VERSION "dbc-export 1 2026.26.6.5"

NS_ :

BS_:

BU_: ADSP APSB BB CMP DAS DPB EPAS3P EPASTP EPASTS GTW IDB OCS1P PTC RCM RCU TCU TCU2 UDS UI UIS VCLEFT VCSEAT2L VCSEAT2R

BO_ 293 UI_alertMatrix3: 8 UI
 SG_ UI_a129_dgpuOperationFailure : 0|1@1+ (1,0) [0|1] "" Vector__XXX
 SG_ UI_a130_QtCarClusterExitError : 1|1@1+ (1,0) [0|1] "" Vector__XXX
 SG_ UI_a131_DisplayPortFailure : 2|1@1+ (1,0) [0|1] "" Vector__XXX
 SG_ UI_a132_AdspWatchdogRecoveryTrig : 3|1@1+ (1,0) [0|1] "" Vector__XXX
 SG_ UI_a133_AdspWatchdogRecoveryFail : 4|1@1+ (1,0) [0|1] "" Vector__XXX
 SG_ UI_a134_DashcamUsbDriveNoMedium : 5|1@1+ (1,0) [0|1] "" Vector__XXX
 SG_ UI_a135_warnRunOverlayExists : 6|1@1+ (1,0) [0|1] "" Vector__XXX
 SG_ UI_a136_warnSettingsConfExists : 7|1@1+ (1,0) [0|1] "" Vector__XXX
 SG_ UI_a137_ServiceShellActiveConnec : 8|1@1+ (1,0) [0|1] "" Vector__XXX
 SG_ UI_a138_applyingConfigChange : 9|1@1+ (1,0) [0|1] "" Vector__XXX
 SG_ UI_a139_postponedConfigChange : 10|1@1+ (1,0) [0|1] "" Vector__XXX
 SG_ UI_a140_NeverSleepActive : 11|1@1+ (1,0) [0|1] "" Vector__XXX
 SG_ UI_a141_falconDoorOpen : 12|1@1+ (1,0) [0|1] "" Vector__XXX
 SG_ UI_a142_CorrectableMemoryError : 13|1@1+ (1,0) [0|1] "" Vector__XXX
 SG_ UI_a143_FPSCrawling : 14|1@1+ (1,0) [0|1] "" Vector__XXX
 SG_ UI_a144_nvmeWarning : 15|1@1+ (1,0) [0|1] "" Vector__XXX
 SG_ UI_a145_nvmeUnsafeShutdown : 16|1@1+ (1,0) [0|1] "" Vector__XXX
 SG_ UI_a146_nvmeNeedsReplacement : 17|1@1+ (1,0) [0|1] "" Vector__XXX
 SG_ UI_a147_ASILGlobalError : 18|1@1+ (1,0) [0|1] "" Vector__XXX
 SG_ UI_a148_SleepFailure : 19|1@1+ (1,0) [0|1] "" Vector__XXX
 SG_ UI_a149_DisplayCheckFailure : 20|1@1+ (1,0) [0|1] "" Vector__XXX
 SG_ UI_a150_infoCPURunningHot : 21|1@1+ (1,0) [0|1] "" Vector__XXX
 SG_ UI_a151_carComputerThermalProble : 22|1@1+ (1,0) [0|1] "" Vector__XXX
 SG_ UI_a152_infoThrottling : 23|1@1+ (1,0) [0|1] "" Vector__XXX
 SG_ UI_a153_serviceRestarted : 24|1@1+ (1,0) [0|1] "" Vector__XXX
 SG_ UI_a154_AudiodBufferError : 25|1@1+ (1,0) [0|1] "" Vector__XXX
 SG_ UI_a155_UsbFrontHubUnavailable : 26|1@1+ (1,0) [0|1] "" Vector__XXX
 SG_ UI_a156_UsbFrontHubInstallMismat : 27|1@1+ (1,0) [0|1] "" Vector__XXX
 SG_ UI_a157_MCUActiveCoolingRequeste : 28|1@1+ (1,0) [0|1] "" Vector__XXX
 SG_ UI_a158_UsbDeviceMountError : 29|1@1+ (1,0) [0|1] "" Vector__XXX
 SG_ UI_a159_AudioHeartbeatFailure : 30|1@1+ (1,0) [0|1] "" Vector__XXX
 SG_ UI_a160_SystemWatchdogFailure : 31|1@1+ (1,0) [0|1] "" Vector__XXX
 SG_ UI_a161_ECallTemporarilyUnavaila : 32|1@1+ (1,0) [0|1] "" Vector__XXX
 SG_ UI_a162_voiceRecClipsUploaded : 33|1@1+ (1,0) [0|1] "" Vector__XXX
 SG_ UI_a163_QtCarVehicleExitError : 34|1@1+ (1,0) [0|1] "" Vector__XXX
 SG_ UI_a164_AudiodConnTimeout : 35|1@1+ (1,0) [0|1] "" Vector__XXX
 SG_ UI_a165_fsCorrupted : 36|1@1+ (1,0) [0|1] "" Vector__XXX
 SG_ UI_a166_fsError : 37|1@1+ (1,0) [0|1] "" Vector__XXX
 SG_ UI_a167_CgroupOverMemKill : 38|1@1+ (1,0) [0|1] "" Vector__XXX
 SG_ UI_a168_dgpuPowerOnSelfTestFailu : 39|1@1+ (1,0) [0|1] "" Vector__XXX
 SG_ UI_a169_SteamLoadShedFailure : 40|1@1+ (1,0) [0|1] "" Vector__XXX
 SG_ UI_a170_AMDdGPULoadShedFailure : 41|1@1+ (1,0) [0|1] "" Vector__XXX
 SG_ UI_a171_GraphicsLoadShedRequeste : 42|1@1+ (1,0) [0|1] "" Vector__XXX
 SG_ UI_a172_GraphicsLoadShedUIFailur : 43|1@1+ (1,0) [0|1] "" Vector__XXX
 SG_ UI_a173_pmSuspendFailure : 44|1@1+ (1,0) [0|1] "" Vector__XXX
 SG_ UI_a174_HistorySaveLoop : 45|1@1+ (1,0) [0|1] "" Vector__XXX
 SG_ UI_a176_CellularAntennaAlert : 47|1@1+ (1,0) [0|1] "" Vector__XXX
 SG_ UI_a177_MediaPlayerFailure : 48|1@1+ (1,0) [0|1] "" Vector__XXX
 SG_ UI_a178_irqDisabled : 49|1@1+ (1,0) [0|1] "" Vector__XXX
 SG_ UI_a180_AudiodInputRestarted : 51|1@1+ (1,0) [0|1] "" Vector__XXX
 SG_ UI_a181_ModemFirmwareVersionMism : 52|1@1+ (1,0) [0|1] "" Vector__XXX
 SG_ UI_a182_VideoPipelineOverrun : 53|1@1+ (1,0) [0|1] "" Vector__XXX
 SG_ UI_a183_DDAWFaulted : 54|1@1+ (1,0) [0|1] "" Vector__XXX
 SG_ UI_a184_ISAFaulted : 55|1@1+ (1,0) [0|1] "" Vector__XXX
 SG_ UI_a185_ELKSDisabled : 56|1@1+ (1,0) [0|1] "" Vector__XXX
 SG_ UI_a186_ELKSUnavailable : 57|1@1+ (1,0) [0|1] "" Vector__XXX
 SG_ UI_a187_TunerFirmwareMismatchedV : 58|1@1+ (1,0) [0|1] "" Vector__XXX
 SG_ UI_a188_TunerFirmwareMismatchedA : 59|1@1+ (1,0) [0|1] "" Vector__XXX
 SG_ UI_a189_TunerWatchdogReset : 60|1@1+ (1,0) [0|1] "" Vector__XXX
 SG_ UI_a190_TunerMIA : 61|1@1+ (1,0) [0|1] "" Vector__XXX
 SG_ UI_a191_TunerUpdateFailed : 62|1@1+ (1,0) [0|1] "" Vector__XXX
 SG_ UI_a192_AudioWatchdogReboot : 63|1@1+ (1,0) [0|1] "" Vector__XXX

BO_ 294 UI_alertMatrix4: 8 UI
 SG_ UI_a193_TcuRNandFwVersionMismatc : 0|1@1+ (1,0) [0|1] "" Vector__XXX
 SG_ UI_a194_AudioweaverRestarted : 1|1@1+ (1,0) [0|1] "" Vector__XXX
 SG_ UI_a195_gtwMfdUdpApiFired : 2|1@1+ (1,0) [0|1] "" Vector__XXX
 SG_ UI_a196_AMDI2C3BusInoperable : 3|1@1+ (1,0) [0|1] "" Vector__XXX
 SG_ UI_a197_AMDI2C1BusInoperable : 4|1@1+ (1,0) [0|1] "" Vector__XXX
 SG_ UI_a198_IncompatibleBTUSBHubHard : 5|1@1+ (1,0) [0|1] "" Vector__XXX
 SG_ UI_a199_HighAPedalDetectedAtColl : 6|1@1+ (1,0) [0|1] "" Vector__XXX
 SG_ UI_a200_UIFirmwareVersionMismatc : 7|1@1+ (1,0) [0|1] "" Vector__XXX
 SG_ UI_a201_rearDisplayDisconnected : 8|1@1+ (1,0) [0|1] "" Vector__XXX
 SG_ UI_a202_sysMemoryIncorrect : 9|1@1+ (1,0) [0|1] "" Vector__XXX
 SG_ UI_a204_ModemSleepFailure : 11|1@1+ (1,0) [0|1] "" Vector__XXX
 SG_ UI_a205_ModemSleepSignalMismatch : 12|1@1+ (1,0) [0|1] "" Vector__XXX
 SG_ UI_a206_ModemMIAAfterWake : 13|1@1+ (1,0) [0|1] "" Vector__XXX
 SG_ UI_a208_mqttClientDisconnected : 15|1@1+ (1,0) [0|1] "" Vector__XXX
 SG_ UI_a209_dataCallDisconnected : 16|1@1+ (1,0) [0|1] "" Vector__XXX
 SG_ UI_a210_CellularCSRegFail : 17|1@1+ (1,0) [0|1] "" Vector__XXX
 SG_ UI_a211_AEBSDisabled : 18|1@1+ (1,0) [0|1] "" Vector__XXX
 SG_ UI_a212_AEBSFaulted : 19|1@1+ (1,0) [0|1] "" Vector__XXX
 SG_ UI_a213_ISADisabled : 20|1@1+ (1,0) [0|1] "" Vector__XXX
 SG_ UI_a214_pmHelperFailure : 21|1@1+ (1,0) [0|1] "" Vector__XXX
 SG_ UI_a215_compositorStallDetected : 22|1@1+ (1,0) [0|1] "" Vector__XXX
 SG_ UI_a216_AudioA2bCircuitProblem : 23|1@1+ (1,0) [0|1] "" Vector__XXX
 SG_ UI_a217_CgroupMemoryPressure : 24|1@1+ (1,0) [0|1] "" Vector__XXX
 SG_ UI_a218_AudiodNoAudioDevices : 25|1@1+ (1,0) [0|1] "" Vector__XXX
 SG_ UI_a219_CompositorWatchdog : 26|1@1+ (1,0) [0|1] "" Vector__XXX
 SG_ UI_a220_MediaBrowseError : 27|1@1+ (1,0) [0|1] "" Vector__XXX
 SG_ UI_a221_NavigationServiceError : 28|1@1+ (1,0) [0|1] "" Vector__XXX
 SG_ UI_a222_QtCarRestart : 29|1@1+ (1,0) [0|1] "" Vector__XXX
 SG_ UI_a223_databaseError : 30|1@1+ (1,0) [0|1] "" Vector__XXX
 SG_ UI_a224_centerDisplayDisconnecte : 31|1@1+ (1,0) [0|1] "" Vector__XXX
 SG_ UI_a225_clusterDisplayDisconnect : 32|1@1+ (1,0) [0|1] "" Vector__XXX
 SG_ UI_a226_largePhoneContactSync : 33|1@1+ (1,0) [0|1] "" Vector__XXX
 SG_ UI_a228_pipewireXrunBurst : 35|1@1+ (1,0) [0|1] "" Vector__XXX
 SG_ UI_a229_SerDesError : 36|1@1+ (1,0) [0|1] "" Vector__XXX
 SG_ UI_a230_ModemSimCardMismatch : 37|1@1+ (1,0) [0|1] "" Vector__XXX
 SG_ UI_a231_SleepCancelled : 38|1@1+ (1,0) [0|1] "" Vector__XXX
 SG_ UI_a232_processExitError : 39|1@1+ (1,0) [0|1] "" Vector__XXX
 SG_ UI_a233_ModemRFFailure : 40|1@1+ (1,0) [0|1] "" Vector__XXX
 SG_ UI_a234_AMDI2C0Timeout : 41|1@1+ (1,0) [0|1] "" Vector__XXX
 SG_ UI_a235_AMDI2C1Timeout : 42|1@1+ (1,0) [0|1] "" Vector__XXX
 SG_ UI_a236_ModemOnResetState : 43|1@1+ (1,0) [0|1] "" Vector__XXX
 SG_ UI_a237_ClipUploadActive : 44|1@1+ (1,0) [0|1] "" Vector__XXX
 SG_ UI_a238_ModemConfigMismatch : 45|1@1+ (1,0) [0|1] "" Vector__XXX
 SG_ UI_a240_ethError : 47|1@1+ (1,0) [0|1] "" Vector__XXX
 SG_ UI_a241_AxCPError : 48|1@1+ (1,0) [0|1] "" Vector__XXX
 SG_ UI_a242_uiHealthFaultInjectionAc : 49|1@1+ (1,0) [0|1] "" Vector__XXX
 SG_ UI_a243_pmDisplayCheckFailure : 50|1@1+ (1,0) [0|1] "" Vector__XXX
 SG_ UI_a244_segfault : 51|1@1+ (1,0) [0|1] "" Vector__XXX
 SG_ UI_a245_taskHung : 52|1@1+ (1,0) [0|1] "" Vector__XXX
 SG_ UI_a246_gpuFenceTimeout : 53|1@1+ (1,0) [0|1] "" Vector__XXX
 SG_ UI_a247_StalklessDisplayBackligh : 54|1@1+ (1,0) [0|1] "" Vector__XXX
 SG_ UI_a252_TPMErrorReceive : 59|1@1+ (1,0) [0|1] "" Vector__XXX
 SG_ UI_a253_maintenanceHistoryRecord : 60|1@1+ (1,0) [0|1] "" Vector__XXX
 SG_ UI_a254_appCertificateExpired : 61|1@1+ (1,0) [0|1] "" Vector__XXX
 SG_ UI_a255_apbCertificateExpired : 62|1@1+ (1,0) [0|1] "" Vector__XXX
 SG_ UI_a256_sapFailedToEnable : 63|1@1+ (1,0) [0|1] "" Vector__XXX

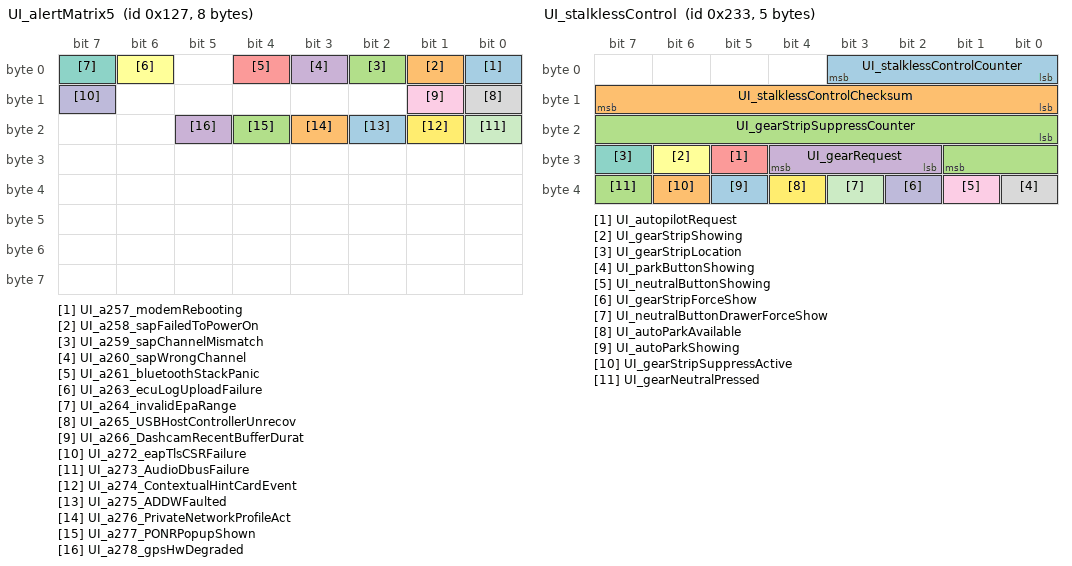
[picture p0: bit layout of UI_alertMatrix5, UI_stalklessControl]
BO_ 295 UI_alertMatrix5: 8 UI
 SG_ UI_a257_modemRebooting : 0|1@1+ (1,0) [0|1] "" Vector__XXX
 SG_ UI_a258_sapFailedToPowerOn : 1|1@1+ (1,0) [0|1] "" Vector__XXX
 SG_ UI_a259_sapChannelMismatch : 2|1@1+ (1,0) [0|1] "" Vector__XXX
 SG_ UI_a260_sapWrongChannel : 3|1@1+ (1,0) [0|1] "" Vector__XXX
 SG_ UI_a261_bluetoothStackPanic : 4|1@1+ (1,0) [0|1] "" Vector__XXX
 SG_ UI_a263_ecuLogUploadFailure : 6|1@1+ (1,0) [0|1] "" Vector__XXX
 SG_ UI_a264_invalidEpaRange : 7|1@1+ (1,0) [0|1] "" Vector__XXX
 SG_ UI_a265_USBHostControllerUnrecov : 8|1@1+ (1,0) [0|1] "" Vector__XXX
 SG_ UI_a266_DashcamRecentBufferDurat : 9|1@1+ (1,0) [0|1] "" Vector__XXX
 SG_ UI_a272_eapTlsCSRFailure : 15|1@1+ (1,0) [0|1] "" Vector__XXX
 SG_ UI_a273_AudioDbusFailure : 16|1@1+ (1,0) [0|1] "" Vector__XXX
 SG_ UI_a274_ContextualHintCardEvent : 17|1@1+ (1,0) [0|1] "" Vector__XXX
 SG_ UI_a275_ADDWFaulted : 18|1@1+ (1,0) [0|1] "" Vector__XXX
 SG_ UI_a276_PrivateNetworkProfileAct : 19|1@1+ (1,0) [0|1] "" Vector__XXX
 SG_ UI_a277_PONRPopupShown : 20|1@1+ (1,0) [0|1] "" Vector__XXX
 SG_ UI_a278_gpsHwDegraded : 21|1@1+ (1,0) [0|1] "" Vector__XXX

BO_ 1279 UI_energyConsumptionInfo: 8 UI
 SG_ UI_energyConsumptionInfoIndex M : 0|5@1+ (1,0) [0|31] "" Vector__XXX
 SG_ UI_energyLossTotal_epa m0 : 16|16@1- (1,0) [-32768|32767] "Wh" Vector__XXX
 SG_ UI_energyLossDriving_epa m0 : 32|16@1- (1,0) [-32768|32767] "Wh" Vector__XXX
 SG_ UI_energyLossClimate_epa m0 : 48|16@1- (1,0) [-32768|32767] "Wh" Vector__XXX
 SG_ UI_energyLossBattCond_epa m1 : 16|16@1- (1,0) [-32768|32767] "Wh" Vector__XXX
 SG_ UI_energyLossElevation_epa m1 : 32|16@1- (1,0) [-32768|32767] "Wh" Vector__XXX
 SG_ UI_energyLossAcc_epa m1 : 48|16@1- (1,0) [-32768|32767] "Wh" Vector__XXX
 SG_ UI_energyLossTotalSinceCharge_ep m2 : 16|16@1- (1,0) [-32768|32767] "Wh" Vector__XXX
 SG_ UI_energyLossDrivingSinceCharge_ m2 : 32|16@1- (1,0) [-32768|32767] "Wh" Vector__XXX
 SG_ UI_energyLossClimateSinceCharge_ m2 : 48|16@1- (1,0) [-32768|32767] "Wh" Vector__XXX
 SG_ UI_energyLossBattCondSinceCharge m3 : 16|16@1- (1,0) [-32768|32767] "Wh" Vector__XXX
 SG_ UI_energyLossElevationSinceCharg m3 : 32|16@1- (1,0) [-32768|32767] "Wh" Vector__XXX
 SG_ UI_energyLossAccSinceCharge_epa m3 : 48|16@1- (1,0) [-32768|32767] "Wh" Vector__XXX
 SG_ UI_energyLossTotalSinceTripStart m4 : 16|16@1- (1,0) [-32768|32767] "Wh" Vector__XXX
 SG_ UI_energyLossDrivingSinceTripSta m4 : 32|16@1- (1,0) [-32768|32767] "Wh" Vector__XXX
 SG_ UI_energyLossClimateSinceTripSta m4 : 48|16@1- (1,0) [-32768|32767] "Wh" Vector__XXX
 SG_ UI_energyLossBattCondSinceTripSt m5 : 16|16@1- (1,0) [-32768|32767] "Wh" Vector__XXX
 SG_ UI_energyLossElevationSinceTripS m5 : 32|16@1- (1,0) [-32768|32767] "Wh" Vector__XXX
 SG_ UI_energyLossAccSinceTripStart m5 : 48|16@1- (1,0) [-32768|32767] "Wh" Vector__XXX
 SG_ UI_energyDeltaTotal_epa m6 : 16|16@1- (1,0) [-32768|32767] "Wh" Vector__XXX
 SG_ UI_energyDeltaDriving_epa m6 : 32|16@1- (1,0) [-32768|32767] "Wh" Vector__XXX
 SG_ UI_energyDeltaClimate_epa m6 : 48|16@1- (1,0) [-32768|32767] "Wh" Vector__XXX
 SG_ UI_energyDeltaBattCond_epa m7 : 16|16@1- (1,0) [-32768|32767] "Wh" Vector__XXX
 SG_ UI_energyDeltaElevation_epa m7 : 32|16@1- (1,0) [-32768|32767] "Wh" Vector__XXX
 SG_ UI_energyDeltaAcc_epa m7 : 48|16@1- (1,0) [-32768|32767] "Wh" Vector__XXX
 SG_ UI_uiDeltaOffsetTotal_epa m8 : 16|16@1- (1,0) [-32768|32767] "Wh" Vector__XXX
 SG_ UI_uiDeltaOffsetDriving_epa m8 : 32|16@1- (1,0) [-32768|32767] "Wh" Vector__XXX
 SG_ UI_uiDeltaOffsetClimate_epa m8 : 48|16@1- (1,0) [-32768|32767] "Wh" Vector__XXX
 SG_ UI_uiDeltaOffsetBattCond_epa m9 : 16|16@1- (1,0) [-32768|32767] "Wh" Vector__XXX
 SG_ UI_uiDeltaOffsetElevation_epa m9 : 32|16@1- (1,0) [-32768|32767] "Wh" Vector__XXX
 SG_ UI_uiDeltaOffsetAcc_epa m9 : 48|16@1- (1,0) [-32768|32767] "Wh" Vector__XXX
 SG_ UI_rawToUiEnergyRatio_epa m10 : 8|8@1+ (0.01,0) [0|2.55] "-" Vector__XXX
 SG_ UI_driveDistance_epa m10 : 16|16@1+ (0.01,0) [0|655.35] "miles" Vector__XXX
 SG_ UI_energyDeltaTotalSinceCharge_e m11 : 16|16@1- (1,0) [-32768|32767] "Wh" Vector__XXX
 SG_ UI_energyDeltaDrivingSinceCharge m11 : 32|16@1- (1,0) [-32768|32767] "Wh" Vector__XXX
 SG_ UI_energyDeltaClimateSinceCharge m11 : 48|16@1- (1,0) [-32768|32767] "Wh" Vector__XXX
 SG_ UI_energyDeltaBattCondSinceCharg m12 : 16|16@1- (1,0) [-32768|32767] "Wh" Vector__XXX
 SG_ UI_energyDeltaElevationSinceChar m12 : 32|16@1- (1,0) [-32768|32767] "Wh" Vector__XXX
 SG_ UI_energyDeltaAccSinceCharge_epa m12 : 48|16@1- (1,0) [-32768|32767] "Wh" Vector__XXX
 SG_ UI_uiDeltaOffsetTotalSinceCharge m13 : 16|16@1- (1,0) [-32768|32767] "Wh" Vector__XXX
 SG_ UI_uiDeltaOffsetDrivingSinceChar m13 : 32|16@1- (1,0) [-32768|32767] "Wh" Vector__XXX
 SG_ UI_uiDeltaOffsetClimateSinceChar m13 : 48|16@1- (1,0) [-32768|32767] "Wh" Vector__XXX
 SG_ UI_uiDeltaOffsetBattCondSinceCha m14 : 16|16@1- (1,0) [-32768|32767] "Wh" Vector__XXX
 SG_ UI_uiDeltaOffsetElevationSinceCh m14 : 32|16@1- (1,0) [-32768|32767] "Wh" Vector__XXX
 SG_ UI_uiDeltaOffsetAccSinceCharge_e m14 : 48|16@1- (1,0) [-32768|32767] "Wh" Vector__XXX
 SG_ UI_rawToUiEnergyRatioSinceCharge m15 : 8|8@1+ (0.01,0) [0|2.55] "-" Vector__XXX
 SG_ UI_driveDistanceSinceCharge_epa m15 : 16|16@1+ (0.01,0) [0|655.35] "miles" Vector__XXX
 SG_ UI_energyDeltaTotalSinceTripStar m16 : 16|16@1- (1,0) [-32768|32767] "Wh" Vector__XXX
 SG_ UI_energyDeltaDrivingSinceTripSt m16 : 32|16@1- (1,0) [-32768|32767] "Wh" Vector__XXX
 SG_ UI_energyDeltaClimateSinceTripSt m16 : 48|16@1- (1,0) [-32768|32767] "Wh" Vector__XXX
 SG_ UI_energyDeltaBattCondSinceTripS m17 : 16|16@1- (1,0) [-32768|32767] "Wh" Vector__XXX
 SG_ UI_energyDeltaElevationSinceTrip m17 : 32|16@1- (1,0) [-32768|32767] "Wh" Vector__XXX
 SG_ UI_energyDeltaAccSinceTripStart m17 : 48|16@1- (1,0) [-32768|32767] "Wh" Vector__XXX
 SG_ UI_uiDeltaOffsetTotalSinceTripSt m18 : 16|16@1- (1,0) [-32768|32767] "Wh" Vector__XXX
 SG_ UI_uiDeltaOffsetDrivingSinceTrip m18 : 32|16@1- (1,0) [-32768|32767] "Wh" Vector__XXX
 SG_ UI_uiDeltaOffsetClimateSinceTrip m18 : 48|16@1- (1,0) [-32768|32767] "Wh" Vector__XXX
 SG_ UI_uiDeltaOffsetBattCondSinceTri m19 : 16|16@1- (1,0) [-32768|32767] "Wh" Vector__XXX
 SG_ UI_uiDeltaOffsetElevationSinceTr m19 : 32|16@1- (1,0) [-32768|32767] "Wh" Vector__XXX
 SG_ UI_uiDeltaOffsetAccSinceTripStar m19 : 48|16@1- (1,0) [-32768|32767] "Wh" Vector__XXX
 SG_ UI_rawToUiEnergyRatioSinceTripSt m20 : 8|8@1+ (0.01,0) [0|2.55] "-" Vector__XXX
 SG_ UI_driveDistanceSinceTripStart m20 : 16|16@1+ (0.01,0) [0|655.35] "miles" Vector__XXX
 SG_ UI_voyagerEnabled m21 : 5|1@1+ (1,0) [0|1] "" Vector__XXX
 SG_ UI_trailerMass m21 : 16|16@1+ (1,0) [0|65535] "kg" Vector__XXX

BO_ 993 UI_gearSliderInfo: 8 UI
 SG_ UI_gearSliderInfoIndex M : 0|2@1+ (1,0) [0|3] "" Vector__XXX
 SG_ UI_gearSliderW m0 : 2|14@1+ (1,0) [0|16383] "" Vector__XXX
 SG_ UI_gearSliderH m0 : 16|16@1+ (1,0) [0|65535] "" Vector__XXX
 SG_ UI_gearSliderX m0 : 32|16@1+ (1,0) [0|65535] "" Vector__XXX
 SG_ UI_gearSliderY m0 : 48|16@1+ (1,0) [0|65535] "" Vector__XXX
 SG_ UI_gearParkW m1 : 2|14@1+ (1,0) [0|16383] "" Vector__XXX
 SG_ UI_gearParkH m1 : 16|16@1+ (1,0) [0|65535] "" Vector__XXX
 SG_ UI_gearParkX m1 : 32|16@1+ (1,0) [0|65535] "" Vector__XXX
 SG_ UI_gearParkY m1 : 48|16@1+ (1,0) [0|65535] "" Vector__XXX
 SG_ UI_gearNeutralW m2 : 2|14@1+ (1,0) [0|16383] "" Vector__XXX
 SG_ UI_gearNeutralH m2 : 16|16@1+ (1,0) [0|65535] "" Vector__XXX
 SG_ UI_gearNeutralX m2 : 32|16@1+ (1,0) [0|65535] "" Vector__XXX
 SG_ UI_gearNeutralY m2 : 48|16@1+ (1,0) [0|65535] "" Vector__XXX

BO_ 666 UI_seatControl: 3 UI
 SG_ UI_seatControlIndex M : 0|2@1+ (1,0) [0|3] "" Vector__XXX
 SG_ UI_3RSeatChildLock m0 : 2|2@1+ (1,0) [0|3] "" Vector__XXX
 SG_ UI_2RowLeftSeatTrackBack m0 : 4|1@1+ (1,0) [0|1] "" Vector__XXX
 SG_ UI_2RowLeftSeatTrackForward m0 : 5|1@1+ (1,0) [0|1] "" Vector__XXX
 SG_ UI_2RowRightSeatTrackBack m0 : 6|1@1+ (1,0) [0|1] "" Vector__XXX
 SG_ UI_2RowRightSeatTrackForward m0 : 7|1@1+ (1,0) [0|1] "" Vector__XXX
 SG_ UI_left3RowSeatAdjustmentRequest m0 : 8|3@1+ (1,0) [0|7] "" Vector__XXX
 SG_ UI_right3RowSeatAdjustmentReques m0 : 11|3@1+ (1,0) [0|7] "" Vector__XXX
 SG_ UI_2RLeftSeatFanReq m0 : 14|2@1+ (1,0) [0|3] "" Vector__XXX
 SG_ UI_2RRightSeatFanReq m0 : 16|2@1+ (1,0) [0|3] "" Vector__XXX
 SG_ UI_leftThirdRowSeatRequestFromRe m0 : 18|1@1+ (1,0) [0|1] "" Vector__XXX
 SG_ UI_rightThirdRowSeatRequestFromR m0 : 19|1@1+ (1,0) [0|1] "" Vector__XXX
 SG_ UI_seatChoreographyStopRequest m0 : 20|1@1+ (1,0) [0|1] "" Vector__XXX

BO_ 563 UI_stalklessControl: 5 UI
 SG_ UI_stalklessControlCounter : 0|4@1+ (1,0) [0|15] "" Vector__XXX
 SG_ UI_stalklessControlChecksum : 8|8@1+ (1,0) [0|255] "" Vector__XXX
 SG_ UI_gearStripSuppressCounter : 16|10@1+ (1,0) [0|1023] "" Vector__XXX
 SG_ UI_gearRequest : 26|3@1+ (1,0) [1|7] "" Vector__XXX
 SG_ UI_autopilotRequest : 29|1@1+ (1,0) [0|1] "" Vector__XXX
 SG_ UI_gearStripShowing : 30|1@1+ (1,0) [0|1] "" Vector__XXX
 SG_ UI_gearStripLocation : 31|1@1+ (1,0) [0|1] "" Vector__XXX
 SG_ UI_parkButtonShowing : 32|1@1+ (1,0) [0|1] "" Vector__XXX
 SG_ UI_neutralButtonShowing : 33|1@1+ (1,0) [0|1] "" Vector__XXX
 SG_ UI_gearStripForceShow : 34|1@1+ (1,0) [0|1] "" Vector__XXX
 SG_ UI_neutralButtonDrawerForceShow : 35|1@1+ (1,0) [0|1] "" Vector__XXX
 SG_ UI_autoParkAvailable : 36|1@1+ (1,0) [0|1] "" Vector__XXX
 SG_ UI_autoParkShowing : 37|1@1+ (1,0) [0|1] "" Vector__XXX
 SG_ UI_gearStripSuppressActive : 38|1@1+ (1,0) [0|1] "" Vector__XXX
 SG_ UI_gearNeutralPressed : 39|1@1+ (1,0) [0|1] "" Vector__XXX

BO_ 986 UI_status3: 1 UI
 SG_ UI_wifiRegDomain : 0|7@1+ (1,0) [0|127] "" Vector__XXX
 SG_ UI_wifiTethered : 7|1@1+ (1,0) [0|1] "" Vector__XXX

BO_ 661 UI_systemMonitor: 8 UI
 SG_ UI_systemMonitorIndex M : 0|1@1+ (1,0) [0|1] "" Vector__XXX
 SG_ UI_SystemMemUsage m0 : 8|16@1+ (1,0) [0|65535] "MB" Vector__XXX
 SG_ UI_QtCarMemUsage m0 : 24|16@1+ (1,0) [0|65535] "MB" Vector__XXX
 SG_ UI_QtCarCPUUsage m0 : 40|7@1+ (1,0) [0|127] "%" Vector__XXX
 SG_ UI_emmcStatus m0 : 47|1@1+ (1,0) [0|1] "" Vector__XXX
 SG_ UI_SystemCPUUsage m0 : 48|7@1+ (1,0) [0|127] "%" Vector__XXX
 SG_ UI_HomeHealth m0 : 55|1@1+ (1,0) [0|1] "" Vector__XXX
 SG_ UI_VarHealth m0 : 56|1@1+ (1,0) [0|1] "" Vector__XXX
 SG_ UI_LogHealth m0 : 57|1@1+ (1,0) [0|1] "" Vector__XXX
 SG_ UI_TmpfsHealth m0 : 58|1@1+ (1,0) [0|1] "" Vector__XXX
 SG_ UI_emmcDataWritten m1 : 8|24@1+ (1,0) [0|16777215] "" Vector__XXX
 SG_ UI_emmcTotalErases m1 : 32|16@1+ (1,0) [0|65535] "" Vector__XXX

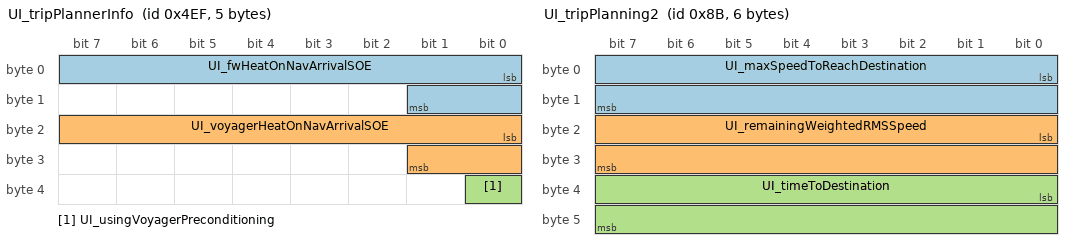
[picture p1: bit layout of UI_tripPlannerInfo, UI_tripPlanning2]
BO_ 1263 UI_tripPlannerInfo: 5 UI
 SG_ UI_fwHeatOnNavArrivalSOE : 0|10@1+ (0.1,0) [0|100] "%" Vector__XXX
 SG_ UI_voyagerHeatOnNavArrivalSOE : 16|10@1+ (0.1,0) [0|100] "%" Vector__XXX
 SG_ UI_usingVoyagerPreconditioning : 32|1@1+ (1,0) [0|1] "" Vector__XXX

BO_ 139 UI_tripPlanning2: 6 UI
 SG_ UI_maxSpeedToReachDestination : 0|16@1+ (0.01,0) [0|655.34] "m/s" Vector__XXX
 SG_ UI_remainingWeightedRMSSpeed : 16|16@1+ (0.01,0) [0|655.34] "m/s" Vector__XXX
 SG_ UI_timeToDestination : 32|16@1+ (1,0) [0|65534] "s" Vector__XXX

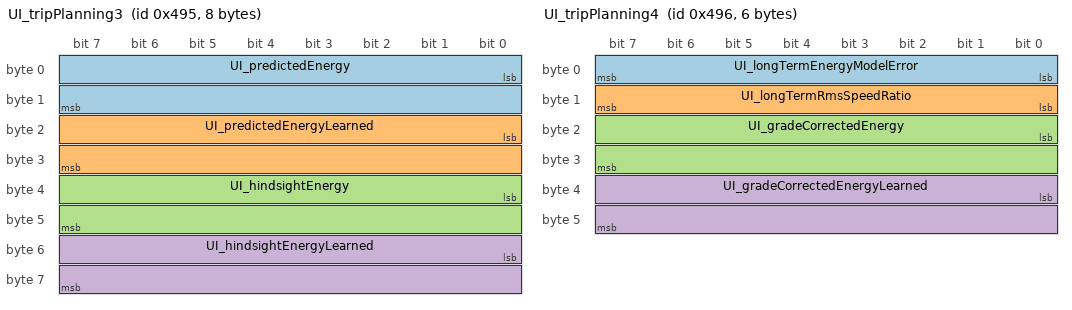
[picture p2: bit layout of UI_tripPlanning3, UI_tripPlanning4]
BO_ 1173 UI_tripPlanning3: 8 UI
 SG_ UI_predictedEnergy : 0|16@1- (0.01,0) [-327.67|327.67] "kWh" Vector__XXX
 SG_ UI_predictedEnergyLearned : 16|16@1- (0.01,0) [-327.68|327.67] "kWh" Vector__XXX
 SG_ UI_hindsightEnergy : 32|16@1- (0.01,0) [-327.67|327.67] "kWh" Vector__XXX
 SG_ UI_hindsightEnergyLearned : 48|16@1- (0.01,0) [-327.68|327.67] "kWh" Vector__XXX

BO_ 1174 UI_tripPlanning4: 6 UI
 SG_ UI_longTermEnergyModelError : 0|8@1- (0.5,0) [-64|63.5] "whpm" Vector__XXX
 SG_ UI_longTermRmsSpeedRatio : 8|8@1+ (0.01,0) [0|2.54] "1" Vector__XXX
 SG_ UI_gradeCorrectedEnergy : 16|16@1- (0.01,0) [-327.68|327.67] "kWh" Vector__XXX
 SG_ UI_gradeCorrectedEnergyLearned : 32|16@1- (0.01,0) [-327.68|327.67] "kWh" Vector__XXX

BO_ 1175 UI_tripPlanning5: 4 UI
 SG_ UI_battPreconditionOnNavTime : 0|16@1+ (1,0) [0|65534] "s" Vector__XXX
 SG_ UI_maxBattPreconditionOnNavTime : 16|16@1+ (1,0) [0|65534] "s" Vector__XXX

BO_ 649 VCLEFT_logging10Hz: 8 VCLEFT
 SG_ VCLEFT_logging10HzIndex M : 0|1@1+ (1,0) [0|1] "" Vector__XXX
 SG_ VCLEFT_hvacBlowerRs m0 : 1|8@1+ (0.25,0) [0|60] "mOhm" Vector__XXX
 SG_ VCLEFT_hvacBlowerIPhase0 m0 : 9|7@1+ (0.4,0) [0|50] "A" Vector__XXX
 SG_ VCLEFT_hvacBlowerIPhase1 m0 : 16|7@1+ (0.4,0) [0|50] "A" Vector__XXX
 SG_ VCLEFT_hvacBlowerIPhase2 m0 : 23|7@1+ (0.4,0) [0|50] "A" Vector__XXX
 SG_ VCLEFT_hvacBlower_IO_CBC_HEAD m0 : 30|4@1+ (1,0) [0|15] "" Vector__XXX
 SG_ VCLEFT_hvacBlower_IO_CBC_TAIL m0 : 34|4@1+ (1,0) [0|15] "" Vector__XXX
 SG_ VCLEFT_hvacBlower_IO_CBC_TAIL_va m0 : 38|1@1+ (1,0) [0|1] "" Vector__XXX
 SG_ VCLEFT_hvacBlower_IO_CBC_Status m0 : 39|1@1+ (1,0) [0|1] "" Vector__XXX
 SG_ VCLEFT_hvacBlower_IO_CBC_numUart m0 : 40|8@1+ (1,0) [0|255] "" Vector__XXX
 SG_ VCLEFT_hvacBlowerCBCEstState m0 : 48|4@1+ (1,0) [0|15] "" Vector__XXX
 SG_ VCLEFT_hvacBlowerCBCCtrlState m0 : 52|3@1+ (1,0) [0|7] "" Vector__XXX
 SG_ VCLEFT_hvacBlowerITerm m0 : 55|7@1+ (0.05,-1.5) [-1.5|4.5] "Nm" Vector__XXX
 SG_ VCLEFT_hvacBlowerSpiError m0 : 62|1@1+ (1,0) [0|1] "" Vector__XXX
 SG_ VCLEFT_hvacBlowerRsOnlineActive m0 : 63|1@1+ (1,0) [0|1] "" Vector__XXX

BO_ 1336 VCSEAT2L_alertLog: 8 VCSEAT2L
 SG_ VCSEAT2L_alertID M : 0|15@1+ (1,0) [0|32767] "" Vector__XXX
 SG_ VCSEAT2L_alertState : 15|1@1+ (1,0) [0|1] "" Vector__XXX
 SG_ VCSEAT2L_a001_InternalWatchdog m1 : 16|1@1+ (1,0) [0|1] "" Vector__XXX
 SG_ VCSEAT2L_a010_UnderVoltDetected m10 : 16|1@1+ (1,0) [0|1] "" Vector__XXX
 SG_ VCSEAT2L_a010_UnderVoltTimeout m10 : 17|1@1+ (1,0) [0|1] "" Vector__XXX
 SG_ VCSEAT2L_a015_NVMMMemOverflow m15 : 16|1@1+ (1,0) [0|1] "" Vector__XXX
 SG_ VCSEAT2L_a015_NVMMFilesystemErro m15 : 17|1@1+ (1,0) [0|1] "" Vector__XXX
 SG_ VCSEAT2L_a015_NVMMRecordIDError m15 : 18|1@1+ (1,0) [0|1] "" Vector__XXX
 SG_ VCSEAT2L_a057_VEH_cpControl m57 : 16|1@1+ (1,0) [0|1] "" Vector__XXX
 SG_ VCSEAT2L_a059_voltageDrop m59 : 16|12@1+ (0.005443676,0) [0|22.29185322] "V" Vector__XXX
 SG_ VCSEAT2L_a059_resistanceEstimate m59 : 28|12@1+ (0.00244,0) [0|9.9918] "Ohms" Vector__XXX
 SG_ VCSEAT2L_a059_current m59 : 40|12@1+ (0.05,0) [0|204.75] "A" Vector__XXX
 SG_ VCSEAT2L_a063_switchChannel m63 : 16|8@1+ (1,0) [0|255] "" Vector__XXX
 SG_ VCSEAT2L_a063_switchType m63 : 24|8@1+ (1,0) [0|255] "" Vector__XXX
 SG_ VCSEAT2L_a063_ADCVoltage m63 : 32|8@1+ (0.025,0) [0|6.375] "V" Vector__XXX
 SG_ VCSEAT2L_a063_disconnected m63 : 40|1@1+ (1,0) [0|1] "" Vector__XXX
 SG_ VCSEAT2L_a063_indeterminate m63 : 41|1@1+ (1,0) [0|1] "" Vector__XXX
 SG_ VCSEAT2L_a063_stuckActive m63 : 42|1@1+ (1,0) [0|1] "" Vector__XXX
 SG_ VCSEAT2L_a063_faulted m63 : 43|1@1+ (1,0) [0|1] "" Vector__XXX
 SG_ VCSEAT2L_a082_RIPC_epbPrivateSta m82 : 16|1@1+ (1,0) [0|1] "" Vector__XXX
 SG_ VCSEAT2L_a082_RIPC_remoteHSD m82 : 17|1@1+ (1,0) [0|1] "" Vector__XXX
 SG_ VCSEAT2L_a082_RIPC_railStatus m82 : 18|1@1+ (1,0) [0|1] "" Vector__XXX
 SG_ VCSEAT2L_a082_RIPC_remoteMux m82 : 19|1@1+ (1,0) [0|1] "" Vector__XXX
 SG_ VCSEAT2L_a083_LIPC_epbPrivateSta m83 : 16|1@1+ (1,0) [0|1] "" Vector__XXX
 SG_ VCSEAT2L_a083_LIPC_remoteHSD m83 : 17|1@1+ (1,0) [0|1] "" Vector__XXX
 SG_ VCSEAT2L_a083_LIPC_railStatus m83 : 18|1@1+ (1,0) [0|1] "" Vector__XXX
 SG_ VCSEAT2L_a083_LIPC_HSDFaults m83 : 19|1@1+ (1,0) [0|1] "" Vector__XXX
 SG_ VCSEAT2L_a084_CH_StatusC m84 : 16|1@1+ (1,0) [0|1] "" Vector__XXX
 SG_ VCSEAT2L_a085_PARTY_buttonStatus m85 : 16|1@1+ (1,0) [0|1] "" Vector__XXX
 SG_ VCSEAT2L_a086_VEH_LVBMS_statusHi m86 : 16|1@1+ (1,0) [0|1] "" Vector__XXX
 SG_ VCSEAT2L_a086_VEH_LVBMS_statusLo m86 : 17|1@1+ (1,0) [0|1] "" Vector__XXX
 SG_ VCSEAT2L_a086_VEH_status m86 : 18|1@1+ (1,0) [0|1] "" Vector__XXX
 SG_ VCSEAT2L_a086_VEH_12VBatteryStat m86 : 19|1@1+ (1,0) [0|1] "" Vector__XXX
 SG_ VCSEAT2L_a086_VEH_LVPowerState m86 : 20|1@1+ (1,0) [0|1] "" Vector__XXX
 SG_ VCSEAT2L_a086_VEH_lightStatus m86 : 21|1@1+ (1,0) [0|1] "" Vector__XXX
 SG_ VCSEAT2L_a086_VEH_systemStatus m86 : 22|1@1+ (1,0) [0|1] "" Vector__XXX
 SG_ VCSEAT2L_a086_VEH_thermalStatus m86 : 23|1@1+ (1,0) [0|1] "" Vector__XXX
 SG_ VCSEAT2L_a086_VEH_vehNm m86 : 24|1@1+ (1,0) [0|1] "" Vector__XXX
 SG_ VCSEAT2L_a087_VEH_temperature m87 : 16|1@1+ (1,0) [0|1] "" Vector__XXX
 SG_ VCSEAT2L_a087_VEH_thermalControl m87 : 17|1@1+ (1,0) [0|1] "" Vector__XXX
 SG_ VCSEAT2L_a087_VEH_torque m87 : 18|1@1+ (1,0) [0|1] "" Vector__XXX
 SG_ VCSEAT2L_a087_VEH_status m87 : 19|1@1+ (1,0) [0|1] "" Vector__XXX
 SG_ VCSEAT2L_a087_PARTY_torque m87 : 20|1@1+ (1,0) [0|1] "" Vector__XXX
 SG_ VCSEAT2L_a087_PARTY_status m87 : 21|1@1+ (1,0) [0|1] "" Vector__XXX
 SG_ VCSEAT2L_a087_PARTY_temperature m87 : 22|1@1+ (1,0) [0|1] "" Vector__XXX
 SG_ VCSEAT2L_a087_PARTY_thermalContr m87 : 23|1@1+ (1,0) [0|1] "" Vector__XXX
 SG_ VCSEAT2L_a087_VEH_motorStatus m87 : 24|1@1+ (1,0) [0|1] "" Vector__XXX
 SG_ VCSEAT2L_a088_VEH_temperature m88 : 16|1@1+ (1,0) [0|1] "" Vector__XXX
 SG_ VCSEAT2L_a088_VEH_thermalControl m88 : 17|1@1+ (1,0) [0|1] "" Vector__XXX
 SG_ VCSEAT2L_a088_VEH_torque m88 : 18|1@1+ (1,0) [0|1] "" Vector__XXX
 SG_ VCSEAT2L_a088_VEH_status m88 : 19|1@1+ (1,0) [0|1] "" Vector__XXX
 SG_ VCSEAT2L_a088_PARTY_torque m88 : 20|1@1+ (1,0) [0|1] "" Vector__XXX
 SG_ VCSEAT2L_a088_PARTY_status m88 : 21|1@1+ (1,0) [0|1] "" Vector__XXX
 SG_ VCSEAT2L_a088_PARTY_temperature m88 : 22|1@1+ (1,0) [0|1] "" Vector__XXX
 SG_ VCSEAT2L_a088_PARTY_thermalContr m88 : 23|1@1+ (1,0) [0|1] "" Vector__XXX
 SG_ VCSEAT2L_a088_VEH_motorStatus m88 : 24|1@1+ (1,0) [0|1] "" Vector__XXX
 SG_ VCSEAT2L_a089_PARTY_party1 m89 : 16|1@1+ (1,0) [0|1] "" Vector__XXX
 SG_ VCSEAT2L_a089_PARTY_status m89 : 17|1@1+ (1,0) [0|1] "" Vector__XXX
 SG_ VCSEAT2L_a089_VEH_status m89 : 18|1@1+ (1,0) [0|1] "" Vector__XXX
 SG_ VCSEAT2L_a089_BDY_party1 m89 : 19|1@1+ (1,0) [0|1] "" Vector__XXX
 SG_ VCSEAT2L_a089_BDY_status m89 : 20|1@1+ (1,0) [0|1] "" Vector__XXX
 SG_ VCSEAT2L_a089_CH_status m89 : 21|1@1+ (1,0) [0|1] "" Vector__XXX
 SG_ VCSEAT2L_a089_CH_party1 m89 : 22|1@1+ (1,0) [0|1] "" Vector__XXX
 SG_ VCSEAT2L_a089_CH_party3 m89 : 23|1@1+ (1,0) [0|1] "" Vector__XXX
 SG_ VCSEAT2L_a089_VEH_party1 m89 : 24|1@1+ (1,0) [0|1] "" Vector__XXX
 SG_ VCSEAT2L_a089_VEH_party3 m89 : 25|1@1+ (1,0) [0|1] "" Vector__XXX
 SG_ VCSEAT2L_a091_VEH_faultsAndExtra m91 : 16|1@1+ (1,0) [0|1] "" Vector__XXX
 SG_ VCSEAT2L_a091_VEH_info m91 : 17|1@1+ (1,0) [0|1] "" Vector__XXX
 SG_ VCSEAT2L_a091_VEH_state m91 : 18|1@1+ (1,0) [0|1] "" Vector__XXX
 SG_ VCSEAT2L_a092_VEH_restraintStatu m92 : 16|1@1+ (1,0) [0|1] "" Vector__XXX
 SG_ VCSEAT2L_a092_VEH_switchStatus m92 : 17|1@1+ (1,0) [0|1] "" Vector__XXX
 SG_ VCSEAT2L_a092_VEH_seatStatus2 m92 : 18|1@1+ (1,0) [0|1] "" Vector__XXX
 SG_ VCSEAT2L_a092_VEH_vehNm m92 : 19|1@1+ (1,0) [0|1] "" Vector__XXX
 SG_ VCSEAT2L_a093_VEH_restraintStatu m93 : 16|1@1+ (1,0) [0|1] "" Vector__XXX
 SG_ VCSEAT2L_a093_VEH_switchStatus m93 : 17|1@1+ (1,0) [0|1] "" Vector__XXX
 SG_ VCSEAT2L_a093_VEH_seatStatus2 m93 : 18|1@1+ (1,0) [0|1] "" Vector__XXX
 SG_ VCSEAT2L_a093_VEH_vehNm m93 : 19|1@1+ (1,0) [0|1] "" Vector__XXX
 SG_ VCSEAT2L_a094_VEH_sysStatus m94 : 16|1@1+ (1,0) [0|1] "" Vector__XXX
 SG_ VCSEAT2L_a094_PARTY_sysStatus m94 : 17|1@1+ (1,0) [0|1] "" Vector__XXX
 SG_ VCSEAT2L_a094_CH_sysStatus m94 : 18|1@1+ (1,0) [0|1] "" Vector__XXX
 SG_ VCSEAT2L_a095_PT_ptNm m95 : 16|1@1+ (1,0) [0|1] "" Vector__XXX
 SG_ VCSEAT2L_a095_PT_status m95 : 17|1@1+ (1,0) [0|1] "" Vector__XXX
 SG_ VCSEAT2L_a096_VEH_status m96 : 16|1@1+ (1,0) [0|1] "" Vector__XXX
 SG_ VCSEAT2L_a096_CH_status m96 : 17|1@1+ (1,0) [0|1] "" Vector__XXX
 SG_ VCSEAT2L_a097_VEH_HVStatus m97 : 16|1@1+ (1,0) [0|1] "" Vector__XXX
 SG_ VCSEAT2L_a097_VEH_state m97 : 17|1@1+ (1,0) [0|1] "" Vector__XXX
 SG_ VCSEAT2L_a098_CH_torque m98 : 16|1@1+ (1,0) [0|1] "" Vector__XXX
 SG_ VCSEAT2L_a098_VEH_hvStatus m98 : 17|1@1+ (1,0) [0|1] "" Vector__XXX
 SG_ VCSEAT2L_a098_VEH_status m98 : 18|1@1+ (1,0) [0|1] "" Vector__XXX
 SG_ VCSEAT2L_a098_VEH_thermalControl m98 : 19|1@1+ (1,0) [0|1] "" Vector__XXX
 SG_ VCSEAT2L_a098_VEH_temperature m98 : 20|1@1+ (1,0) [0|1] "" Vector__XXX
 SG_ VCSEAT2L_a098_VEH_torque m98 : 21|1@1+ (1,0) [0|1] "" Vector__XXX
 SG_ VCSEAT2L_a098_PARTY_status m98 : 22|1@1+ (1,0) [0|1] "" Vector__XXX
 SG_ VCSEAT2L_a098_PARTY_temperature m98 : 23|1@1+ (1,0) [0|1] "" Vector__XXX
 SG_ VCSEAT2L_a098_PARTY_thermalContr m98 : 24|1@1+ (1,0) [0|1] "" Vector__XXX
 SG_ VCSEAT2L_a098_PARTY_torque m98 : 25|1@1+ (1,0) [0|1] "" Vector__XXX
 SG_ VCSEAT2L_a098_PT_thermalControl m98 : 26|1@1+ (1,0) [0|1] "" Vector__XXX
 SG_ VCSEAT2L_a098_PT_temperature m98 : 27|1@1+ (1,0) [0|1] "" Vector__XXX
 SG_ VCSEAT2L_a098_PARTY_motorStatus m98 : 28|1@1+ (1,0) [0|1] "" Vector__XXX
 SG_ VCSEAT2L_a098_VEH_motorStatus m98 : 29|1@1+ (1,0) [0|1] "" Vector__XXX
 SG_ VCSEAT2L_a099_VEH_oocStatus m99 : 16|1@1+ (1,0) [0|1] "" Vector__XXX
 SG_ VCSEAT2L_a100_VEH m100 : 16|1@1+ (1,0) [0|1] "" Vector__XXX
 SG_ VCSEAT2L_a100_PARTY m100 : 17|1@1+ (1,0) [0|1] "" Vector__XXX
 SG_ VCSEAT2L_a100_PT m100 : 18|1@1+ (1,0) [0|1] "" Vector__XXX
 SG_ VCSEAT2L_a100_CH m100 : 19|1@1+ (1,0) [0|1] "" Vector__XXX
 SG_ VCSEAT2L_a100_OBD m100 : 20|1@1+ (1,0) [0|1] "" Vector__XXX
 SG_ VCSEAT2L_a101_VEH_state m101 : 16|1@1+ (1,0) [0|1] "" Vector__XXX
 SG_ VCSEAT2L_a101_PARTY_locState m101 : 17|1@1+ (1,0) [0|1] "" Vector__XXX
 SG_ VCSEAT2L_a101_LIPC_externalWatch m101 : 18|1@1+ (1,0) [0|1] "" Vector__XXX
 SG_ VCSEAT2L_a101_VEH_locState m101 : 19|1@1+ (1,0) [0|1] "" Vector__XXX
 SG_ VCSEAT2L_a101_BDY_locState m101 : 20|1@1+ (1,0) [0|1] "" Vector__XXX
 SG_ VCSEAT2L_a102_VEH_faultsAndExtra m102 : 16|1@1+ (1,0) [0|1] "" Vector__XXX
 SG_ VCSEAT2L_a102_VEH_feedbackStatus m102 : 17|1@1+ (1,0) [0|1] "" Vector__XXX
 SG_ VCSEAT2L_a102_VEH_sensorStatus m102 : 18|1@1+ (1,0) [0|1] "" Vector__XXX
 SG_ VCSEAT2L_a102_VEH_rods m102 : 19|1@1+ (1,0) [0|1] "" Vector__XXX
 SG_ VCSEAT2L_a103_VEH_hvsNm m103 : 16|1@1+ (1,0) [0|1] "" Vector__XXX
 SG_ VCSEAT2L_a103_VEH_vehNm m103 : 17|1@1+ (1,0) [0|1] "" Vector__XXX
 SG_ VCSEAT2L_a103_VEH_status m103 : 18|1@1+ (1,0) [0|1] "" Vector__XXX
 SG_ VCSEAT2L_a103_PT_ptNm m103 : 19|1@1+ (1,0) [0|1] "" Vector__XXX
 SG_ VCSEAT2L_a103_PT_status m103 : 20|1@1+ (1,0) [0|1] "" Vector__XXX
 SG_ VCSEAT2L_a103_VEH_evseStatus m103 : 21|1@1+ (1,0) [0|1] "" Vector__XXX
 SG_ VCSEAT2L_a105_VEH_states m105 : 16|1@1+ (1,0) [0|1] "" Vector__XXX
 SG_ VCSEAT2L_a105_VEH_chNm m105 : 17|1@1+ (1,0) [0|1] "" Vector__XXX
 SG_ VCSEAT2L_a105_VEH_dampingStates m105 : 18|1@1+ (1,0) [0|1] "" Vector__XXX
 SG_ VCSEAT2L_a106_VEH_dcdcStatus m106 : 16|1@1+ (1,0) [0|1] "" Vector__XXX
 SG_ VCSEAT2L_a106_VEH_thermalControl m106 : 17|1@1+ (1,0) [0|1] "" Vector__XXX
 SG_ VCSEAT2L_a106_VEH_dcdcRailStatus m106 : 18|1@1+ (1,0) [0|1] "" Vector__XXX
 SG_ VCSEAT2L_a106_CH_dcdcRailStatus m106 : 19|1@1+ (1,0) [0|1] "" Vector__XXX
 SG_ VCSEAT2L_a106_CH_alertMatrix m106 : 20|1@1+ (1,0) [0|1] "" Vector__XXX
 SG_ VCSEAT2L_a107_VEH_hvsNm m107 : 16|1@1+ (1,0) [0|1] "" Vector__XXX
 SG_ VCSEAT2L_a107_VEH_vehNm m107 : 17|1@1+ (1,0) [0|1] "" Vector__XXX
 SG_ VCSEAT2L_a107_VEH_status m107 : 18|1@1+ (1,0) [0|1] "" Vector__XXX
 SG_ VCSEAT2L_a107_VEH_thermalStatus m107 : 19|1@1+ (1,0) [0|1] "" Vector__XXX
 SG_ VCSEAT2L_a107_VEH_bmbMinMax m107 : 20|1@1+ (1,0) [0|1] "" Vector__XXX
 SG_ VCSEAT2L_a107_VEH_powerAvailable m107 : 21|1@1+ (1,0) [0|1] "" Vector__XXX
 SG_ VCSEAT2L_a107_PT_ptNm m107 : 22|1@1+ (1,0) [0|1] "" Vector__XXX
 SG_ VCSEAT2L_a107_PT_status m107 : 23|1@1+ (1,0) [0|1] "" Vector__XXX
 SG_ VCSEAT2L_a107_PT_thermalStatus m107 : 24|1@1+ (1,0) [0|1] "" Vector__XXX
 SG_ VCSEAT2L_a107_PT_socStatus m107 : 25|1@1+ (1,0) [0|1] "" Vector__XXX
 SG_ VCSEAT2L_a107_VEH_socStatus m107 : 26|1@1+ (1,0) [0|1] "" Vector__XXX
 SG_ VCSEAT2L_a107_VEH_packConfig m107 : 27|1@1+ (1,0) [0|1] "" Vector__XXX
 SG_ VCSEAT2L_a107_VEH_energyStatus m107 : 28|1@1+ (1,0) [0|1] "" Vector__XXX
 SG_ VCSEAT2L_a107_VEH_chargeInfo m107 : 29|1@1+ (1,0) [0|1] "" Vector__XXX
 SG_ VCSEAT2L_a108_VEH_hvStatus m108 : 16|1@1+ (1,0) [0|1] "" Vector__XXX
 SG_ VCSEAT2L_a108_VEH_temperature m108 : 17|1@1+ (1,0) [0|1] "" Vector__XXX
 SG_ VCSEAT2L_a108_VEH_thermalControl m108 : 18|1@1+ (1,0) [0|1] "" Vector__XXX
 SG_ VCSEAT2L_a108_VEH_torque m108 : 19|1@1+ (1,0) [0|1] "" Vector__XXX
 SG_ VCSEAT2L_a108_VEH_status m108 : 20|1@1+ (1,0) [0|1] "" Vector__XXX
 SG_ VCSEAT2L_a108_PARTY_torque m108 : 21|1@1+ (1,0) [0|1] "" Vector__XXX
 SG_ VCSEAT2L_a108_PARTY_status m108 : 22|1@1+ (1,0) [0|1] "" Vector__XXX
 SG_ VCSEAT2L_a108_PARTY_temperature m108 : 23|1@1+ (1,0) [0|1] "" Vector__XXX
 SG_ VCSEAT2L_a108_PARTY_thermalContr m108 : 24|1@1+ (1,0) [0|1] "" Vector__XXX
 SG_ VCSEAT2L_a108_PT_temperature m108 : 25|1@1+ (1,0) [0|1] "" Vector__XXX
 SG_ VCSEAT2L_a108_PT_thermalControl m108 : 26|1@1+ (1,0) [0|1] "" Vector__XXX
 SG_ VCSEAT2L_a108_PARTY_motorStatus m108 : 27|1@1+ (1,0) [0|1] "" Vector__XXX
 SG_ VCSEAT2L_a108_VEH_motorStatus m108 : 28|1@1+ (1,0) [0|1] "" Vector__XXX
 SG_ VCSEAT2L_a108_CH_torque m108 : 29|1@1+ (1,0) [0|1] "" Vector__XXX
 SG_ VCSEAT2L_a110_VEH_carState m110 : 16|1@1+ (1,0) [0|1] "" Vector__XXX
 SG_ VCSEAT2L_a110_VEH_carConfig m110 : 17|1@1+ (1,0) [0|1] "" Vector__XXX
 SG_ VCSEAT2L_a110_VEH_time m110 : 18|1@1+ (1,0) [0|1] "" Vector__XXX
 SG_ VCSEAT2L_a110_VEH_updateStatus m110 : 19|1@1+ (1,0) [0|1] "" Vector__XXX
 SG_ VCSEAT2L_a110_VEH_vehNm m110 : 20|1@1+ (1,0) [0|1] "" Vector__XXX
 SG_ VCSEAT2L_a110_VEH_mismatchFault m110 : 21|1@1+ (1,0) [0|1] "" Vector__XXX
 SG_ VCSEAT2L_a110_VEH_vin m110 : 22|1@1+ (1,0) [0|1] "" Vector__XXX
 SG_ VCSEAT2L_a110_VEH_bmpDebug m110 : 23|1@1+ (1,0) [0|1] "" Vector__XXX
 SG_ VCSEAT2L_a110_VEH_gearControl m110 : 24|1@1+ (1,0) [0|1] "" Vector__XXX
 SG_ VCSEAT2L_a110_VEH_canLogAvailabi m110 : 25|1@1+ (1,0) [0|1] "" Vector__XXX
 SG_ VCSEAT2L_a110_CH_airbagCutoffSta m110 : 26|1@1+ (1,0) [0|1] "" Vector__XXX
 SG_ VCSEAT2L_a110_CH_carConfig m110 : 27|1@1+ (1,0) [0|1] "" Vector__XXX
 SG_ VCSEAT2L_a110_CH_carState m110 : 28|1@1+ (1,0) [0|1] "" Vector__XXX
 SG_ VCSEAT2L_a110_CH_vin m110 : 29|1@1+ (1,0) [0|1] "" Vector__XXX
 SG_ VCSEAT2L_a110_CH_chNm m110 : 30|1@1+ (1,0) [0|1] "" Vector__XXX
 SG_ VCSEAT2L_a110_CH_epochTimeGtw m110 : 31|1@1+ (1,0) [0|1] "" Vector__XXX
 SG_ VCSEAT2L_a110_PARTY_carConfig m110 : 32|1@1+ (1,0) [0|1] "" Vector__XXX
 SG_ VCSEAT2L_a111_VEH_internalStatus m111 : 16|1@1+ (1,0) [0|1] "" Vector__XXX
 SG_ VCSEAT2L_a111_VEH_status m111 : 17|1@1+ (1,0) [0|1] "" Vector__XXX
 SG_ VCSEAT2L_a111_VEH_vehNm m111 : 18|1@1+ (1,0) [0|1] "" Vector__XXX
 SG_ VCSEAT2L_a111_RIPC_LVPowerState m111 : 19|1@1+ (1,0) [0|1] "" Vector__XXX
 SG_ VCSEAT2L_a111_RIPC_epbPrivateSta m111 : 20|1@1+ (1,0) [0|1] "" Vector__XXX
 SG_ VCSEAT2L_a111_RIPC_railStatus m111 : 21|1@1+ (1,0) [0|1] "" Vector__XXX
 SG_ VCSEAT2L_a111_RIPC_remoteADC m111 : 22|1@1+ (1,0) [0|1] "" Vector__XXX
 SG_ VCSEAT2L_a111_RIPC_switchStatus m111 : 23|1@1+ (1,0) [0|1] "" Vector__XXX
 SG_ VCSEAT2L_a111_VEH_LVPowerState m111 : 24|1@1+ (1,0) [0|1] "" Vector__XXX
 SG_ VCSEAT2L_a111_VEH_seatStatus m111 : 25|1@1+ (1,0) [0|1] "" Vector__XXX
 SG_ VCSEAT2L_a111_PARTY_status m111 : 26|1@1+ (1,0) [0|1] "" Vector__XXX
 SG_ VCSEAT2L_a111_CH_status m111 : 27|1@1+ (1,0) [0|1] "" Vector__XXX
 SG_ VCSEAT2L_a112_VEH_internalStatus m112 : 16|1@1+ (1,0) [0|1] "" Vector__XXX
 SG_ VCSEAT2L_a112_VEH_status m112 : 17|1@1+ (1,0) [0|1] "" Vector__XXX
 SG_ VCSEAT2L_a112_VEH_vehNm m112 : 18|1@1+ (1,0) [0|1] "" Vector__XXX
 SG_ VCSEAT2L_a112_LIPC_LVPowerState m112 : 19|1@1+ (1,0) [0|1] "" Vector__XXX
 SG_ VCSEAT2L_a112_LIPC_epbPrivateSta m112 : 20|1@1+ (1,0) [0|1] "" Vector__XXX
 SG_ VCSEAT2L_a112_LIPC_railStatus m112 : 21|1@1+ (1,0) [0|1] "" Vector__XXX
 SG_ VCSEAT2L_a112_LIPC_remoteADC m112 : 22|1@1+ (1,0) [0|1] "" Vector__XXX
 SG_ VCSEAT2L_a112_LIPC_switchStatus m112 : 23|1@1+ (1,0) [0|1] "" Vector__XXX
 SG_ VCSEAT2L_a112_VEH_LVPowerState m112 : 24|1@1+ (1,0) [0|1] "" Vector__XXX
 SG_ VCSEAT2L_a112_PARTY_status m112 : 25|1@1+ (1,0) [0|1] "" Vector__XXX
 SG_ VCSEAT2L_a112_CH_status m112 : 26|1@1+ (1,0) [0|1] "" Vector__XXX
 SG_ VCSEAT2L_a114_PARTY_status m114 : 16|1@1+ (1,0) [0|1] "" Vector__XXX
 SG_ VCSEAT2L_a114_PARTY_wheelSpeeds m114 : 17|1@1+ (1,0) [0|1] "" Vector__XXX
 SG_ VCSEAT2L_a114_VEH_wheelSpeeds m114 : 18|1@1+ (1,0) [0|1] "" Vector__XXX
 SG_ VCSEAT2L_a114_CH_wheelSpeeds m114 : 19|1@1+ (1,0) [0|1] "" Vector__XXX
 SG_ VCSEAT2L_a114_PARTY_party3 m114 : 20|1@1+ (1,0) [0|1] "" Vector__XXX
 SG_ VCSEAT2L_a114_VEH_party3 m114 : 21|1@1+ (1,0) [0|1] "" Vector__XXX
 SG_ VCSEAT2L_a114_VEH_status m114 : 22|1@1+ (1,0) [0|1] "" Vector__XXX
 SG_ VCSEAT2L_a114_PARTY_wheelRotatio m114 : 23|1@1+ (1,0) [0|1] "" Vector__XXX
 SG_ VCSEAT2L_a114_CH_wheelRotation m114 : 24|1@1+ (1,0) [0|1] "" Vector__XXX
 SG_ VCSEAT2L_a114_VEH_wheelRotation m114 : 25|1@1+ (1,0) [0|1] "" Vector__XXX
 SG_ VCSEAT2L_a114_PARTY_brakeTorque m114 : 26|1@1+ (1,0) [0|1] "" Vector__XXX
 SG_ VCSEAT2L_a114_PARTY_offsets m114 : 27|1@1+ (1,0) [0|1] "" Vector__XXX
 SG_ VCSEAT2L_a114_BDY_offsets m114 : 28|1@1+ (1,0) [0|1] "" Vector__XXX
 SG_ VCSEAT2L_a114_BDY_party3 m114 : 29|1@1+ (1,0) [0|1] "" Vector__XXX
 SG_ VCSEAT2L_a114_BDY_status m114 : 30|1@1+ (1,0) [0|1] "" Vector__XXX
 SG_ VCSEAT2L_a114_BDY_wheelRotation m114 : 31|1@1+ (1,0) [0|1] "" Vector__XXX
 SG_ VCSEAT2L_a114_BDY_wheelSpeeds m114 : 32|1@1+ (1,0) [0|1] "" Vector__XXX
 SG_ VCSEAT2L_a114_CH_party1 m114 : 33|1@1+ (1,0) [0|1] "" Vector__XXX
 SG_ VCSEAT2L_a114_CH_party3 m114 : 34|1@1+ (1,0) [0|1] "" Vector__XXX
 SG_ VCSEAT2L_a114_CH_status m114 : 35|1@1+ (1,0) [0|1] "" Vector__XXX
 SG_ VCSEAT2L_a115_VEH_vehNm m115 : 16|1@1+ (1,0) [0|1] "" Vector__XXX
 SG_ VCSEAT2L_a115_VEH_authentication m115 : 17|1@1+ (1,0) [0|1] "" Vector__XXX
 SG_ VCSEAT2L_a115_VEH_BLEResetReques m115 : 18|1@1+ (1,0) [0|1] "" Vector__XXX
 SG_ VCSEAT2L_a115_VEH_requests m115 : 19|1@1+ (1,0) [0|1] "" Vector__XXX
 SG_ VCSEAT2L_a115_VEH_requests2 m115 : 20|1@1+ (1,0) [0|1] "" Vector__XXX
 SG_ VCSEAT2L_a115_REM_authentication m115 : 21|1@1+ (1,0) [0|1] "" Vector__XXX
 SG_ VCSEAT2L_a115_UI_corianderVehicl m115 : 22|1@1+ (1,0) [0|1] "" Vector__XXX
 SG_ VCSEAT2L_a115_CH_TPMSDisplay m115 : 23|1@1+ (1,0) [0|1] "" Vector__XXX
 SG_ VCSEAT2L_a116_PARTY_epbmStatus m116 : 16|1@1+ (1,0) [0|1] "" Vector__XXX
 SG_ VCSEAT2L_a116_VEH_vehNm m116 : 17|1@1+ (1,0) [0|1] "" Vector__XXX
 SG_ VCSEAT2L_a116_VEH_hvacRequest m116 : 18|1@1+ (1,0) [0|1] "" Vector__XXX
 SG_ VCSEAT2L_a116_VEH_hvacStatus m116 : 19|1@1+ (1,0) [0|1] "" Vector__XXX
 SG_ VCSEAT2L_a116_VEH_LVPowerState m116 : 20|1@1+ (1,0) [0|1] "" Vector__XXX
 SG_ VCSEAT2L_a116_VEH_lightStatus m116 : 21|1@1+ (1,0) [0|1] "" Vector__XXX
 SG_ VCSEAT2L_a116_VEH_seatStatus m116 : 22|1@1+ (1,0) [0|1] "" Vector__XXX
 SG_ VCSEAT2L_a116_VEH_thsStatus m116 : 23|1@1+ (1,0) [0|1] "" Vector__XXX
 SG_ VCSEAT2L_a116_VEH_doorStatus m116 : 24|1@1+ (1,0) [0|1] "" Vector__XXX
 SG_ VCSEAT2L_a116_VEH_seatHeatStatus m116 : 25|1@1+ (1,0) [0|1] "" Vector__XXX
 SG_ VCSEAT2L_a116_VEH_restraintStatu m116 : 26|1@1+ (1,0) [0|1] "" Vector__XXX
 SG_ VCSEAT2L_a116_VEH_switchStatus m116 : 27|1@1+ (1,0) [0|1] "" Vector__XXX
 SG_ VCSEAT2L_a116_VEH_logging1Hz m116 : 28|1@1+ (1,0) [0|1] "" Vector__XXX
 SG_ VCSEAT2L_a116_VEH_seatStatus2 m116 : 29|1@1+ (1,0) [0|1] "" Vector__XXX
 SG_ VCSEAT2L_a116_VEH_status m116 : 30|1@1+ (1,0) [0|1] "" Vector__XXX
 SG_ VCSEAT2L_a116_VEH_thermalCommand m116 : 31|1@1+ (1,0) [0|1] "" Vector__XXX
 SG_ VCSEAT2L_a116_VEH_windowStatus m116 : 32|1@1+ (1,0) [0|1] "" Vector__XXX
 SG_ VCSEAT2L_a116_PARTY_restraintSta m116 : 33|1@1+ (1,0) [0|1] "" Vector__XXX
 SG_ VCSEAT2L_a116_PARTY_doorStatus m116 : 34|1@1+ (1,0) [0|1] "" Vector__XXX
 SG_ VCSEAT2L_a116_BDY_epbmStatus m116 : 35|1@1+ (1,0) [0|1] "" Vector__XXX
 SG_ VCSEAT2L_a116_BDY_restraintStatu m116 : 36|1@1+ (1,0) [0|1] "" Vector__XXX
 SG_ VCSEAT2L_a116_BDY_switchStatus m116 : 37|1@1+ (1,0) [0|1] "" Vector__XXX
 SG_ VCSEAT2L_a117_BDY_epbmStatus m117 : 16|1@1+ (1,0) [0|1] "" Vector__XXX
 SG_ VCSEAT2L_a117_BDY_restraintStatu m117 : 17|1@1+ (1,0) [0|1] "" Vector__XXX
 SG_ VCSEAT2L_a117_VEH_prndStatus m117 : 18|1@1+ (1,0) [0|1] "" Vector__XXX
 SG_ VCSEAT2L_a117_PARTY_epbmStatus m117 : 19|1@1+ (1,0) [0|1] "" Vector__XXX
 SG_ VCSEAT2L_a117_VEH_vehNm m117 : 20|1@1+ (1,0) [0|1] "" Vector__XXX
 SG_ VCSEAT2L_a117_VEH_hvacBlowerFdb m117 : 21|1@1+ (1,0) [0|1] "" Vector__XXX
 SG_ VCSEAT2L_a117_VEH_LVPowerState m117 : 22|1@1+ (1,0) [0|1] "" Vector__XXX
 SG_ VCSEAT2L_a117_VEH_restraintStatu m117 : 23|1@1+ (1,0) [0|1] "" Vector__XXX
 SG_ VCSEAT2L_a117_VEH_lightStatus m117 : 24|1@1+ (1,0) [0|1] "" Vector__XXX
 SG_ VCSEAT2L_a117_VEH_seatStatus m117 : 25|1@1+ (1,0) [0|1] "" Vector__XXX
 SG_ VCSEAT2L_a117_BDY_falconSwitchSt m117 : 26|1@1+ (1,0) [0|1] "" Vector__XXX
 SG_ VCSEAT2L_a117_VEH_doorStatus m117 : 27|1@1+ (1,0) [0|1] "" Vector__XXX
 SG_ VCSEAT2L_a117_VEH_doorStatus2 m117 : 28|1@1+ (1,0) [0|1] "" Vector__XXX
 SG_ VCSEAT2L_a117_VEH_windowStatus m117 : 29|1@1+ (1,0) [0|1] "" Vector__XXX
 SG_ VCSEAT2L_a117_VEH_switchStatus m117 : 30|1@1+ (1,0) [0|1] "" Vector__XXX
 SG_ VCSEAT2L_a117_VEH_intrusionSenso m117 : 31|1@1+ (1,0) [0|1] "" Vector__XXX
 SG_ VCSEAT2L_a117_VEH_liftgateStatus m117 : 32|1@1+ (1,0) [0|1] "" Vector__XXX
 SG_ VCSEAT2L_a117_VEH_seatStatus2 m117 : 33|1@1+ (1,0) [0|1] "" Vector__XXX
 SG_ VCSEAT2L_a117_PARTY_restraintSta m117 : 34|1@1+ (1,0) [0|1] "" Vector__XXX
 SG_ VCSEAT2L_a117_VEH_thermalStatus m117 : 35|1@1+ (1,0) [0|1] "" Vector__XXX
 SG_ VCSEAT2L_a117_PARTY_doorStatus m117 : 36|1@1+ (1,0) [0|1] "" Vector__XXX
 SG_ VCSEAT2L_a117_VEH_status m117 : 37|1@1+ (1,0) [0|1] "" Vector__XXX
 SG_ VCSEAT2L_a117_PARTY_prndStatus m117 : 38|1@1+ (1,0) [0|1] "" Vector__XXX
 SG_ VCSEAT2L_a117_PARTY_lightingSeco m117 : 39|1@1+ (1,0) [0|1] "" Vector__XXX
 SG_ VCSEAT2L_a118_VEH_vehNm m118 : 16|1@1+ (1,0) [0|1] "" Vector__XXX
 SG_ VCSEAT2L_a118_VEH_lighting m118 : 17|1@1+ (1,0) [0|1] "" Vector__XXX
 SG_ VCSEAT2L_a118_VEH_sensors m118 : 18|1@1+ (1,0) [0|1] "" Vector__XXX
 SG_ VCSEAT2L_a118_VEH_status m118 : 19|1@1+ (1,0) [0|1] "" Vector__XXX
 SG_ VCSEAT2L_a118_VEH_okToUseHighPwr m118 : 20|1@1+ (1,0) [0|1] "" Vector__XXX
 SG_ VCSEAT2L_a118_VEH_LVPowerState m118 : 21|1@1+ (1,0) [0|1] "" Vector__XXX
 SG_ VCSEAT2L_a118_VEH_coolant m118 : 22|1@1+ (1,0) [0|1] "" Vector__XXX
 SG_ VCSEAT2L_a118_VEH_vehicleStatus m118 : 23|1@1+ (1,0) [0|1] "" Vector__XXX
 SG_ VCSEAT2L_a118_VEH_12VBatteryStat m118 : 24|1@1+ (1,0) [0|1] "" Vector__XXX
 SG_ VCSEAT2L_a118_VEH_systemStatus m118 : 25|1@1+ (1,0) [0|1] "" Vector__XXX
 SG_ VCSEAT2L_a118_PARTY_LVPowerState m118 : 26|1@1+ (1,0) [0|1] "" Vector__XXX
 SG_ VCSEAT2L_a118_PARTY_outputPowerS m118 : 27|1@1+ (1,0) [0|1] "" Vector__XXX
 SG_ VCSEAT2L_a118_PARTY_vehicleTime m118 : 28|1@1+ (1,0) [0|1] "" Vector__XXX
 SG_ VCSEAT2L_a118_VEH_thermalCommand m118 : 29|1@1+ (1,0) [0|1] "" Vector__XXX
 SG_ VCSEAT2L_a118_CH_LVPowerState m118 : 30|1@1+ (1,0) [0|1] "" Vector__XXX
 SG_ VCSEAT2L_a118_PARTY_sensors m118 : 31|1@1+ (1,0) [0|1] "" Vector__XXX
 SG_ VCSEAT2L_a118_CH_sensors m118 : 32|1@1+ (1,0) [0|1] "" Vector__XXX
 SG_ VCSEAT2L_a118_VEH_interNodeResis m118 : 33|1@1+ (1,0) [0|1] "" Vector__XXX
 SG_ VCSEAT2L_a118_CH_lighting m118 : 34|1@1+ (1,0) [0|1] "" Vector__XXX
 SG_ VCSEAT2L_a118_VEH_lightStatus m118 : 35|1@1+ (1,0) [0|1] "" Vector__XXX
 SG_ VCSEAT2L_a118_PARTY_vehNm m118 : 36|1@1+ (1,0) [0|1] "" Vector__XXX
 SG_ VCSEAT2L_a118_CH_12VBatteryStatu m118 : 37|1@1+ (1,0) [0|1] "" Vector__XXX
 SG_ VCSEAT2L_a118_CH_LVBMS_statusHig m118 : 38|1@1+ (1,0) [0|1] "" Vector__XXX
 SG_ VCSEAT2L_a118_CH_alertMatrix m118 : 39|1@1+ (1,0) [0|1] "" Vector__XXX
 SG_ VCSEAT2L_a118_BDY_outputPowerSta m118 : 40|1@1+ (1,0) [0|1] "" Vector__XXX
 SG_ VCSEAT2L_a118_BDY_vehicleTime m118 : 41|1@1+ (1,0) [0|1] "" Vector__XXX
 SG_ VCSEAT2L_a118_PARTY_AP_vehicleSt m118 : 42|1@1+ (1,0) [0|1] "" Vector__XXX
 SG_ VCSEAT2L_a118_BDY_AP_vehicleStat m118 : 43|1@1+ (1,0) [0|1] "" Vector__XXX
 SG_ VCSEAT2L_a118_PARTY_VCFRONT_came m118 : 44|1@1+ (1,0) [0|1] "" Vector__XXX
 SG_ VCSEAT2L_a119_VEH_steerAngle m119 : 16|1@1+ (1,0) [0|1] "" Vector__XXX
 SG_ VCSEAT2L_a119_VEH_leftStalk m119 : 17|1@1+ (1,0) [0|1] "" Vector__XXX
 SG_ VCSEAT2L_a119_VEH_rightStalk m119 : 18|1@1+ (1,0) [0|1] "" Vector__XXX
 SG_ VCSEAT2L_a119_PARTY_rightStalk m119 : 19|1@1+ (1,0) [0|1] "" Vector__XXX
 SG_ VCSEAT2L_a119_CH_steerAngle m119 : 20|1@1+ (1,0) [0|1] "" Vector__XXX
 SG_ VCSEAT2L_a119_PARTY_steerAngle m119 : 21|1@1+ (1,0) [0|1] "" Vector__XXX
 SG_ VCSEAT2L_a120_PARTY_chassisCntl m120 : 16|1@1+ (1,0) [0|1] "" Vector__XXX
 SG_ VCSEAT2L_a120_VEH_systemStatus m120 : 17|1@1+ (1,0) [0|1] "" Vector__XXX
 SG_ VCSEAT2L_a120_CH_chassisCntl m120 : 18|1@1+ (1,0) [0|1] "" Vector__XXX
 SG_ VCSEAT2L_a120_PARTY_systemStatus m120 : 19|1@1+ (1,0) [0|1] "" Vector__XXX
 SG_ VCSEAT2L_a120_PARTY_torque m120 : 20|1@1+ (1,0) [0|1] "" Vector__XXX
 SG_ VCSEAT2L_a120_VEH_torque m120 : 21|1@1+ (1,0) [0|1] "" Vector__XXX
 SG_ VCSEAT2L_a120_PARTY_locStatus m120 : 22|1@1+ (1,0) [0|1] "" Vector__XXX
 SG_ VCSEAT2L_a120_PARTY_speed m120 : 23|1@1+ (1,0) [0|1] "" Vector__XXX
 SG_ VCSEAT2L_a120_VEH_speed m120 : 24|1@1+ (1,0) [0|1] "" Vector__XXX
 SG_ VCSEAT2L_a120_PARTY_status m120 : 25|1@1+ (1,0) [0|1] "" Vector__XXX
 SG_ VCSEAT2L_a120_PT_speed m120 : 26|1@1+ (1,0) [0|1] "" Vector__XXX
 SG_ VCSEAT2L_a120_PT_systemStatus m120 : 27|1@1+ (1,0) [0|1] "" Vector__XXX
 SG_ VCSEAT2L_a120_PARTY_vehicleEstim m120 : 28|1@1+ (1,0) [0|1] "" Vector__XXX
 SG_ VCSEAT2L_a120_VEH_aggregatedAxle m120 : 29|1@1+ (1,0) [0|1] "" Vector__XXX
 SG_ VCSEAT2L_a120_PARTY_aggregatedAx m120 : 30|1@1+ (1,0) [0|1] "" Vector__XXX
 SG_ VCSEAT2L_a120_VEH_systemPower m120 : 31|1@1+ (1,0) [0|1] "" Vector__XXX
 SG_ VCSEAT2L_a120_PARTY_autonomyHeal m120 : 32|1@1+ (1,0) [0|1] "" Vector__XXX
 SG_ VCSEAT2L_a120_VEH_autonomyHealth m120 : 33|1@1+ (1,0) [0|1] "" Vector__XXX
 SG_ VCSEAT2L_a120_PT_systemPower m120 : 34|1@1+ (1,0) [0|1] "" Vector__XXX
 SG_ VCSEAT2L_a120_PARTY_stalklessInt m120 : 35|1@1+ (1,0) [0|1] "" Vector__XXX
 SG_ VCSEAT2L_a120_CH_speed m120 : 36|1@1+ (1,0) [0|1] "" Vector__XXX
 SG_ VCSEAT2L_a120_VEH_estimatedBrake m120 : 37|1@1+ (1,0) [0|1] "" Vector__XXX
 SG_ VCSEAT2L_a120_PARTY_prndControl m120 : 38|1@1+ (1,0) [0|1] "" Vector__XXX
 SG_ VCSEAT2L_a120_PARTY_locStatus2 m120 : 39|1@1+ (1,0) [0|1] "" Vector__XXX
 SG_ VCSEAT2L_a120_VEH_chassisCntl m120 : 40|1@1+ (1,0) [0|1] "" Vector__XXX
 SG_ VCSEAT2L_a120_CH_locStatus2 m120 : 41|1@1+ (1,0) [0|1] "" Vector__XXX
 SG_ VCSEAT2L_a120_VEH_locStatus m120 : 42|1@1+ (1,0) [0|1] "" Vector__XXX
 SG_ VCSEAT2L_a120_VEH_locStatus2 m120 : 43|1@1+ (1,0) [0|1] "" Vector__XXX
 SG_ VCSEAT2L_a120_VEH_prndControl m120 : 44|1@1+ (1,0) [0|1] "" Vector__XXX
 SG_ VCSEAT2L_a120_VEH_vehicleEstimat m120 : 45|1@1+ (1,0) [0|1] "" Vector__XXX
 SG_ VCSEAT2L_a120_PARTY_motorStatus m120 : 46|1@1+ (1,0) [0|1] "" Vector__XXX
 SG_ VCSEAT2L_a120_VEH_motorStatus m120 : 47|1@1+ (1,0) [0|1] "" Vector__XXX
 SG_ VCSEAT2L_a120_BDY_speed m120 : 48|1@1+ (1,0) [0|1] "" Vector__XXX
 SG_ VCSEAT2L_a210_seatMotorCalibrate m210 : 16|1@1+ (1,0) [0|1] "" Vector__XXX
 SG_ VCSEAT2L_a210_seatMotorCurrent m210 : 17|12@1- (0.01,0) [-20.48|20.47] "A" Vector__XXX
 SG_ VCSEAT2L_a210_seatMotorState m210 : 29|3@1+ (1,0) [0|7] "" Vector__XXX
 SG_ VCSEAT2L_a210_seatSwitchBack m210 : 32|2@1+ (1,0) [1|3] "" Vector__XXX
 SG_ VCSEAT2L_a210_seatSwitchForward m210 : 34|2@1+ (1,0) [1|3] "" Vector__XXX
 SG_ VCSEAT2L_a211_seatMotorCurrent m211 : 16|12@1- (0.01,0) [-20.48|20.47] "A" Vector__XXX
 SG_ VCSEAT2L_a211_seatMotorPosReal m211 : 28|12@1- (1,0) [-2048|2047] "mm" Vector__XXX
 SG_ VCSEAT2L_a211_seatMotorState m211 : 40|3@1+ (1,0) [0|7] "" Vector__XXX
 SG_ VCSEAT2L_a211_seatSwitchBack m211 : 43|2@1+ (1,0) [1|3] "" Vector__XXX
 SG_ VCSEAT2L_a211_seatSwitchForward m211 : 45|2@1+ (1,0) [1|3] "" Vector__XXX
 SG_ VCSEAT2L_a212_seatMotorCurrent m212 : 16|12@1- (0.01,0) [-20.48|20.47] "A" Vector__XXX
 SG_ VCSEAT2L_a212_seatMotorPosReal m212 : 28|12@1- (1,0) [-2048|2047] "mm" Vector__XXX
 SG_ VCSEAT2L_a212_seatMotorState m212 : 40|3@1+ (1,0) [0|7] "" Vector__XXX
 SG_ VCSEAT2L_a212_seatSwitchBack m212 : 43|2@1+ (1,0) [1|3] "" Vector__XXX
 SG_ VCSEAT2L_a212_seatSwitchForward m212 : 45|2@1+ (1,0) [1|3] "" Vector__XXX
 SG_ VCSEAT2L_a213_seatMotorCalibrate m213 : 16|1@1+ (1,0) [0|1] "" Vector__XXX
 SG_ VCSEAT2L_a213_seatMotorCurrent m213 : 17|12@1- (0.01,0) [-20.48|20.47] "A" Vector__XXX
 SG_ VCSEAT2L_a213_seatMotorPosReal m213 : 32|12@1- (1,0) [-2048|2047] "mm" Vector__XXX
 SG_ VCSEAT2L_a213_seatMotorState m213 : 44|3@1+ (1,0) [0|7] "" Vector__XXX
 SG_ VCSEAT2L_a213_seatSwitchBack m213 : 48|2@1+ (1,0) [1|3] "" Vector__XXX
 SG_ VCSEAT2L_a213_seatSwitchForward m213 : 50|2@1+ (1,0) [1|3] "" Vector__XXX
 SG_ VCSEAT2L_a214_seatMotorCurrent m214 : 16|12@1- (0.01,0) [-20.48|20.47] "A" Vector__XXX
 SG_ VCSEAT2L_a214_seatMotorDCurrent m214 : 28|12@1- (0.01,0) [-20.48|20.47] "A" Vector__XXX
 SG_ VCSEAT2L_a214_seatMotorPosReal m214 : 40|12@1- (1,0) [-2048|2047] "mm" Vector__XXX
 SG_ VCSEAT2L_a214_seatMotorState m214 : 52|3@1+ (1,0) [0|7] "" Vector__XXX
 SG_ VCSEAT2L_a215_seatMotorCurrent m215 : 16|12@1- (0.01,0) [-20.48|20.47] "A" Vector__XXX
 SG_ VCSEAT2L_a215_seatMotorDCurrent m215 : 28|12@1- (0.01,0) [-20.48|20.47] "A" Vector__XXX
 SG_ VCSEAT2L_a215_seatMotorPosReal m215 : 40|12@1- (1,0) [-2048|2047] "mm" Vector__XXX
 SG_ VCSEAT2L_a215_seatMotorState m215 : 52|3@1+ (1,0) [0|7] "" Vector__XXX
 SG_ VCSEAT2L_a224_seatMotorCalibrate m224 : 16|1@1+ (1,0) [0|1] "" Vector__XXX
 SG_ VCSEAT2L_a224_seatMotorCurrent m224 : 17|12@1- (0.01,0) [-20.48|20.47] "A" Vector__XXX
 SG_ VCSEAT2L_a224_seatMotorState m224 : 29|3@1+ (1,0) [0|7] "" Vector__XXX
 SG_ VCSEAT2L_a224_seatSwitchBack m224 : 32|2@1+ (1,0) [1|3] "" Vector__XXX
 SG_ VCSEAT2L_a224_seatSwitchForward m224 : 34|2@1+ (1,0) [1|3] "" Vector__XXX
 SG_ VCSEAT2L_a225_seatMotorCalibrate m225 : 16|1@1+ (1,0) [0|1] "" Vector__XXX
 SG_ VCSEAT2L_a225_seatMotorCurrent m225 : 17|12@1- (0.01,0) [-20.48|20.47] "A" Vector__XXX
 SG_ VCSEAT2L_a225_seatMotorState m225 : 29|3@1+ (1,0) [0|7] "" Vector__XXX
 SG_ VCSEAT2L_a225_seatSwitchBack m225 : 32|2@1+ (1,0) [1|3] "" Vector__XXX
 SG_ VCSEAT2L_a225_seatSwitchForward m225 : 34|2@1+ (1,0) [1|3] "" Vector__XXX
 SG_ VCSEAT2L_a228_seatMotorCalibrate m228 : 16|1@1+ (1,0) [0|1] "" Vector__XXX
 SG_ VCSEAT2L_a228_seatMotorCurrent m228 : 17|12@1- (0.01,0) [-20.48|20.47] "A" Vector__XXX
 SG_ VCSEAT2L_a228_seatMotorPosReal m228 : 32|12@1- (1,0) [-2048|2047] "mm" Vector__XXX
 SG_ VCSEAT2L_a228_seatMotorState m228 : 44|3@1+ (1,0) [0|7] "" Vector__XXX
 SG_ VCSEAT2L_a228_seatSwitchBack m228 : 48|2@1+ (1,0) [1|3] "" Vector__XXX
 SG_ VCSEAT2L_a228_seatSwitchForward m228 : 50|2@1+ (1,0) [1|3] "" Vector__XXX
 SG_ VCSEAT2L_a229_seatMotorCalibrate m229 : 16|1@1+ (1,0) [0|1] "" Vector__XXX
 SG_ VCSEAT2L_a229_seatMotorCurrent m229 : 17|12@1- (0.01,0) [-20.48|20.47] "A" Vector__XXX
 SG_ VCSEAT2L_a229_seatMotorPosReal m229 : 32|12@1- (1,0) [-2048|2047] "mm" Vector__XXX
 SG_ VCSEAT2L_a229_seatMotorState m229 : 44|3@1+ (1,0) [0|7] "" Vector__XXX
 SG_ VCSEAT2L_a229_seatSwitchBack m229 : 48|2@1+ (1,0) [1|3] "" Vector__XXX
 SG_ VCSEAT2L_a229_seatSwitchForward m229 : 50|2@1+ (1,0) [1|3] "" Vector__XXX
 SG_ VCSEAT2L_a232_seatMotorCurrent m232 : 16|12@1- (0.01,0) [-20.48|20.47] "A" Vector__XXX
 SG_ VCSEAT2L_a232_seatMotorPosReal m232 : 28|12@1- (1,0) [-2048|2047] "mm" Vector__XXX
 SG_ VCSEAT2L_a232_seatMotorState m232 : 40|3@1+ (1,0) [0|7] "" Vector__XXX
 SG_ VCSEAT2L_a232_seatSwitchBack m232 : 43|2@1+ (1,0) [1|3] "" Vector__XXX
 SG_ VCSEAT2L_a232_seatSwitchForward m232 : 45|2@1+ (1,0) [1|3] "" Vector__XXX
 SG_ VCSEAT2L_a233_seatMotorCurrent m233 : 16|12@1- (0.01,0) [-20.48|20.47] "A" Vector__XXX
 SG_ VCSEAT2L_a233_seatMotorPosReal m233 : 28|12@1- (1,0) [-2048|2047] "mm" Vector__XXX
 SG_ VCSEAT2L_a233_seatMotorState m233 : 40|3@1+ (1,0) [0|7] "" Vector__XXX
 SG_ VCSEAT2L_a233_seatSwitchBack m233 : 43|2@1+ (1,0) [1|3] "" Vector__XXX
 SG_ VCSEAT2L_a233_seatSwitchForward m233 : 45|2@1+ (1,0) [1|3] "" Vector__XXX
 SG_ VCSEAT2L_a239_seatHeatCurrent m239 : 16|12@1+ (0.01,0) [0|40.95] "A" Vector__XXX
 SG_ VCSEAT2L_a239_seatHeatTmp m239 : 28|12@1- (0.05,0) [-102.4|102.35] "degC" Vector__XXX
 SG_ VCSEAT2L_a239_seatHeatTmpTarget m239 : 40|8@1- (0.5,0) [-64|63.5] "degC" Vector__XXX
 SG_ VCSEAT2L_a240_seatHeatCurrent m240 : 16|12@1+ (0.01,0) [0|40.95] "A" Vector__XXX
 SG_ VCSEAT2L_a240_seatHeatTmp m240 : 28|12@1- (0.05,0) [-102.4|102.35] "degC" Vector__XXX
 SG_ VCSEAT2L_a242_snsShortCircuit m242 : 16|1@1+ (1,0) [0|1] "" Vector__XXX
 SG_ VCSEAT2L_a242_snsDisconnect m242 : 17|1@1+ (1,0) [0|1] "" Vector__XXX
 SG_ VCSEAT2L_a242_snsRateChangeUp m242 : 18|1@1+ (1,0) [0|1] "" Vector__XXX
 SG_ VCSEAT2L_a242_snsRateChangeDown m242 : 19|1@1+ (1,0) [0|1] "" Vector__XXX
 SG_ VCSEAT2L_a251_seatMotorCurrent m251 : 16|12@1- (0.01,0) [-20.48|20.47] "A" Vector__XXX
 SG_ VCSEAT2L_a251_seatMotorPosReal m251 : 28|12@1- (1,0) [-2048|2047] "mm" Vector__XXX
 SG_ VCSEAT2L_a251_seatMotorState m251 : 40|3@1+ (1,0) [0|7] "" Vector__XXX
 SG_ VCSEAT2L_a251_seatSwitchBack m251 : 43|2@1+ (1,0) [1|3] "" Vector__XXX
 SG_ VCSEAT2L_a251_seatSwitchForward m251 : 45|2@1+ (1,0) [1|3] "" Vector__XXX
 SG_ VCSEAT2L_a252_seatMotorCurrent m252 : 16|12@1- (0.01,0) [-20.48|20.47] "A" Vector__XXX
 SG_ VCSEAT2L_a252_seatMotorPosReal m252 : 28|12@1- (1,0) [-2048|2047] "mm" Vector__XXX
 SG_ VCSEAT2L_a252_seatMotorState m252 : 40|3@1+ (1,0) [0|7] "" Vector__XXX
 SG_ VCSEAT2L_a252_seatSwitchBack m252 : 43|2@1+ (1,0) [1|3] "" Vector__XXX
 SG_ VCSEAT2L_a252_seatSwitchForward m252 : 45|2@1+ (1,0) [1|3] "" Vector__XXX
 SG_ VCSEAT2L_a260_seatStatePrev m260 : 16|3@1+ (1,0) [0|7] "" Vector__XXX
 SG_ VCSEAT2L_a260_obstacleDetectReas m260 : 19|3@1+ (1,0) [0|7] "" Vector__XXX
 SG_ VCSEAT2L_a260_obstacleDetectPosi m260 : 22|9@1- (1,140) [-116|395] "mm" Vector__XXX
 SG_ VCSEAT2L_a260_accelLookbackTripD m260 : 32|8@1+ (1,0) [0|255] "" Vector__XXX
 SG_ VCSEAT2L_a260_seatMotorCurrent m260 : 40|12@1- (0.01,0) [-20.48|20.47] "A" Vector__XXX
 SG_ VCSEAT2L_a261_seatStatePrev m261 : 16|3@1+ (1,0) [0|7] "" Vector__XXX
 SG_ VCSEAT2L_a261_obstacleDetectReas m261 : 19|3@1+ (1,0) [0|7] "" Vector__XXX
 SG_ VCSEAT2L_a261_obstacleDetectPosi m261 : 22|9@1- (1,140) [-116|395] "mm" Vector__XXX
 SG_ VCSEAT2L_a261_accelLookbackTripD m261 : 32|8@1+ (1,0) [0|255] "" Vector__XXX
 SG_ VCSEAT2L_a261_seatMotorCurrent m261 : 40|12@1- (0.01,0) [-20.48|20.47] "A" Vector__XXX
 SG_ VCSEAT2L_a263_seatMotorCurrent m263 : 16|12@1- (0.01,0) [-20.48|20.47] "A" Vector__XXX
 SG_ VCSEAT2L_a263_seatMotorDCurrent m263 : 28|12@1- (0.01,0) [-20.48|20.47] "A" Vector__XXX
 SG_ VCSEAT2L_a263_seatMotorPosReal m263 : 40|12@1- (1,0) [-2048|2047] "mm" Vector__XXX
 SG_ VCSEAT2L_a263_seatMotorState m263 : 52|3@1+ (1,0) [0|7] "" Vector__XXX
 SG_ VCSEAT2L_a264_seatMotorCurrent m264 : 16|12@1- (0.01,0) [-20.48|20.47] "A" Vector__XXX
 SG_ VCSEAT2L_a264_seatMotorDCurrent m264 : 28|12@1- (0.01,0) [-20.48|20.47] "A" Vector__XXX
 SG_ VCSEAT2L_a264_seatMotorPosReal m264 : 40|12@1- (1,0) [-2048|2047] "mm" Vector__XXX
 SG_ VCSEAT2L_a264_seatMotorState m264 : 52|3@1+ (1,0) [0|7] "" Vector__XXX
 SG_ VCSEAT2L_a267_seatMotorCurrent m267 : 16|12@1- (0.01,0) [-20.48|20.47] "A" Vector__XXX
 SG_ VCSEAT2L_a267_seatMotorDCurrent m267 : 28|12@1- (0.01,0) [-20.48|20.47] "A" Vector__XXX
 SG_ VCSEAT2L_a267_seatMotorPosReal m267 : 40|12@1- (1,0) [-2048|2047] "mm" Vector__XXX
 SG_ VCSEAT2L_a267_seatMotorState m267 : 52|3@1+ (1,0) [0|7] "" Vector__XXX
 SG_ VCSEAT2L_a268_seatMotorCurrent m268 : 16|12@1- (0.01,0) [-20.48|20.47] "A" Vector__XXX
 SG_ VCSEAT2L_a268_seatMotorDCurrent m268 : 28|12@1- (0.01,0) [-20.48|20.47] "A" Vector__XXX
 SG_ VCSEAT2L_a268_seatMotorPosReal m268 : 40|12@1- (1,0) [-2048|2047] "mm" Vector__XXX
 SG_ VCSEAT2L_a268_seatMotorState m268 : 52|3@1+ (1,0) [0|7] "" Vector__XXX
 SG_ VCSEAT2L_a270_isRearwardEndstopU m270 : 16|1@1+ (1,0) [0|1] "" Vector__XXX
 SG_ VCSEAT2L_a270_isAbsPosSensorUnca m270 : 17|1@1+ (1,0) [0|1] "" Vector__XXX
 SG_ VCSEAT2L_a270_seatState m270 : 18|4@1+ (1,0) [0|14] "" Vector__XXX
 SG_ VCSEAT2L_a270_motorType m270 : 22|1@1+ (1,0) [0|1] "" Vector__XXX
 SG_ VCSEAT2L_a270_absPosSensState m270 : 24|2@1+ (1,0) [0|3] "" Vector__XXX
 SG_ VCSEAT2L_a273_calibrated m273 : 16|1@1+ (1,0) [0|1] "" Vector__XXX
 SG_ VCSEAT2L_a273_angle m273 : 17|8@1- (0.5,59) [-5|122.5] "deg" Vector__XXX
 SG_ VCSEAT2L_a273_seatStatePrev m273 : 25|4@1+ (1,0) [0|14] "" Vector__XXX
 SG_ VCSEAT2L_a273_obstacleDetectReas m273 : 29|4@1+ (1,0) [0|15] "" Vector__XXX
 SG_ VCSEAT2L_a273_accelLookbackTripD m273 : 33|7@1+ (1,0) [0|127] "" Vector__XXX
 SG_ VCSEAT2L_a273_duty m273 : 40|8@1- (1,0) [-128|127] "%" Vector__XXX
 SG_ VCSEAT2L_a273_currentAbsFilt m273 : 48|8@1+ (0.25,0) [0|63.75] "A" Vector__XXX
 SG_ VCSEAT2L_a273_motorType m273 : 56|1@1+ (1,0) [0|1] "" Vector__XXX
 SG_ VCSEAT2L_a273_absolutePosSensorF m273 : 57|1@1+ (1,0) [0|1] "" Vector__XXX
 SG_ VCSEAT2L_a273_cabinTemp m273 : 58|6@1- (2,20) [-44|82] "degC" Vector__XXX
 SG_ VCSEAT2L_a277_isRearwardEndstopU m277 : 16|1@1+ (1,0) [0|1] "" Vector__XXX
 SG_ VCSEAT2L_a277_isAbsPosSensorUnca m277 : 17|1@1+ (1,0) [0|1] "" Vector__XXX
 SG_ VCSEAT2L_a278_seatState m278 : 16|4@1+ (1,0) [0|14] "" Vector__XXX
 SG_ VCSEAT2L_a290_isNetworkSwitch m290 : 16|1@1+ (1,0) [0|1] "" Vector__XXX
 SG_ VCSEAT2L_a290_occupancySensorV m290 : 17|12@1- (0.01,0) [-20.48|20.47] "V" Vector__XXX
 SG_ VCSEAT2L_a290_railVoltage m290 : 32|12@1- (0.01,0) [-20.48|20.47] "V" Vector__XXX
 SG_ VCSEAT2L_a291_buckleSensorVoltag m291 : 16|12@1+ (0.01,0) [0|40.95] "V" Vector__XXX
 SG_ VCSEAT2L_a291_railVoltage m291 : 28|12@1+ (0.01,0) [0|40.95] "V" Vector__XXX
 SG_ VCSEAT2L_a426_seatMotorCalibrate m426 : 16|1@1+ (1,0) [0|1] "" Vector__XXX
 SG_ VCSEAT2L_a426_seatMotorCurrent m426 : 17|12@1- (0.01,0) [-20.48|20.47] "A" Vector__XXX
 SG_ VCSEAT2L_a426_seatMotorPosReal m426 : 32|12@1- (1,0) [-2048|2047] "mm" Vector__XXX
 SG_ VCSEAT2L_a426_seatMotorState m426 : 44|3@1+ (1,0) [0|7] "" Vector__XXX
 SG_ VCSEAT2L_a426_seatSwitchBack m426 : 48|2@1+ (1,0) [1|3] "" Vector__XXX
 SG_ VCSEAT2L_a426_seatSwitchForward m426 : 50|2@1+ (1,0) [1|3] "" Vector__XXX
 SG_ VCSEAT2L_a426_cabinTmp m426 : 52|12@1- (0.1,0) [-204.8|204.7] "degC" Vector__XXX
 SG_ VCSEAT2L_a427_seatMotorCalibrate m427 : 16|1@1+ (1,0) [0|1] "" Vector__XXX
 SG_ VCSEAT2L_a427_seatMotorCurrent m427 : 17|12@1- (0.01,0) [-20.48|20.47] "A" Vector__XXX
 SG_ VCSEAT2L_a427_seatMotorPosReal m427 : 32|12@1- (1,0) [-2048|2047] "mm" Vector__XXX
 SG_ VCSEAT2L_a427_seatMotorState m427 : 44|3@1+ (1,0) [0|7] "" Vector__XXX
 SG_ VCSEAT2L_a427_seatSwitchBack m427 : 48|2@1+ (1,0) [1|3] "" Vector__XXX
 SG_ VCSEAT2L_a427_seatSwitchForward m427 : 50|2@1+ (1,0) [1|3] "" Vector__XXX
 SG_ VCSEAT2L_a427_cabinTmp m427 : 52|12@1- (0.1,0) [-204.8|204.7] "degC" Vector__XXX
 SG_ VCSEAT2L_a428_seatMotorCalibrate m428 : 16|1@1+ (1,0) [0|1] "" Vector__XXX
 SG_ VCSEAT2L_a428_seatMotorCurrent m428 : 17|12@1- (0.01,0) [-20.48|20.47] "A" Vector__XXX
 SG_ VCSEAT2L_a428_seatMotorPosReal m428 : 32|12@1- (1,0) [-2048|2047] "mm" Vector__XXX
 SG_ VCSEAT2L_a428_seatMotorState m428 : 44|3@1+ (1,0) [0|7] "" Vector__XXX
 SG_ VCSEAT2L_a428_seatSwitchBack m428 : 48|2@1+ (1,0) [1|3] "" Vector__XXX
 SG_ VCSEAT2L_a428_seatSwitchForward m428 : 50|2@1+ (1,0) [1|3] "" Vector__XXX
 SG_ VCSEAT2L_a428_cabinTmp m428 : 52|12@1- (0.1,0) [-204.8|204.7] "degC" Vector__XXX
 SG_ VCSEAT2L_a429_seatMotorCalibrate m429 : 16|1@1+ (1,0) [0|1] "" Vector__XXX
 SG_ VCSEAT2L_a429_seatMotorCurrent m429 : 17|12@1- (0.01,0) [-20.48|20.47] "A" Vector__XXX
 SG_ VCSEAT2L_a429_seatMotorPosReal m429 : 32|12@1- (1,0) [-2048|2047] "mm" Vector__XXX
 SG_ VCSEAT2L_a429_seatMotorState m429 : 44|3@1+ (1,0) [0|7] "" Vector__XXX
 SG_ VCSEAT2L_a429_seatSwitchBack m429 : 48|2@1+ (1,0) [1|3] "" Vector__XXX
 SG_ VCSEAT2L_a429_seatSwitchForward m429 : 50|2@1+ (1,0) [1|3] "" Vector__XXX
 SG_ VCSEAT2L_a429_cabinTmp m429 : 52|12@1- (0.1,0) [-204.8|204.7] "degC" Vector__XXX
 SG_ VCSEAT2L_a444_retriesAvailable m444 : 16|8@1+ (1,0) [0|255] "" Vector__XXX
 SG_ VCSEAT2L_a444_channel m444 : 24|8@1+ (1,0) [0|255] "" Vector__XXX
 SG_ VCSEAT2L_a444_watchdog m444 : 32|1@1+ (1,0) [0|1] "" Vector__XXX
 SG_ VCSEAT2L_a444_gateDriver m444 : 33|1@1+ (1,0) [0|1] "" Vector__XXX
 SG_ VCSEAT2L_a444_overcurrent m444 : 34|1@1+ (1,0) [0|1] "" Vector__XXX
 SG_ VCSEAT2L_a444_supplyUndervoltage m444 : 35|1@1+ (1,0) [0|1] "" Vector__XXX
 SG_ VCSEAT2L_a444_cpUndervoltage m444 : 36|1@1+ (1,0) [0|1] "" Vector__XXX
 SG_ VCSEAT2L_a444_overTempShutdown m444 : 37|1@1+ (1,0) [0|1] "" Vector__XXX
 SG_ VCSEAT2L_a444_overTempWarning m444 : 38|1@1+ (1,0) [0|1] "" Vector__XXX
 SG_ VCSEAT2L_a444_highSide2GateDrive m444 : 39|1@1+ (1,0) [0|1] "" Vector__XXX
 SG_ VCSEAT2L_a444_lowSide2GateDriver m444 : 40|1@1+ (1,0) [0|1] "" Vector__XXX
 SG_ VCSEAT2L_a444_highSide1GateDrive m444 : 41|1@1+ (1,0) [0|1] "" Vector__XXX
 SG_ VCSEAT2L_a444_lowSide1GateDriver m444 : 42|1@1+ (1,0) [0|1] "" Vector__XXX
 SG_ VCSEAT2L_a444_highSide2OverCuren m444 : 43|1@1+ (1,0) [0|1] "" Vector__XXX
 SG_ VCSEAT2L_a444_lowSide2OverCurent m444 : 44|1@1+ (1,0) [0|1] "" Vector__XXX
 SG_ VCSEAT2L_a444_highSide1OverCuren m444 : 45|1@1+ (1,0) [0|1] "" Vector__XXX
 SG_ VCSEAT2L_a444_lowSide1OverCurent m444 : 46|1@1+ (1,0) [0|1] "" Vector__XXX
 SG_ VCSEAT2L_a444_spiInit m444 : 47|1@1+ (1,0) [0|1] "" Vector__XXX
 SG_ VCSEAT2L_a444_spiPeriodicCheck m444 : 48|1@1+ (1,0) [0|1] "" Vector__XXX
 SG_ VCSEAT2L_a444_spiFault m444 : 49|1@1+ (1,0) [0|1] "" Vector__XXX
 SG_ VCSEAT2L_a444_voltageMonitor m444 : 50|1@1+ (1,0) [0|1] "" Vector__XXX
 SG_ VCSEAT2L_a444_enableLow m444 : 51|1@1+ (1,0) [0|1] "" Vector__XXX
 SG_ VCSEAT2L_a571_seatHeatCurrent m571 : 16|12@1+ (0.01,0) [0|40.95] "A" Vector__XXX
 SG_ VCSEAT2L_a571_seatHeatTmp m571 : 28|12@1- (0.05,0) [-102.4|102.35] "degC" Vector__XXX

BO_TX_BU_ 293 : UI;
BO_TX_BU_ 294 : UI;
BO_TX_BU_ 295 : UI;
BO_TX_BU_ 1279 : UI;
BO_TX_BU_ 993 : UI;
BO_TX_BU_ 666 : UI;
BO_TX_BU_ 563 : UI;
BO_TX_BU_ 986 : UI;
BO_TX_BU_ 661 : UI;
BO_TX_BU_ 1263 : UI;
BO_TX_BU_ 139 : UI;
BO_TX_BU_ 1173 : UI;
BO_TX_BU_ 1174 : UI;
BO_TX_BU_ 1175 : UI;
BO_TX_BU_ 649 : VCLEFT;
BO_TX_BU_ 1336 : VCSEAT2L;
CM_ BO_ 293 "Touchscreen user interface computer message: alert matrix3";
CM_ SG_ 293 UI_a129_dgpuOperationFailure "Touchscreen user interface computer: a129 dgpu operation failure";
CM_ SG_ 293 UI_a130_QtCarClusterExitError "Signal reported by Touchscreen user interface computer";
CM_ SG_ 293 UI_a131_DisplayPortFailure "Touchscreen user interface computer: a131 display port failure";
CM_ SG_ 293 UI_a132_AdspWatchdogRecoveryTrig "Touchscreen user interface computer: a132 adsp watchdog recovery triggered";
CM_ SG_ 293 UI_a133_AdspWatchdogRecoveryFail "Touchscreen user interface computer: a133 adsp watchdog recovery failed";
CM_ SG_ 293 UI_a134_DashcamUsbDriveNoMedium "Touchscreen user interface computer: a134 dashcam usb drive no medium";
CM_ SG_ 293 UI_a135_warnRunOverlayExists "Touchscreen user interface computer: a135 warn run overlay exists";
CM_ SG_ 293 UI_a136_warnSettingsConfExists "Touchscreen user interface computer: a136 warn settings conf exists";
CM_ SG_ 293 UI_a137_ServiceShellActiveConnec "Touchscreen user interface computer: a137 service shell active connection";
CM_ SG_ 293 UI_a138_applyingConfigChange "Touchscreen user interface computer: a138 applying config change";
CM_ SG_ 293 UI_a139_postponedConfigChange "Touchscreen user interface computer: a139 postponed config change";
CM_ SG_ 293 UI_a140_NeverSleepActive "Touchscreen user interface computer: a140 never sleep active";
CM_ SG_ 293 UI_a141_falconDoorOpen "Touchscreen user interface computer: a141 falcon door open";
CM_ SG_ 293 UI_a142_CorrectableMemoryError "Touchscreen user interface computer: a142 correctable memory error";
CM_ SG_ 293 UI_a143_FPSCrawling "Touchscreen user interface computer: a143 FPS crawling";
CM_ SG_ 293 UI_a144_nvmeWarning "Touchscreen user interface computer: a144 nvme warning";
CM_ SG_ 293 UI_a145_nvmeUnsafeShutdown "Touchscreen user interface computer: a145 nvme unsafe shutdown";
CM_ SG_ 293 UI_a146_nvmeNeedsReplacement "Touchscreen user interface computer: a146 nvme needs replacement";
CM_ SG_ 293 UI_a147_ASILGlobalError "Touchscreen user interface computer: a147 ASIL global error";
CM_ SG_ 293 UI_a148_SleepFailure "Touchscreen user interface computer: a148 sleep failure";
CM_ SG_ 293 UI_a149_DisplayCheckFailure "Touchscreen user interface computer: a149 display check failure";
CM_ SG_ 293 UI_a150_infoCPURunningHot "Touchscreen user interface computer: a150 info CPU running hot";
CM_ SG_ 293 UI_a151_carComputerThermalProble "Touchscreen user interface computer: a151 car computer thermal problem";
CM_ SG_ 293 UI_a152_infoThrottling "Touchscreen user interface computer: a152 info throttling";
CM_ SG_ 293 UI_a153_serviceRestarted "Touchscreen user interface computer: a153 service restarted";
CM_ SG_ 293 UI_a154_AudiodBufferError "Touchscreen user interface computer: a154 audiod buffer error";
CM_ SG_ 293 UI_a155_UsbFrontHubUnavailable "Touchscreen user interface computer: a155 usb front hub unavailable";
CM_ SG_ 293 UI_a156_UsbFrontHubInstallMismat "Touchscreen user interface computer: a156 usb front hub install mismatch";
CM_ SG_ 293 UI_a157_MCUActiveCoolingRequeste "Touchscreen user interface computer: a157 MCU active cooling requested";
CM_ SG_ 293 UI_a158_UsbDeviceMountError "Touchscreen user interface computer: a158 usb device mount error";
CM_ SG_ 293 UI_a159_AudioHeartbeatFailure "Touchscreen user interface computer: a159 audio heartbeat failure";
CM_ SG_ 293 UI_a160_SystemWatchdogFailure "Touchscreen user interface computer: a160 system watchdog failure";
CM_ SG_ 293 UI_a161_ECallTemporarilyUnavaila "Touchscreen user interface computer: a161 e call temporarily unavailable";
CM_ SG_ 293 UI_a162_voiceRecClipsUploaded "Touchscreen user interface computer: a162 voice rec clips uploaded";
CM_ SG_ 293 UI_a163_QtCarVehicleExitError "Signal reported by Touchscreen user interface computer";
CM_ SG_ 293 UI_a164_AudiodConnTimeout "Touchscreen user interface computer: a164 audiod conn timeout";
CM_ SG_ 293 UI_a165_fsCorrupted "Touchscreen user interface computer: a165 fs corrupted";
CM_ SG_ 293 UI_a166_fsError "Touchscreen user interface computer: a166 fs error";
CM_ SG_ 293 UI_a167_CgroupOverMemKill "Touchscreen user interface computer: a167 cgroup over mem kill";
CM_ SG_ 293 UI_a168_dgpuPowerOnSelfTestFailu "Touchscreen user interface computer: a168 dgpu power on self test failure";
CM_ SG_ 293 UI_a169_SteamLoadShedFailure "Touchscreen user interface computer: a169 steam load shed failure";
CM_ SG_ 293 UI_a170_AMDdGPULoadShedFailure "Touchscreen user interface computer: a170 AM dd GPU load shed failure";
CM_ SG_ 293 UI_a171_GraphicsLoadShedRequeste "Touchscreen user interface computer: a171 graphics load shed requested";
CM_ SG_ 293 UI_a172_GraphicsLoadShedUIFailur "Touchscreen user interface computer: a172 graphics load shed UI failure";
CM_ SG_ 293 UI_a173_pmSuspendFailure "Touchscreen user interface computer: a173 pm suspend failure";
CM_ SG_ 293 UI_a174_HistorySaveLoop "Touchscreen user interface computer: a174 history save loop";
CM_ SG_ 293 UI_a176_CellularAntennaAlert "Touchscreen user interface computer: a176 cellular antenna alert";
CM_ SG_ 293 UI_a177_MediaPlayerFailure "Touchscreen user interface computer: a177 media player failure";
CM_ SG_ 293 UI_a178_irqDisabled "Touchscreen user interface computer: a178 irq disabled";
CM_ SG_ 293 UI_a180_AudiodInputRestarted "Touchscreen user interface computer: a180 audiod input restarted";
CM_ SG_ 293 UI_a181_ModemFirmwareVersionMism "Touchscreen user interface computer: a181 modem firmware version mismatch";
CM_ SG_ 293 UI_a182_VideoPipelineOverrun "Touchscreen user interface computer: a182 video pipeline overrun";
CM_ SG_ 293 UI_a183_DDAWFaulted "Touchscreen user interface computer: a183 DDAW faulted";
CM_ SG_ 293 UI_a184_ISAFaulted "Touchscreen user interface computer: a184 ISA faulted";
CM_ SG_ 293 UI_a185_ELKSDisabled "Touchscreen user interface computer: a185 ELKS disabled";
CM_ SG_ 293 UI_a186_ELKSUnavailable "Touchscreen user interface computer: a186 ELKS unavailable";
CM_ SG_ 293 UI_a187_TunerFirmwareMismatchedV "Touchscreen user interface computer: a187 tuner firmware mismatched version";
CM_ SG_ 293 UI_a188_TunerFirmwareMismatchedA "Touchscreen user interface computer: a188 tuner firmware mismatched API";
CM_ SG_ 293 UI_a189_TunerWatchdogReset "Touchscreen user interface computer: a189 tuner watchdog reset";
CM_ SG_ 293 UI_a190_TunerMIA "Touchscreen user interface computer: a190 tuner MIA";
CM_ SG_ 293 UI_a191_TunerUpdateFailed "Touchscreen user interface computer: a191 tuner update failed";
CM_ SG_ 293 UI_a192_AudioWatchdogReboot "Touchscreen user interface computer: a192 audio watchdog reboot";
CM_ BO_ 294 "Touchscreen user interface computer message: alert matrix4";
CM_ SG_ 294 UI_a193_TcuRNandFwVersionMismatc "Touchscreen user interface computer: a193 tcu r nand fw version mismatch";
CM_ SG_ 294 UI_a194_AudioweaverRestarted "Touchscreen user interface computer: a194 audioweaver restarted";
CM_ SG_ 294 UI_a195_gtwMfdUdpApiFired "Touchscreen user interface computer: a195 gtw mfd udp api fired";
CM_ SG_ 294 UI_a196_AMDI2C3BusInoperable "Touchscreen user interface computer: a196 AMDI2 C3 bus inoperable";
CM_ SG_ 294 UI_a197_AMDI2C1BusInoperable "Touchscreen user interface computer: a197 AMDI2 C1 bus inoperable";
CM_ SG_ 294 UI_a198_IncompatibleBTUSBHubHard "Touchscreen user interface computer: a198 incompatible BTUSB hub hardware";
CM_ SG_ 294 UI_a199_HighAPedalDetectedAtColl "Touchscreen user interface computer: a199 high a pedal detected at collision";
CM_ SG_ 294 UI_a200_UIFirmwareVersionMismatc "Touchscreen user interface computer: a200 UI firmware version mismatch";
CM_ SG_ 294 UI_a201_rearDisplayDisconnected "Touchscreen user interface computer: a201 rear display disconnected";
CM_ SG_ 294 UI_a202_sysMemoryIncorrect "Touchscreen user interface computer: a202 sys memory incorrect";
CM_ SG_ 294 UI_a204_ModemSleepFailure "Touchscreen user interface computer: a204 modem sleep failure";
CM_ SG_ 294 UI_a205_ModemSleepSignalMismatch "Touchscreen user interface computer: a205 modem sleep signal mismatch";
CM_ SG_ 294 UI_a206_ModemMIAAfterWake "Touchscreen user interface computer: a206 modem MIA after wake";
CM_ SG_ 294 UI_a208_mqttClientDisconnected "Touchscreen user interface computer: a208 mqtt client disconnected";
CM_ SG_ 294 UI_a209_dataCallDisconnected "Touchscreen user interface computer: a209 data call disconnected";
CM_ SG_ 294 UI_a210_CellularCSRegFail "Touchscreen user interface computer: a210 cellular CS reg fail";
CM_ SG_ 294 UI_a211_AEBSDisabled "Touchscreen user interface computer: a211 AEBS disabled";
CM_ SG_ 294 UI_a212_AEBSFaulted "Touchscreen user interface computer: a212 AEBS faulted";
CM_ SG_ 294 UI_a213_ISADisabled "Touchscreen user interface computer: a213 ISA disabled";
CM_ SG_ 294 UI_a214_pmHelperFailure "Touchscreen user interface computer: a214 pm helper failure";
CM_ SG_ 294 UI_a215_compositorStallDetected "Touchscreen user interface computer: a215 compositor stall detected";
CM_ SG_ 294 UI_a216_AudioA2bCircuitProblem "Touchscreen user interface computer: a216 audio a2b circuit problem";
CM_ SG_ 294 UI_a217_CgroupMemoryPressure "Touchscreen user interface computer: a217 cgroup memory pressure";
CM_ SG_ 294 UI_a218_AudiodNoAudioDevices "Touchscreen user interface computer: a218 audiod no audio devices";
CM_ SG_ 294 UI_a219_CompositorWatchdog "Touchscreen user interface computer: a219 compositor watchdog";
CM_ SG_ 294 UI_a220_MediaBrowseError "Touchscreen user interface computer: a220 media browse error";
CM_ SG_ 294 UI_a221_NavigationServiceError "Touchscreen user interface computer: a221 navigation service error";
CM_ SG_ 294 UI_a222_QtCarRestart "Signal reported by Touchscreen user interface computer";
CM_ SG_ 294 UI_a223_databaseError "Touchscreen user interface computer: a223 database error";
CM_ SG_ 294 UI_a224_centerDisplayDisconnecte "Touchscreen user interface computer: a224 center display disconnected";
CM_ SG_ 294 UI_a225_clusterDisplayDisconnect "Touchscreen user interface computer: a225 cluster display disconnected";
CM_ SG_ 294 UI_a226_largePhoneContactSync "Touchscreen user interface computer: a226 large phone contact sync";
CM_ SG_ 294 UI_a228_pipewireXrunBurst "Touchscreen user interface computer: a228 pipewire xrun burst";
CM_ SG_ 294 UI_a229_SerDesError "Touchscreen user interface computer: a229 ser des error";
CM_ SG_ 294 UI_a230_ModemSimCardMismatch "Touchscreen user interface computer: a230 modem sim card mismatch";
CM_ SG_ 294 UI_a231_SleepCancelled "Touchscreen user interface computer: a231 sleep cancelled";
CM_ SG_ 294 UI_a232_processExitError "Touchscreen user interface computer: a232 process exit error";
CM_ SG_ 294 UI_a233_ModemRFFailure "Touchscreen user interface computer: a233 modem RF failure";
CM_ SG_ 294 UI_a234_AMDI2C0Timeout "Touchscreen user interface computer: a234 AMDI2 C0 timeout";
CM_ SG_ 294 UI_a235_AMDI2C1Timeout "Touchscreen user interface computer: a235 AMDI2 C1 timeout";
CM_ SG_ 294 UI_a236_ModemOnResetState "Touchscreen user interface computer: a236 modem on reset state";
CM_ SG_ 294 UI_a237_ClipUploadActive "Touchscreen user interface computer: a237 clip upload active";
CM_ SG_ 294 UI_a238_ModemConfigMismatch "Touchscreen user interface computer: a238 modem config mismatch";
CM_ SG_ 294 UI_a240_ethError "Touchscreen user interface computer: a240 eth error";
CM_ SG_ 294 UI_a241_AxCPError "Touchscreen user interface computer: a241 ax CP error";
CM_ SG_ 294 UI_a242_uiHealthFaultInjectionAc "Touchscreen user interface computer: a242 ui health fault injection active";
CM_ SG_ 294 UI_a243_pmDisplayCheckFailure "Touchscreen user interface computer: a243 pm display check failure";
CM_ SG_ 294 UI_a244_segfault "Touchscreen user interface computer: a244 segfault";
CM_ SG_ 294 UI_a245_taskHung "Touchscreen user interface computer: a245 task hung";
CM_ SG_ 294 UI_a246_gpuFenceTimeout "Touchscreen user interface computer: a246 gpu fence timeout";
CM_ SG_ 294 UI_a247_StalklessDisplayBackligh "Touchscreen user interface computer: a247 stalkless display backlight failure";
CM_ SG_ 294 UI_a252_TPMErrorReceive "Touchscreen user interface computer: a252 TPM error receive";
CM_ SG_ 294 UI_a253_maintenanceHistoryRecord "Touchscreen user interface computer: a253 maintenance history recorded";
CM_ SG_ 294 UI_a254_appCertificateExpired "Touchscreen user interface computer: a254 app certificate expired";
CM_ SG_ 294 UI_a255_apbCertificateExpired "Touchscreen user interface computer: a255 apb certificate expired";
CM_ SG_ 294 UI_a256_sapFailedToEnable "Touchscreen user interface computer: a256 sap failed to enable";
CM_ BO_ 295 "Touchscreen user interface computer message: alert matrix5";
CM_ SG_ 295 UI_a257_modemRebooting "Touchscreen user interface computer: a257 modem rebooting";
CM_ SG_ 295 UI_a258_sapFailedToPowerOn "Touchscreen user interface computer: a258 sap failed to power on";
CM_ SG_ 295 UI_a259_sapChannelMismatch "Touchscreen user interface computer: a259 sap channel mismatch";
CM_ SG_ 295 UI_a260_sapWrongChannel "Touchscreen user interface computer: a260 sap wrong channel";
CM_ SG_ 295 UI_a261_bluetoothStackPanic "Touchscreen user interface computer: a261 bluetooth stack panic";
CM_ SG_ 295 UI_a263_ecuLogUploadFailure "Touchscreen user interface computer: a263 ecu log upload failure";
CM_ SG_ 295 UI_a264_invalidEpaRange "Touchscreen user interface computer: a264 invalid epa range";
CM_ SG_ 295 UI_a265_USBHostControllerUnrecov "Touchscreen user interface computer: a265 USB host controller unrecoverable";
CM_ SG_ 295 UI_a266_DashcamRecentBufferDurat "Touchscreen user interface computer: a266 dashcam recent buffer duration reduced";
CM_ SG_ 295 UI_a272_eapTlsCSRFailure "Touchscreen user interface computer: a272 eap tls CSR failure";
CM_ SG_ 295 UI_a273_AudioDbusFailure "Touchscreen user interface computer: a273 audio dbus failure";
CM_ SG_ 295 UI_a274_ContextualHintCardEvent "Touchscreen user interface computer: a274 contextual hint card event";
CM_ SG_ 295 UI_a275_ADDWFaulted "Touchscreen user interface computer: a275 ADDW faulted";
CM_ SG_ 295 UI_a276_PrivateNetworkProfileAct "Touchscreen user interface computer: a276 private network profile active";
CM_ SG_ 295 UI_a277_PONRPopupShown "Touchscreen user interface computer: a277 PONR popup shown";
CM_ SG_ 295 UI_a278_gpsHwDegraded "Touchscreen user interface computer: a278 gps hw degraded";
CM_ BO_ 1279 "Touchscreen user interface computer message: energy consumption info";
CM_ SG_ 1279 UI_energyConsumptionInfoIndex "Touchscreen user interface computer: energy consumption info index";
CM_ SG_ 1279 UI_energyLossTotal_epa "Energy amount for a given bucket for an energy consumption baseline (raw/real energy consumed)";
CM_ SG_ 1279 UI_energyLossDriving_epa "Energy amount for a given bucket for an energy consumption baseline (raw/real energy consumed)";
CM_ SG_ 1279 UI_energyLossClimate_epa "Energy amount for a given bucket for an energy consumption baseline (raw/real energy consumed)";
CM_ SG_ 1279 UI_energyLossBattCond_epa "Energy amount for a given bucket for an energy consumption baseline (raw/real energy consumed)";
CM_ SG_ 1279 UI_energyLossElevation_epa "Energy amount for a given bucket for an energy consumption baseline (raw/real energy consumed)";
CM_ SG_ 1279 UI_energyLossAcc_epa "Energy amount for a given bucket for an energy consumption baseline (raw/real energy consumed)";
CM_ SG_ 1279 UI_energyLossTotalSinceCharge_ep "Energy amount for a given bucket for an energy consumption baseline (raw/real energy consumed)";
CM_ SG_ 1279 UI_energyLossDrivingSinceCharge_ "Energy amount for a given bucket for an energy consumption baseline (raw/real energy consumed)";
CM_ SG_ 1279 UI_energyLossClimateSinceCharge_ "Energy amount for a given bucket for an energy consumption baseline (raw/real energy consumed)";
CM_ SG_ 1279 UI_energyLossBattCondSinceCharge "Energy amount for a given bucket for an energy consumption baseline (raw/real energy consumed)";
CM_ SG_ 1279 UI_energyLossElevationSinceCharg "Energy amount for a given bucket for an energy consumption baseline (raw/real energy consumed)";
CM_ SG_ 1279 UI_energyLossAccSinceCharge_epa "Energy amount for a given bucket for an energy consumption baseline (raw/real energy consumed)";
CM_ SG_ 1279 UI_energyLossTotalSinceTripStart "Energy amount for a given bucket for an energy consumption baseline (raw/real energy consumed)";
CM_ SG_ 1279 UI_energyLossDrivingSinceTripSta "Energy amount for a given bucket for an energy consumption baseline (raw/real energy consumed)";
CM_ SG_ 1279 UI_energyLossClimateSinceTripSta "Energy amount for a given bucket for an energy consumption baseline (raw/real energy consumed)";
CM_ SG_ 1279 UI_energyLossBattCondSinceTripSt "Energy amount for a given bucket for an energy consumption baseline (raw/real energy consumed)";
CM_ SG_ 1279 UI_energyLossElevationSinceTripS "Energy amount for a given bucket for an energy consumption baseline (raw/real energy consumed)";
CM_ SG_ 1279 UI_energyLossAccSinceTripStart "Energy amount for a given bucket for an energy consumption baseline (raw/real energy consumed)";
CM_ SG_ 1279 UI_energyDeltaTotal_epa "Energy amount for a given bucket for an energy consumption baseline (raw/real energy consumed)";
CM_ SG_ 1279 UI_energyDeltaDriving_epa "Energy amount for a given bucket for an energy consumption baseline (raw/real energy consumed)";
CM_ SG_ 1279 UI_energyDeltaClimate_epa "Energy amount for a given bucket for an energy consumption baseline (raw/real energy consumed)";
CM_ SG_ 1279 UI_energyDeltaBattCond_epa "Energy amount for a given bucket for an energy consumption baseline (raw/real energy consumed)";
CM_ SG_ 1279 UI_energyDeltaElevation_epa "Energy amount for a given bucket for an energy consumption baseline (raw/real energy consumed)";
CM_ SG_ 1279 UI_energyDeltaAcc_epa "Energy amount for a given bucket for an energy consumption baseline (raw/real energy consumed)";
CM_ SG_ 1279 UI_uiDeltaOffsetTotal_epa "Energy amount for a given bucket for an energy consumption baseline (raw/real energy consumed)";
CM_ SG_ 1279 UI_uiDeltaOffsetDriving_epa "Energy amount for a given bucket for an energy consumption baseline (raw/real energy consumed)";
CM_ SG_ 1279 UI_uiDeltaOffsetClimate_epa "Energy amount for a given bucket for an energy consumption baseline (raw/real energy consumed)";
CM_ SG_ 1279 UI_uiDeltaOffsetBattCond_epa "Energy amount for a given bucket for an energy consumption baseline (raw/real energy consumed)";
CM_ SG_ 1279 UI_uiDeltaOffsetElevation_epa "Energy amount for a given bucket for an energy consumption baseline (raw/real energy consumed)";
CM_ SG_ 1279 UI_uiDeltaOffsetAcc_epa "Energy amount for a given bucket for an energy consumption baseline (raw/real energy consumed)";
CM_ SG_ 1279 UI_rawToUiEnergyRatio_epa "Ratio used for conversion between UI and raw energy domains";
CM_ SG_ 1279 UI_driveDistance_epa "Distance driven for an energy consumption baseline";
CM_ SG_ 1279 UI_energyDeltaTotalSinceCharge_e "Energy amount for a given bucket for an energy consumption baseline (raw/real energy consumed)";
CM_ SG_ 1279 UI_energyDeltaDrivingSinceCharge "Energy amount for a given bucket for an energy consumption baseline (raw/real energy consumed)";
CM_ SG_ 1279 UI_energyDeltaClimateSinceCharge "Energy amount for a given bucket for an energy consumption baseline (raw/real energy consumed)";
CM_ SG_ 1279 UI_energyDeltaBattCondSinceCharg "Energy amount for a given bucket for an energy consumption baseline (raw/real energy consumed)";
CM_ SG_ 1279 UI_energyDeltaElevationSinceChar "Energy amount for a given bucket for an energy consumption baseline (raw/real energy consumed)";
CM_ SG_ 1279 UI_energyDeltaAccSinceCharge_epa "Energy amount for a given bucket for an energy consumption baseline (raw/real energy consumed)";
CM_ SG_ 1279 UI_uiDeltaOffsetTotalSinceCharge "Energy amount for a given bucket for an energy consumption baseline (raw/real energy consumed)";
CM_ SG_ 1279 UI_uiDeltaOffsetDrivingSinceChar "Energy amount for a given bucket for an energy consumption baseline (raw/real energy consumed)";
CM_ SG_ 1279 UI_uiDeltaOffsetClimateSinceChar "Energy amount for a given bucket for an energy consumption baseline (raw/real energy consumed)";
CM_ SG_ 1279 UI_uiDeltaOffsetBattCondSinceCha "Energy amount for a given bucket for an energy consumption baseline (raw/real energy consumed)";
CM_ SG_ 1279 UI_uiDeltaOffsetElevationSinceCh "Energy amount for a given bucket for an energy consumption baseline (raw/real energy consumed)";
CM_ SG_ 1279 UI_uiDeltaOffsetAccSinceCharge_e "Energy amount for a given bucket for an energy consumption baseline (raw/real energy consumed)";
CM_ SG_ 1279 UI_rawToUiEnergyRatioSinceCharge "Ratio used for conversion between UI and raw energy domains";
CM_ SG_ 1279 UI_driveDistanceSinceCharge_epa "Distance driven for an energy consumption baseline";
CM_ SG_ 1279 UI_energyDeltaTotalSinceTripStar "Energy amount for a given bucket for an energy consumption baseline (raw/real energy consumed)";
CM_ SG_ 1279 UI_energyDeltaDrivingSinceTripSt "Energy amount for a given bucket for an energy consumption baseline (raw/real energy consumed)";
CM_ SG_ 1279 UI_energyDeltaClimateSinceTripSt "Energy amount for a given bucket for an energy consumption baseline (raw/real energy consumed)";
CM_ SG_ 1279 UI_energyDeltaBattCondSinceTripS "Energy amount for a given bucket for an energy consumption baseline (raw/real energy consumed)";
CM_ SG_ 1279 UI_energyDeltaElevationSinceTrip "Energy amount for a given bucket for an energy consumption baseline (raw/real energy consumed)";
CM_ SG_ 1279 UI_energyDeltaAccSinceTripStart "Energy amount for a given bucket for an energy consumption baseline (raw/real energy consumed)";
CM_ SG_ 1279 UI_uiDeltaOffsetTotalSinceTripSt "Energy amount for a given bucket for an energy consumption baseline (raw/real energy consumed)";
CM_ SG_ 1279 UI_uiDeltaOffsetDrivingSinceTrip "Energy amount for a given bucket for an energy consumption baseline (raw/real energy consumed)";
CM_ SG_ 1279 UI_uiDeltaOffsetClimateSinceTrip "Energy amount for a given bucket for an energy consumption baseline (raw/real energy consumed)";
CM_ SG_ 1279 UI_uiDeltaOffsetBattCondSinceTri "Energy amount for a given bucket for an energy consumption baseline (raw/real energy consumed)";
CM_ SG_ 1279 UI_uiDeltaOffsetElevationSinceTr "Energy amount for a given bucket for an energy consumption baseline (raw/real energy consumed)";
CM_ SG_ 1279 UI_uiDeltaOffsetAccSinceTripStar "Energy amount for a given bucket for an energy consumption baseline (raw/real energy consumed)";
CM_ SG_ 1279 UI_rawToUiEnergyRatioSinceTripSt "Ratio used for conversion between UI and raw energy domains";
CM_ SG_ 1279 UI_driveDistanceSinceTripStart "Distance driven for an energy consumption baseline";
CM_ SG_ 1279 UI_voyagerEnabled "Touchscreen user interface computer: voyager enabled";
CM_ SG_ 1279 UI_trailerMass "Trailer mass from user input";
CM_ BO_ 993 "Touchscreen user interface computer message: gear slider info";
CM_ SG_ 993 UI_gearSliderInfoIndex "Touchscreen user interface computer: gear slider info index";
CM_ SG_ 993 UI_gearSliderW "Touchscreen user interface computer: gear slider w";
CM_ SG_ 993 UI_gearSliderH "Touchscreen user interface computer: gear slider h";
CM_ SG_ 993 UI_gearSliderX "Touchscreen user interface computer: gear slider x";
CM_ SG_ 993 UI_gearSliderY "Touchscreen user interface computer: gear slider y";
CM_ SG_ 993 UI_gearParkW "Touchscreen user interface computer: gear park w";
CM_ SG_ 993 UI_gearParkH "Touchscreen user interface computer: gear park h";
CM_ SG_ 993 UI_gearParkX "Touchscreen user interface computer: gear park x";
CM_ SG_ 993 UI_gearParkY "Touchscreen user interface computer: gear park y";
CM_ SG_ 993 UI_gearNeutralW "Touchscreen user interface computer: gear neutral w";
CM_ SG_ 993 UI_gearNeutralH "Touchscreen user interface computer: gear neutral h";
CM_ SG_ 993 UI_gearNeutralX "Touchscreen user interface computer: gear neutral x";
CM_ SG_ 993 UI_gearNeutralY "Touchscreen user interface computer: gear neutral y";
CM_ BO_ 666 "Touchscreen user interface computer message: seat control";
CM_ SG_ 666 UI_seatControlIndex "Touchscreen user interface computer: seat control index";
CM_ SG_ 666 UI_3RSeatChildLock "Reports the state of 3rd row seat fold flat child lock from the UI";
CM_ SG_ 666 UI_2RowLeftSeatTrackBack "Touchscreen user interface computer: 2 row left seat track back";
CM_ SG_ 666 UI_2RowLeftSeatTrackForward "Touchscreen user interface computer: 2 row left seat track forward";
CM_ SG_ 666 UI_2RowRightSeatTrackBack "Touchscreen user interface computer: 2 row right seat track back";
CM_ SG_ 666 UI_2RowRightSeatTrackForward "Touchscreen user interface computer: 2 row right seat track forward";
CM_ SG_ 666 UI_left3RowSeatAdjustmentRequest "Reports request from the touchscreen User Interface (UI) to actuate the left third row seat.";
CM_ SG_ 666 UI_right3RowSeatAdjustmentReques "Reports request from the touchscreen User Interface (UI) to actuate the right third row seat.";
CM_ SG_ 666 UI_2RLeftSeatFanReq "Request for second row left seat ventilation";
CM_ SG_ 666 UI_2RRightSeatFanReq "Request for second row right seat ventilation";
CM_ SG_ 666 UI_leftThirdRowSeatRequestFromRe "Touchscreen user interface computer: left third row seat request from rear display";
CM_ SG_ 666 UI_rightThirdRowSeatRequestFromR "Touchscreen user interface computer: right third row seat request from rear display";
CM_ SG_ 666 UI_seatChoreographyStopRequest "Reports if the UI requests to stop the seat choreography";
CM_ BO_ 563 "Touchscreen user interface computer message: stalkless control";
CM_ SG_ 563 UI_stalklessControlCounter "Touchscreen user interface computer: stalkless control counter";
CM_ SG_ 563 UI_stalklessControlChecksum "Touchscreen user interface computer: stalkless control checksum";
CM_ SG_ 563 UI_gearStripSuppressCounter "Touchscreen user interface computer: gear strip suppress counter";
CM_ SG_ 563 UI_gearRequest "UI gear request from UI; raw 0 = signal not available (SNA)";
CM_ SG_ 563 UI_autopilotRequest "Touchscreen user interface computer: autopilot request";
CM_ SG_ 563 UI_gearStripShowing "UI communicating to GTW that the gear strip is visible on the screen as part of a handshake";
CM_ SG_ 563 UI_gearStripLocation "Touchscreen user interface computer: gear strip location";
CM_ SG_ 563 UI_parkButtonShowing "Touchscreen user interface computer: park button showing";
CM_ SG_ 563 UI_neutralButtonShowing "Touchscreen user interface computer: neutral button showing";
CM_ SG_ 563 UI_gearStripForceShow "UI request to GTW to show the gear strip";
CM_ SG_ 563 UI_neutralButtonDrawerForceShow "Touchscreen user interface computer: neutral button drawer force show";
CM_ SG_ 563 UI_autoParkAvailable "UI communicating to GTW that the autpark functionality is available";
CM_ SG_ 563 UI_autoParkShowing "Touchscreen user interface computer: auto park showing";
CM_ SG_ 563 UI_gearStripSuppressActive "UI communicating to GTW that the gear strip should not be shown";
CM_ SG_ 563 UI_gearNeutralPressed "Neutral button is being pressed";
CM_ BO_ 986 "Touchscreen user interface computer message: status3";
CM_ SG_ 986 UI_wifiRegDomain "Indicates the Wi-Fi regulatory domain.";
CM_ SG_ 986 UI_wifiTethered "Monitors whether Wi-Fi is connected while driving.";
CM_ BO_ 661 "Touchscreen user interface computer message: system monitor";
CM_ SG_ 661 UI_systemMonitorIndex "Touchscreen user interface computer: system monitor index";
CM_ SG_ 661 UI_SystemMemUsage "Monitors system memory usage";
CM_ SG_ 661 UI_QtCarMemUsage "Monitors memory usage of the primary User Interface application";
CM_ SG_ 661 UI_QtCarCPUUsage "Monitors CPU usage of the primary User Interface application";
CM_ SG_ 661 UI_emmcStatus "Touchscreen user interface computer: emmc status";
CM_ SG_ 661 UI_SystemCPUUsage "Monitors system CPU usage";
CM_ SG_ 661 UI_HomeHealth "Touchscreen user interface computer: home health";
CM_ SG_ 661 UI_VarHealth "Touchscreen user interface computer: var health";
CM_ SG_ 661 UI_LogHealth "Touchscreen user interface computer: log health";
CM_ SG_ 661 UI_TmpfsHealth "Touchscreen user interface computer: tmpfs health";
CM_ SG_ 661 UI_emmcDataWritten "Touchscreen user interface computer: emmc data written";
CM_ SG_ 661 UI_emmcTotalErases "Touchscreen user interface computer: emmc total erases";
CM_ BO_ 1263 "Touchscreen user interface computer message: trip planner info";
CM_ SG_ 1263 UI_fwHeatOnNavArrivalSOE "Energy percentages shown in the UI";
CM_ SG_ 1263 UI_voyagerHeatOnNavArrivalSOE "Energy percentages shown in the UI";
CM_ SG_ 1263 UI_usingVoyagerPreconditioning "Touchscreen user interface computer: using voyager preconditioning";
CM_ BO_ 139 "Touchscreen user interface computer message: trip planning2";
CM_ SG_ 139 UI_maxSpeedToReachDestination "maximum speed to reach destination without significant risk of running out of energy; raw 65535 = signal not available (SNA)";
CM_ SG_ 139 UI_remainingWeightedRMSSpeed "Touchscreen user interface computer: remaining weighted RMS speed; raw 65535 = signal not available (SNA)";
CM_ SG_ 139 UI_timeToDestination "remaining time to reach destination; raw 65535 = signal not available (SNA)";
CM_ BO_ 1173 "Touchscreen user interface computer message: trip planning3";
CM_ SG_ 1173 UI_predictedEnergy "initially predicted energy in kWh for current location along navigation route; raw 32768 = signal not available (SNA)";
CM_ SG_ 1173 UI_predictedEnergyLearned "Touchscreen user interface computer: predicted energy learned; raw 32768 = signal not available (SNA)";
CM_ SG_ 1173 UI_hindsightEnergy "hindsight energy, the model predicted energy based on measured speed and acceleration for the current location along navigation route; raw 32768 = signal not available (SNA)";
CM_ SG_ 1173 UI_hindsightEnergyLearned "Touchscreen user interface computer: hindsight energy learned; raw 32768 = signal not available (SNA)";
CM_ BO_ 1174 "Touchscreen user interface computer message: trip planning4";
CM_ SG_ 1174 UI_longTermEnergyModelError "Touchscreen user interface computer: long term energy model error; raw 128 = signal not available (SNA)";
CM_ SG_ 1174 UI_longTermRmsSpeedRatio "Touchscreen user interface computer: long term rms speed ratio; raw 255 = signal not available (SNA)";
CM_ SG_ 1174 UI_gradeCorrectedEnergy "Touchscreen user interface computer: grade corrected energy; raw 32768 = signal not available (SNA)";
CM_ SG_ 1174 UI_gradeCorrectedEnergyLearned "Touchscreen user interface computer: grade corrected energy learned; raw 32768 = signal not available (SNA)";
CM_ BO_ 1175 "Touchscreen user interface computer message: trip planning5";
CM_ SG_ 1175 UI_battPreconditionOnNavTime "Touchscreen user interface computer: batt precondition on nav time; raw 65535 = signal not available (SNA)";
CM_ SG_ 1175 UI_maxBattPreconditionOnNavTime "Touchscreen user interface computer: max batt precondition on nav time; raw 65535 = signal not available (SNA)";
CM_ BO_ 649 "Left body controller message: logging10 hz";
CM_ SG_ 649 VCLEFT_logging10HzIndex "Left body controller: logging10 hz index";
CM_ SG_ 649 VCLEFT_hvacBlowerRs "Left body controller: hvac blower rs; raw 255 = signal not available (SNA)";
CM_ SG_ 649 VCLEFT_hvacBlowerIPhase0 "Left body controller: hvac blower i phase0; raw 127 = signal not available (SNA)";
CM_ SG_ 649 VCLEFT_hvacBlowerIPhase1 "Left body controller: hvac blower i phase1; raw 127 = signal not available (SNA)";
CM_ SG_ 649 VCLEFT_hvacBlowerIPhase2 "Left body controller: hvac blower i phase2; raw 127 = signal not available (SNA)";
CM_ SG_ 649 VCLEFT_hvacBlower_IO_CBC_HEAD "Left body controller: hvac blower IO CBC HEAD";
CM_ SG_ 649 VCLEFT_hvacBlower_IO_CBC_TAIL "Left body controller: hvac blower IO CBC TAIL";
CM_ SG_ 649 VCLEFT_hvacBlower_IO_CBC_TAIL_va "Left body controller: hvac blower IO CBC TAIL valid";
CM_ SG_ 649 VCLEFT_hvacBlower_IO_CBC_Status "Left body controller: hvac blower IO CBC status";
CM_ SG_ 649 VCLEFT_hvacBlower_IO_CBC_numUart "Left body controller: hvac blower IO CBC num uart err";
CM_ SG_ 649 VCLEFT_hvacBlowerCBCEstState "Left body controller: hvac blower CBC est state";
CM_ SG_ 649 VCLEFT_hvacBlowerCBCCtrlState "Left body controller: hvac blower CBC ctrl state";
CM_ SG_ 649 VCLEFT_hvacBlowerITerm "Left body controller: hvac blower i term; raw 127 = signal not available (SNA)";
CM_ SG_ 649 VCLEFT_hvacBlowerSpiError "Left body controller: hvac blower spi error";
CM_ SG_ 649 VCLEFT_hvacBlowerRsOnlineActive "Left body controller: hvac blower rs online active";
CM_ BO_ 1336 "VCSEAT2L ECU message: alert log";
CM_ SG_ 1336 VCSEAT2L_alertID "VCSEAT2L ECU: alert ID";
CM_ SG_ 1336 VCSEAT2L_alertState "VCSEAT2L ECU: alert state";
CM_ SG_ 1336 VCSEAT2L_a001_InternalWatchdog "VCSEAT2L ECU: a001 internal watchdog";
CM_ SG_ 1336 VCSEAT2L_a010_UnderVoltDetected "VCSEAT2L ECU: a010 under volt detected";
CM_ SG_ 1336 VCSEAT2L_a010_UnderVoltTimeout "VCSEAT2L ECU: a010 under volt timeout";
CM_ SG_ 1336 VCSEAT2L_a015_NVMMMemOverflow "VCSEAT2L ECU: a015 NVMM mem overflow";
CM_ SG_ 1336 VCSEAT2L_a015_NVMMFilesystemErro "VCSEAT2L ECU: a015 NVMM filesystem error";
CM_ SG_ 1336 VCSEAT2L_a015_NVMMRecordIDError "VCSEAT2L ECU: a015 NVMM record ID error";
CM_ SG_ 1336 VCSEAT2L_a057_VEH_cpControl "VCSEAT2L ECU: a057 VEH cp control";
CM_ SG_ 1336 VCSEAT2L_a059_voltageDrop "VCSEAT2L ECU: a059 voltage drop";
CM_ SG_ 1336 VCSEAT2L_a059_resistanceEstimate "VCSEAT2L ECU: a059 resistance estimate";
CM_ SG_ 1336 VCSEAT2L_a059_current "VCSEAT2L ECU: a059 current";
CM_ SG_ 1336 VCSEAT2L_a063_switchChannel "VCSEAT2L ECU: a063 switch channel";
CM_ SG_ 1336 VCSEAT2L_a063_switchType "VCSEAT2L ECU: a063 switch type";
CM_ SG_ 1336 VCSEAT2L_a063_ADCVoltage "VCSEAT2L ECU: a063 ADC voltage";
CM_ SG_ 1336 VCSEAT2L_a063_disconnected "VCSEAT2L ECU: a063 disconnected";
CM_ SG_ 1336 VCSEAT2L_a063_indeterminate "VCSEAT2L ECU: a063 indeterminate";
CM_ SG_ 1336 VCSEAT2L_a063_stuckActive "VCSEAT2L ECU: a063 stuck active";
CM_ SG_ 1336 VCSEAT2L_a063_faulted "VCSEAT2L ECU: a063 faulted";
CM_ SG_ 1336 VCSEAT2L_a082_RIPC_epbPrivateSta "VCSEAT2L ECU: a082 RIPC epb private state";
CM_ SG_ 1336 VCSEAT2L_a082_RIPC_remoteHSD "VCSEAT2L ECU: a082 RIPC remote HSD";
CM_ SG_ 1336 VCSEAT2L_a082_RIPC_railStatus "VCSEAT2L ECU: a082 RIPC rail status";
CM_ SG_ 1336 VCSEAT2L_a082_RIPC_remoteMux "VCSEAT2L ECU: a082 RIPC remote mux";
CM_ SG_ 1336 VCSEAT2L_a083_LIPC_epbPrivateSta "VCSEAT2L ECU: a083 LIPC epb private state";
CM_ SG_ 1336 VCSEAT2L_a083_LIPC_remoteHSD "VCSEAT2L ECU: a083 LIPC remote HSD";
CM_ SG_ 1336 VCSEAT2L_a083_LIPC_railStatus "VCSEAT2L ECU: a083 LIPC rail status";
CM_ SG_ 1336 VCSEAT2L_a083_LIPC_HSDFaults "VCSEAT2L ECU: a083 LIPC HSD faults";
CM_ SG_ 1336 VCSEAT2L_a084_CH_StatusC "VCSEAT2L ECU: a084 CH status c";
CM_ SG_ 1336 VCSEAT2L_a085_PARTY_buttonStatus "VCSEAT2L ECU: a085 PARTY button status";
CM_ SG_ 1336 VCSEAT2L_a086_VEH_LVBMS_statusHi "VCSEAT2L ECU: a086 VEH LVBMS status high";
CM_ SG_ 1336 VCSEAT2L_a086_VEH_LVBMS_statusLo "VCSEAT2L ECU: a086 VEH LVBMS status low";
CM_ SG_ 1336 VCSEAT2L_a086_VEH_status "VCSEAT2L ECU: a086 VEH status";
CM_ SG_ 1336 VCSEAT2L_a086_VEH_12VBatteryStat "VCSEAT2L ECU: a086 VEH 12 v battery status";
CM_ SG_ 1336 VCSEAT2L_a086_VEH_LVPowerState "VCSEAT2L ECU: a086 VEH LV power state";
CM_ SG_ 1336 VCSEAT2L_a086_VEH_lightStatus "VCSEAT2L ECU: a086 VEH light status";
CM_ SG_ 1336 VCSEAT2L_a086_VEH_systemStatus "VCSEAT2L ECU: a086 VEH system status";
CM_ SG_ 1336 VCSEAT2L_a086_VEH_thermalStatus "VCSEAT2L ECU: a086 VEH thermal status";
CM_ SG_ 1336 VCSEAT2L_a086_VEH_vehNm "VCSEAT2L ECU: a086 VEH veh nm";
CM_ SG_ 1336 VCSEAT2L_a087_VEH_temperature "VCSEAT2L ECU: a087 VEH temperature";
CM_ SG_ 1336 VCSEAT2L_a087_VEH_thermalControl "VCSEAT2L ECU: a087 VEH thermal control";
CM_ SG_ 1336 VCSEAT2L_a087_VEH_torque "VCSEAT2L ECU: a087 VEH torque";
CM_ SG_ 1336 VCSEAT2L_a087_VEH_status "VCSEAT2L ECU: a087 VEH status";
CM_ SG_ 1336 VCSEAT2L_a087_PARTY_torque "VCSEAT2L ECU: a087 PARTY torque";
CM_ SG_ 1336 VCSEAT2L_a087_PARTY_status "VCSEAT2L ECU: a087 PARTY status";
CM_ SG_ 1336 VCSEAT2L_a087_PARTY_temperature "VCSEAT2L ECU: a087 PARTY temperature";
CM_ SG_ 1336 VCSEAT2L_a087_PARTY_thermalContr "VCSEAT2L ECU: a087 PARTY thermal control";
CM_ SG_ 1336 VCSEAT2L_a087_VEH_motorStatus "VCSEAT2L ECU: a087 VEH motor status";
CM_ SG_ 1336 VCSEAT2L_a088_VEH_temperature "VCSEAT2L ECU: a088 VEH temperature";
CM_ SG_ 1336 VCSEAT2L_a088_VEH_thermalControl "VCSEAT2L ECU: a088 VEH thermal control";
CM_ SG_ 1336 VCSEAT2L_a088_VEH_torque "VCSEAT2L ECU: a088 VEH torque";
CM_ SG_ 1336 VCSEAT2L_a088_VEH_status "VCSEAT2L ECU: a088 VEH status";
CM_ SG_ 1336 VCSEAT2L_a088_PARTY_torque "VCSEAT2L ECU: a088 PARTY torque";
CM_ SG_ 1336 VCSEAT2L_a088_PARTY_status "VCSEAT2L ECU: a088 PARTY status";
CM_ SG_ 1336 VCSEAT2L_a088_PARTY_temperature "VCSEAT2L ECU: a088 PARTY temperature";
CM_ SG_ 1336 VCSEAT2L_a088_PARTY_thermalContr "VCSEAT2L ECU: a088 PARTY thermal control";
CM_ SG_ 1336 VCSEAT2L_a088_VEH_motorStatus "VCSEAT2L ECU: a088 VEH motor status";
CM_ SG_ 1336 VCSEAT2L_a089_PARTY_party1 "VCSEAT2L ECU: a089 PARTY party1";
CM_ SG_ 1336 VCSEAT2L_a089_PARTY_status "VCSEAT2L ECU: a089 PARTY status";
CM_ SG_ 1336 VCSEAT2L_a089_VEH_status "VCSEAT2L ECU: a089 VEH status";
CM_ SG_ 1336 VCSEAT2L_a089_BDY_party1 "VCSEAT2L ECU: a089 BDY party1";
CM_ SG_ 1336 VCSEAT2L_a089_BDY_status "VCSEAT2L ECU: a089 BDY status";
CM_ SG_ 1336 VCSEAT2L_a089_CH_status "VCSEAT2L ECU: a089 CH status";
CM_ SG_ 1336 VCSEAT2L_a089_CH_party1 "VCSEAT2L ECU: a089 CH party1";
CM_ SG_ 1336 VCSEAT2L_a089_CH_party3 "VCSEAT2L ECU: a089 CH party3";
CM_ SG_ 1336 VCSEAT2L_a089_VEH_party1 "VCSEAT2L ECU: a089 VEH party1";
CM_ SG_ 1336 VCSEAT2L_a089_VEH_party3 "VCSEAT2L ECU: a089 VEH party3";
CM_ SG_ 1336 VCSEAT2L_a091_VEH_faultsAndExtra "VCSEAT2L ECU: a091 VEH faults and extras";
CM_ SG_ 1336 VCSEAT2L_a091_VEH_info "VCSEAT2L ECU: a091 VEH info";
CM_ SG_ 1336 VCSEAT2L_a091_VEH_state "VCSEAT2L ECU: a091 VEH state";
CM_ SG_ 1336 VCSEAT2L_a092_VEH_restraintStatu "VCSEAT2L ECU: a092 VEH restraint status";
CM_ SG_ 1336 VCSEAT2L_a092_VEH_switchStatus "VCSEAT2L ECU: a092 VEH switch status";
CM_ SG_ 1336 VCSEAT2L_a092_VEH_seatStatus2 "VCSEAT2L ECU: a092 VEH seat status2";
CM_ SG_ 1336 VCSEAT2L_a092_VEH_vehNm "VCSEAT2L ECU: a092 VEH veh nm";
CM_ SG_ 1336 VCSEAT2L_a093_VEH_restraintStatu "VCSEAT2L ECU: a093 VEH restraint status";
CM_ SG_ 1336 VCSEAT2L_a093_VEH_switchStatus "VCSEAT2L ECU: a093 VEH switch status";
CM_ SG_ 1336 VCSEAT2L_a093_VEH_seatStatus2 "VCSEAT2L ECU: a093 VEH seat status2";
CM_ SG_ 1336 VCSEAT2L_a093_VEH_vehNm "VCSEAT2L ECU: a093 VEH veh nm";
CM_ SG_ 1336 VCSEAT2L_a094_VEH_sysStatus "VCSEAT2L ECU: a094 VEH sys status";
CM_ SG_ 1336 VCSEAT2L_a094_PARTY_sysStatus "VCSEAT2L ECU: a094 PARTY sys status";
CM_ SG_ 1336 VCSEAT2L_a094_CH_sysStatus "VCSEAT2L ECU: a094 CH sys status";
CM_ SG_ 1336 VCSEAT2L_a095_PT_ptNm "VCSEAT2L ECU: a095 PT pt nm";
CM_ SG_ 1336 VCSEAT2L_a095_PT_status "VCSEAT2L ECU: a095 PT status";
CM_ SG_ 1336 VCSEAT2L_a096_VEH_status "VCSEAT2L ECU: a096 VEH status";
CM_ SG_ 1336 VCSEAT2L_a096_CH_status "VCSEAT2L ECU: a096 CH status";
CM_ SG_ 1336 VCSEAT2L_a097_VEH_HVStatus "VCSEAT2L ECU: a097 VEH HV status";
CM_ SG_ 1336 VCSEAT2L_a097_VEH_state "VCSEAT2L ECU: a097 VEH state";
CM_ SG_ 1336 VCSEAT2L_a098_CH_torque "VCSEAT2L ECU: a098 CH torque";
CM_ SG_ 1336 VCSEAT2L_a098_VEH_hvStatus "VCSEAT2L ECU: a098 VEH hv status";
CM_ SG_ 1336 VCSEAT2L_a098_VEH_status "VCSEAT2L ECU: a098 VEH status";
CM_ SG_ 1336 VCSEAT2L_a098_VEH_thermalControl "VCSEAT2L ECU: a098 VEH thermal control";
CM_ SG_ 1336 VCSEAT2L_a098_VEH_temperature "VCSEAT2L ECU: a098 VEH temperature";
CM_ SG_ 1336 VCSEAT2L_a098_VEH_torque "VCSEAT2L ECU: a098 VEH torque";
CM_ SG_ 1336 VCSEAT2L_a098_PARTY_status "VCSEAT2L ECU: a098 PARTY status";
CM_ SG_ 1336 VCSEAT2L_a098_PARTY_temperature "VCSEAT2L ECU: a098 PARTY temperature";
CM_ SG_ 1336 VCSEAT2L_a098_PARTY_thermalContr "VCSEAT2L ECU: a098 PARTY thermal control";
CM_ SG_ 1336 VCSEAT2L_a098_PARTY_torque "VCSEAT2L ECU: a098 PARTY torque";
CM_ SG_ 1336 VCSEAT2L_a098_PT_thermalControl "VCSEAT2L ECU: a098 PT thermal control";
CM_ SG_ 1336 VCSEAT2L_a098_PT_temperature "VCSEAT2L ECU: a098 PT temperature";
CM_ SG_ 1336 VCSEAT2L_a098_PARTY_motorStatus "VCSEAT2L ECU: a098 PARTY motor status";
CM_ SG_ 1336 VCSEAT2L_a098_VEH_motorStatus "VCSEAT2L ECU: a098 VEH motor status";
CM_ SG_ 1336 VCSEAT2L_a099_VEH_oocStatus "VCSEAT2L ECU: a099 VEH ooc status";
CM_ SG_ 1336 VCSEAT2L_a100_VEH "VCSEAT2L ECU: a100 VEH";
CM_ SG_ 1336 VCSEAT2L_a100_PARTY "VCSEAT2L ECU: a100 PARTY";
CM_ SG_ 1336 VCSEAT2L_a100_PT "VCSEAT2L ECU: a100 PT";
CM_ SG_ 1336 VCSEAT2L_a100_CH "VCSEAT2L ECU: a100 CH";
CM_ SG_ 1336 VCSEAT2L_a100_OBD "VCSEAT2L ECU: a100 OBD";
CM_ SG_ 1336 VCSEAT2L_a101_VEH_state "VCSEAT2L ECU: a101 VEH state";
CM_ SG_ 1336 VCSEAT2L_a101_PARTY_locState "VCSEAT2L ECU: a101 PARTY loc state";
CM_ SG_ 1336 VCSEAT2L_a101_LIPC_externalWatch "VCSEAT2L ECU: a101 LIPC external watchdog heart beat";
CM_ SG_ 1336 VCSEAT2L_a101_VEH_locState "VCSEAT2L ECU: a101 VEH loc state";
CM_ SG_ 1336 VCSEAT2L_a101_BDY_locState "VCSEAT2L ECU: a101 BDY loc state";
CM_ SG_ 1336 VCSEAT2L_a102_VEH_faultsAndExtra "VCSEAT2L ECU: a102 VEH faults and extras";
CM_ SG_ 1336 VCSEAT2L_a102_VEH_feedbackStatus "VCSEAT2L ECU: a102 VEH feedback status";
CM_ SG_ 1336 VCSEAT2L_a102_VEH_sensorStatus "VCSEAT2L ECU: a102 VEH sensor status";
CM_ SG_ 1336 VCSEAT2L_a102_VEH_rods "VCSEAT2L ECU: a102 VEH rods";
CM_ SG_ 1336 VCSEAT2L_a103_VEH_hvsNm "VCSEAT2L ECU: a103 VEH hvs nm";
CM_ SG_ 1336 VCSEAT2L_a103_VEH_vehNm "VCSEAT2L ECU: a103 VEH veh nm";
CM_ SG_ 1336 VCSEAT2L_a103_VEH_status "VCSEAT2L ECU: a103 VEH status";
CM_ SG_ 1336 VCSEAT2L_a103_PT_ptNm "VCSEAT2L ECU: a103 PT pt nm";
CM_ SG_ 1336 VCSEAT2L_a103_PT_status "VCSEAT2L ECU: a103 PT status";
CM_ SG_ 1336 VCSEAT2L_a103_VEH_evseStatus "VCSEAT2L ECU: a103 VEH evse status";
CM_ SG_ 1336 VCSEAT2L_a105_VEH_states "VCSEAT2L ECU: a105 VEH states";
CM_ SG_ 1336 VCSEAT2L_a105_VEH_chNm "VCSEAT2L ECU: a105 VEH ch nm";
CM_ SG_ 1336 VCSEAT2L_a105_VEH_dampingStates "VCSEAT2L ECU: a105 VEH damping states";
CM_ SG_ 1336 VCSEAT2L_a106_VEH_dcdcStatus "VCSEAT2L ECU: a106 VEH dcdc status";
CM_ SG_ 1336 VCSEAT2L_a106_VEH_thermalControl "VCSEAT2L ECU: a106 VEH thermal control";
CM_ SG_ 1336 VCSEAT2L_a106_VEH_dcdcRailStatus "VCSEAT2L ECU: a106 VEH dcdc rail status";
CM_ SG_ 1336 VCSEAT2L_a106_CH_dcdcRailStatus "VCSEAT2L ECU: a106 CH dcdc rail status";
CM_ SG_ 1336 VCSEAT2L_a106_CH_alertMatrix "VCSEAT2L ECU: a106 CH alert matrix";
CM_ SG_ 1336 VCSEAT2L_a107_VEH_hvsNm "VCSEAT2L ECU: a107 VEH hvs nm";
CM_ SG_ 1336 VCSEAT2L_a107_VEH_vehNm "VCSEAT2L ECU: a107 VEH veh nm";
CM_ SG_ 1336 VCSEAT2L_a107_VEH_status "VCSEAT2L ECU: a107 VEH status";
CM_ SG_ 1336 VCSEAT2L_a107_VEH_thermalStatus "VCSEAT2L ECU: a107 VEH thermal status";
CM_ SG_ 1336 VCSEAT2L_a107_VEH_bmbMinMax "VCSEAT2L ECU: a107 VEH bmb min max";
CM_ SG_ 1336 VCSEAT2L_a107_VEH_powerAvailable "VCSEAT2L ECU: a107 VEH power available";
CM_ SG_ 1336 VCSEAT2L_a107_PT_ptNm "VCSEAT2L ECU: a107 PT pt nm";
CM_ SG_ 1336 VCSEAT2L_a107_PT_status "VCSEAT2L ECU: a107 PT status";
CM_ SG_ 1336 VCSEAT2L_a107_PT_thermalStatus "VCSEAT2L ECU: a107 PT thermal status";
CM_ SG_ 1336 VCSEAT2L_a107_PT_socStatus "VCSEAT2L ECU: a107 PT soc status";
CM_ SG_ 1336 VCSEAT2L_a107_VEH_socStatus "VCSEAT2L ECU: a107 VEH soc status";
CM_ SG_ 1336 VCSEAT2L_a107_VEH_packConfig "VCSEAT2L ECU: a107 VEH pack config";
CM_ SG_ 1336 VCSEAT2L_a107_VEH_energyStatus "VCSEAT2L ECU: a107 VEH energy status";
CM_ SG_ 1336 VCSEAT2L_a107_VEH_chargeInfo "VCSEAT2L ECU: a107 VEH charge info";
CM_ SG_ 1336 VCSEAT2L_a108_VEH_hvStatus "VCSEAT2L ECU: a108 VEH hv status";
CM_ SG_ 1336 VCSEAT2L_a108_VEH_temperature "VCSEAT2L ECU: a108 VEH temperature";
CM_ SG_ 1336 VCSEAT2L_a108_VEH_thermalControl "VCSEAT2L ECU: a108 VEH thermal control";
CM_ SG_ 1336 VCSEAT2L_a108_VEH_torque "VCSEAT2L ECU: a108 VEH torque";
CM_ SG_ 1336 VCSEAT2L_a108_VEH_status "VCSEAT2L ECU: a108 VEH status";
CM_ SG_ 1336 VCSEAT2L_a108_PARTY_torque "VCSEAT2L ECU: a108 PARTY torque";
CM_ SG_ 1336 VCSEAT2L_a108_PARTY_status "VCSEAT2L ECU: a108 PARTY status";
CM_ SG_ 1336 VCSEAT2L_a108_PARTY_temperature "VCSEAT2L ECU: a108 PARTY temperature";
CM_ SG_ 1336 VCSEAT2L_a108_PARTY_thermalContr "VCSEAT2L ECU: a108 PARTY thermal control";
CM_ SG_ 1336 VCSEAT2L_a108_PT_temperature "VCSEAT2L ECU: a108 PT temperature";
CM_ SG_ 1336 VCSEAT2L_a108_PT_thermalControl "VCSEAT2L ECU: a108 PT thermal control";
CM_ SG_ 1336 VCSEAT2L_a108_PARTY_motorStatus "VCSEAT2L ECU: a108 PARTY motor status";
CM_ SG_ 1336 VCSEAT2L_a108_VEH_motorStatus "VCSEAT2L ECU: a108 VEH motor status";
CM_ SG_ 1336 VCSEAT2L_a108_CH_torque "VCSEAT2L ECU: a108 CH torque";
CM_ SG_ 1336 VCSEAT2L_a110_VEH_carState "VCSEAT2L ECU: a110 VEH car state";
CM_ SG_ 1336 VCSEAT2L_a110_VEH_carConfig "VCSEAT2L ECU: a110 VEH car config";
CM_ SG_ 1336 VCSEAT2L_a110_VEH_time "VCSEAT2L ECU: a110 VEH time";
CM_ SG_ 1336 VCSEAT2L_a110_VEH_updateStatus "VCSEAT2L ECU: a110 VEH update status";
CM_ SG_ 1336 VCSEAT2L_a110_VEH_vehNm "VCSEAT2L ECU: a110 VEH veh nm";
CM_ SG_ 1336 VCSEAT2L_a110_VEH_mismatchFault "VCSEAT2L ECU: a110 VEH mismatch fault";
CM_ SG_ 1336 VCSEAT2L_a110_VEH_vin "VCSEAT2L ECU: a110 VEH vin";
CM_ SG_ 1336 VCSEAT2L_a110_VEH_bmpDebug "VCSEAT2L ECU: a110 VEH bmp debug";
CM_ SG_ 1336 VCSEAT2L_a110_VEH_gearControl "VCSEAT2L ECU: a110 VEH gear control";
CM_ SG_ 1336 VCSEAT2L_a110_VEH_canLogAvailabi "VCSEAT2L ECU: a110 VEH can log availability";
CM_ SG_ 1336 VCSEAT2L_a110_CH_airbagCutoffSta "VCSEAT2L ECU: a110 CH airbag cutoff status";
CM_ SG_ 1336 VCSEAT2L_a110_CH_carConfig "VCSEAT2L ECU: a110 CH car config";
CM_ SG_ 1336 VCSEAT2L_a110_CH_carState "VCSEAT2L ECU: a110 CH car state";
CM_ SG_ 1336 VCSEAT2L_a110_CH_vin "VCSEAT2L ECU: a110 CH vin";
CM_ SG_ 1336 VCSEAT2L_a110_CH_chNm "VCSEAT2L ECU: a110 CH ch nm";
CM_ SG_ 1336 VCSEAT2L_a110_CH_epochTimeGtw "VCSEAT2L ECU: a110 CH epoch time gtw";
CM_ SG_ 1336 VCSEAT2L_a110_PARTY_carConfig "VCSEAT2L ECU: a110 PARTY car config";
CM_ SG_ 1336 VCSEAT2L_a111_VEH_internalStatus "VCSEAT2L ECU: a111 VEH internal status";
CM_ SG_ 1336 VCSEAT2L_a111_VEH_status "VCSEAT2L ECU: a111 VEH status";
CM_ SG_ 1336 VCSEAT2L_a111_VEH_vehNm "VCSEAT2L ECU: a111 VEH veh nm";
CM_ SG_ 1336 VCSEAT2L_a111_RIPC_LVPowerState "VCSEAT2L ECU: a111 RIPC LV power state";
CM_ SG_ 1336 VCSEAT2L_a111_RIPC_epbPrivateSta "VCSEAT2L ECU: a111 RIPC epb private state";
CM_ SG_ 1336 VCSEAT2L_a111_RIPC_railStatus "VCSEAT2L ECU: a111 RIPC rail status";
CM_ SG_ 1336 VCSEAT2L_a111_RIPC_remoteADC "VCSEAT2L ECU: a111 RIPC remote ADC";
CM_ SG_ 1336 VCSEAT2L_a111_RIPC_switchStatus "VCSEAT2L ECU: a111 RIPC switch status";
CM_ SG_ 1336 VCSEAT2L_a111_VEH_LVPowerState "VCSEAT2L ECU: a111 VEH LV power state";
CM_ SG_ 1336 VCSEAT2L_a111_VEH_seatStatus "VCSEAT2L ECU: a111 VEH seat status";
CM_ SG_ 1336 VCSEAT2L_a111_PARTY_status "VCSEAT2L ECU: a111 PARTY status";
CM_ SG_ 1336 VCSEAT2L_a111_CH_status "VCSEAT2L ECU: a111 CH status";
CM_ SG_ 1336 VCSEAT2L_a112_VEH_internalStatus "VCSEAT2L ECU: a112 VEH internal status";
CM_ SG_ 1336 VCSEAT2L_a112_VEH_status "VCSEAT2L ECU: a112 VEH status";
CM_ SG_ 1336 VCSEAT2L_a112_VEH_vehNm "VCSEAT2L ECU: a112 VEH veh nm";
CM_ SG_ 1336 VCSEAT2L_a112_LIPC_LVPowerState "VCSEAT2L ECU: a112 LIPC LV power state";
CM_ SG_ 1336 VCSEAT2L_a112_LIPC_epbPrivateSta "VCSEAT2L ECU: a112 LIPC epb private state";
CM_ SG_ 1336 VCSEAT2L_a112_LIPC_railStatus "VCSEAT2L ECU: a112 LIPC rail status";
CM_ SG_ 1336 VCSEAT2L_a112_LIPC_remoteADC "VCSEAT2L ECU: a112 LIPC remote ADC";
CM_ SG_ 1336 VCSEAT2L_a112_LIPC_switchStatus "VCSEAT2L ECU: a112 LIPC switch status";
CM_ SG_ 1336 VCSEAT2L_a112_VEH_LVPowerState "VCSEAT2L ECU: a112 VEH LV power state";
CM_ SG_ 1336 VCSEAT2L_a112_PARTY_status "VCSEAT2L ECU: a112 PARTY status";
CM_ SG_ 1336 VCSEAT2L_a112_CH_status "VCSEAT2L ECU: a112 CH status";
CM_ SG_ 1336 VCSEAT2L_a114_PARTY_status "VCSEAT2L ECU: a114 PARTY status";
CM_ SG_ 1336 VCSEAT2L_a114_PARTY_wheelSpeeds "VCSEAT2L ECU: a114 PARTY wheel speeds";
CM_ SG_ 1336 VCSEAT2L_a114_VEH_wheelSpeeds "VCSEAT2L ECU: a114 VEH wheel speeds";
CM_ SG_ 1336 VCSEAT2L_a114_CH_wheelSpeeds "VCSEAT2L ECU: a114 CH wheel speeds";
CM_ SG_ 1336 VCSEAT2L_a114_PARTY_party3 "VCSEAT2L ECU: a114 PARTY party3";
CM_ SG_ 1336 VCSEAT2L_a114_VEH_party3 "VCSEAT2L ECU: a114 VEH party3";
CM_ SG_ 1336 VCSEAT2L_a114_VEH_status "VCSEAT2L ECU: a114 VEH status";
CM_ SG_ 1336 VCSEAT2L_a114_PARTY_wheelRotatio "VCSEAT2L ECU: a114 PARTY wheel rotation";
CM_ SG_ 1336 VCSEAT2L_a114_CH_wheelRotation "VCSEAT2L ECU: a114 CH wheel rotation";
CM_ SG_ 1336 VCSEAT2L_a114_VEH_wheelRotation "VCSEAT2L ECU: a114 VEH wheel rotation";
CM_ SG_ 1336 VCSEAT2L_a114_PARTY_brakeTorque "VCSEAT2L ECU: a114 PARTY brake torque";
CM_ SG_ 1336 VCSEAT2L_a114_PARTY_offsets "VCSEAT2L ECU: a114 PARTY offsets";
CM_ SG_ 1336 VCSEAT2L_a114_BDY_offsets "VCSEAT2L ECU: a114 BDY offsets";
CM_ SG_ 1336 VCSEAT2L_a114_BDY_party3 "VCSEAT2L ECU: a114 BDY party3";
CM_ SG_ 1336 VCSEAT2L_a114_BDY_status "VCSEAT2L ECU: a114 BDY status";
CM_ SG_ 1336 VCSEAT2L_a114_BDY_wheelRotation "VCSEAT2L ECU: a114 BDY wheel rotation";
CM_ SG_ 1336 VCSEAT2L_a114_BDY_wheelSpeeds "VCSEAT2L ECU: a114 BDY wheel speeds";
CM_ SG_ 1336 VCSEAT2L_a114_CH_party1 "VCSEAT2L ECU: a114 CH party1";
CM_ SG_ 1336 VCSEAT2L_a114_CH_party3 "VCSEAT2L ECU: a114 CH party3";
CM_ SG_ 1336 VCSEAT2L_a114_CH_status "VCSEAT2L ECU: a114 CH status";
CM_ SG_ 1336 VCSEAT2L_a115_VEH_vehNm "VCSEAT2L ECU: a115 VEH veh nm";
CM_ SG_ 1336 VCSEAT2L_a115_VEH_authentication "VCSEAT2L ECU: a115 VEH authentication";
CM_ SG_ 1336 VCSEAT2L_a115_VEH_BLEResetReques "VCSEAT2L ECU: a115 VEH BLE reset request";
CM_ SG_ 1336 VCSEAT2L_a115_VEH_requests "VCSEAT2L ECU: a115 VEH requests";
CM_ SG_ 1336 VCSEAT2L_a115_VEH_requests2 "VCSEAT2L ECU: a115 VEH requests2";
CM_ SG_ 1336 VCSEAT2L_a115_REM_authentication "VCSEAT2L ECU: a115 REM authentication";
CM_ SG_ 1336 VCSEAT2L_a115_UI_corianderVehicl "VCSEAT2L ECU: a115 UI coriander vehicle control";
CM_ SG_ 1336 VCSEAT2L_a115_CH_TPMSDisplay "VCSEAT2L ECU: a115 CH TPMS display";
CM_ SG_ 1336 VCSEAT2L_a116_PARTY_epbmStatus "VCSEAT2L ECU: a116 PARTY epbm status";
CM_ SG_ 1336 VCSEAT2L_a116_VEH_vehNm "VCSEAT2L ECU: a116 VEH veh nm";
CM_ SG_ 1336 VCSEAT2L_a116_VEH_hvacRequest "VCSEAT2L ECU: a116 VEH hvac request";
CM_ SG_ 1336 VCSEAT2L_a116_VEH_hvacStatus "VCSEAT2L ECU: a116 VEH hvac status";
CM_ SG_ 1336 VCSEAT2L_a116_VEH_LVPowerState "VCSEAT2L ECU: a116 VEH LV power state";
CM_ SG_ 1336 VCSEAT2L_a116_VEH_lightStatus "VCSEAT2L ECU: a116 VEH light status";
CM_ SG_ 1336 VCSEAT2L_a116_VEH_seatStatus "VCSEAT2L ECU: a116 VEH seat status";
CM_ SG_ 1336 VCSEAT2L_a116_VEH_thsStatus "VCSEAT2L ECU: a116 VEH ths status";
CM_ SG_ 1336 VCSEAT2L_a116_VEH_doorStatus "VCSEAT2L ECU: a116 VEH door status";
CM_ SG_ 1336 VCSEAT2L_a116_VEH_seatHeatStatus "VCSEAT2L ECU: a116 VEH seat heat status";
CM_ SG_ 1336 VCSEAT2L_a116_VEH_restraintStatu "VCSEAT2L ECU: a116 VEH restraint status";
CM_ SG_ 1336 VCSEAT2L_a116_VEH_switchStatus "VCSEAT2L ECU: a116 VEH switch status";
CM_ SG_ 1336 VCSEAT2L_a116_VEH_logging1Hz "VCSEAT2L ECU: a116 VEH logging1 hz";
CM_ SG_ 1336 VCSEAT2L_a116_VEH_seatStatus2 "VCSEAT2L ECU: a116 VEH seat status2";
CM_ SG_ 1336 VCSEAT2L_a116_VEH_status "VCSEAT2L ECU: a116 VEH status";
CM_ SG_ 1336 VCSEAT2L_a116_VEH_thermalCommand "VCSEAT2L ECU: a116 VEH thermal command";
CM_ SG_ 1336 VCSEAT2L_a116_VEH_windowStatus "VCSEAT2L ECU: a116 VEH window status";
CM_ SG_ 1336 VCSEAT2L_a116_PARTY_restraintSta "VCSEAT2L ECU: a116 PARTY restraint status";
CM_ SG_ 1336 VCSEAT2L_a116_PARTY_doorStatus "VCSEAT2L ECU: a116 PARTY door status";
CM_ SG_ 1336 VCSEAT2L_a116_BDY_epbmStatus "VCSEAT2L ECU: a116 BDY epbm status";
CM_ SG_ 1336 VCSEAT2L_a116_BDY_restraintStatu "VCSEAT2L ECU: a116 BDY restraint status";
CM_ SG_ 1336 VCSEAT2L_a116_BDY_switchStatus "VCSEAT2L ECU: a116 BDY switch status";
CM_ SG_ 1336 VCSEAT2L_a117_BDY_epbmStatus "VCSEAT2L ECU: a117 BDY epbm status";
CM_ SG_ 1336 VCSEAT2L_a117_BDY_restraintStatu "VCSEAT2L ECU: a117 BDY restraint status";
CM_ SG_ 1336 VCSEAT2L_a117_VEH_prndStatus "VCSEAT2L ECU: a117 VEH prnd status";
CM_ SG_ 1336 VCSEAT2L_a117_PARTY_epbmStatus "VCSEAT2L ECU: a117 PARTY epbm status";
CM_ SG_ 1336 VCSEAT2L_a117_VEH_vehNm "VCSEAT2L ECU: a117 VEH veh nm";
CM_ SG_ 1336 VCSEAT2L_a117_VEH_hvacBlowerFdb "VCSEAT2L ECU: a117 VEH hvac blower fdb";
CM_ SG_ 1336 VCSEAT2L_a117_VEH_LVPowerState "VCSEAT2L ECU: a117 VEH LV power state";
CM_ SG_ 1336 VCSEAT2L_a117_VEH_restraintStatu "VCSEAT2L ECU: a117 VEH restraint status";
CM_ SG_ 1336 VCSEAT2L_a117_VEH_lightStatus "VCSEAT2L ECU: a117 VEH light status";
CM_ SG_ 1336 VCSEAT2L_a117_VEH_seatStatus "VCSEAT2L ECU: a117 VEH seat status";
CM_ SG_ 1336 VCSEAT2L_a117_BDY_falconSwitchSt "VCSEAT2L ECU: a117 BDY falcon switch status";
CM_ SG_ 1336 VCSEAT2L_a117_VEH_doorStatus "VCSEAT2L ECU: a117 VEH door status";
CM_ SG_ 1336 VCSEAT2L_a117_VEH_doorStatus2 "VCSEAT2L ECU: a117 VEH door status2";
CM_ SG_ 1336 VCSEAT2L_a117_VEH_windowStatus "VCSEAT2L ECU: a117 VEH window status";
CM_ SG_ 1336 VCSEAT2L_a117_VEH_switchStatus "VCSEAT2L ECU: a117 VEH switch status";
CM_ SG_ 1336 VCSEAT2L_a117_VEH_intrusionSenso "VCSEAT2L ECU: a117 VEH intrusion sensor status";
CM_ SG_ 1336 VCSEAT2L_a117_VEH_liftgateStatus "VCSEAT2L ECU: a117 VEH liftgate status";
CM_ SG_ 1336 VCSEAT2L_a117_VEH_seatStatus2 "VCSEAT2L ECU: a117 VEH seat status2";
CM_ SG_ 1336 VCSEAT2L_a117_PARTY_restraintSta "VCSEAT2L ECU: a117 PARTY restraint status";
CM_ SG_ 1336 VCSEAT2L_a117_VEH_thermalStatus "VCSEAT2L ECU: a117 VEH thermal status";
CM_ SG_ 1336 VCSEAT2L_a117_PARTY_doorStatus "VCSEAT2L ECU: a117 PARTY door status";
CM_ SG_ 1336 VCSEAT2L_a117_VEH_status "VCSEAT2L ECU: a117 VEH status";
CM_ SG_ 1336 VCSEAT2L_a117_PARTY_prndStatus "VCSEAT2L ECU: a117 PARTY prnd status";
CM_ SG_ 1336 VCSEAT2L_a117_PARTY_lightingSeco "VCSEAT2L ECU: a117 PARTY lighting secondary";
CM_ SG_ 1336 VCSEAT2L_a118_VEH_vehNm "VCSEAT2L ECU: a118 VEH veh nm";
CM_ SG_ 1336 VCSEAT2L_a118_VEH_lighting "VCSEAT2L ECU: a118 VEH lighting";
CM_ SG_ 1336 VCSEAT2L_a118_VEH_sensors "VCSEAT2L ECU: a118 VEH sensors";
CM_ SG_ 1336 VCSEAT2L_a118_VEH_status "VCSEAT2L ECU: a118 VEH status";
CM_ SG_ 1336 VCSEAT2L_a118_VEH_okToUseHighPwr "VCSEAT2L ECU: a118 VEH ok to use high pwr";
CM_ SG_ 1336 VCSEAT2L_a118_VEH_LVPowerState "VCSEAT2L ECU: a118 VEH LV power state";
CM_ SG_ 1336 VCSEAT2L_a118_VEH_coolant "VCSEAT2L ECU: a118 VEH coolant";
CM_ SG_ 1336 VCSEAT2L_a118_VEH_vehicleStatus "VCSEAT2L ECU: a118 VEH vehicle status";
CM_ SG_ 1336 VCSEAT2L_a118_VEH_12VBatteryStat "VCSEAT2L ECU: a118 VEH 12 v battery status";
CM_ SG_ 1336 VCSEAT2L_a118_VEH_systemStatus "VCSEAT2L ECU: a118 VEH system status";
CM_ SG_ 1336 VCSEAT2L_a118_PARTY_LVPowerState "VCSEAT2L ECU: a118 PARTY LV power state";
CM_ SG_ 1336 VCSEAT2L_a118_PARTY_outputPowerS "VCSEAT2L ECU: a118 PARTY output power status";
CM_ SG_ 1336 VCSEAT2L_a118_PARTY_vehicleTime "VCSEAT2L ECU: a118 PARTY vehicle time";
CM_ SG_ 1336 VCSEAT2L_a118_VEH_thermalCommand "VCSEAT2L ECU: a118 VEH thermal command";
CM_ SG_ 1336 VCSEAT2L_a118_CH_LVPowerState "VCSEAT2L ECU: a118 CH LV power state";
CM_ SG_ 1336 VCSEAT2L_a118_PARTY_sensors "VCSEAT2L ECU: a118 PARTY sensors";
CM_ SG_ 1336 VCSEAT2L_a118_CH_sensors "VCSEAT2L ECU: a118 CH sensors";
CM_ SG_ 1336 VCSEAT2L_a118_VEH_interNodeResis "VCSEAT2L ECU: a118 VEH inter node resistance";
CM_ SG_ 1336 VCSEAT2L_a118_CH_lighting "VCSEAT2L ECU: a118 CH lighting";
CM_ SG_ 1336 VCSEAT2L_a118_VEH_lightStatus "VCSEAT2L ECU: a118 VEH light status";
CM_ SG_ 1336 VCSEAT2L_a118_PARTY_vehNm "VCSEAT2L ECU: a118 PARTY veh nm";
CM_ SG_ 1336 VCSEAT2L_a118_CH_12VBatteryStatu "VCSEAT2L ECU: a118 CH 12 v battery status";
CM_ SG_ 1336 VCSEAT2L_a118_CH_LVBMS_statusHig "VCSEAT2L ECU: a118 CH LVBMS status high";
CM_ SG_ 1336 VCSEAT2L_a118_CH_alertMatrix "VCSEAT2L ECU: a118 CH alert matrix";
CM_ SG_ 1336 VCSEAT2L_a118_BDY_outputPowerSta "VCSEAT2L ECU: a118 BDY output power status";
CM_ SG_ 1336 VCSEAT2L_a118_BDY_vehicleTime "VCSEAT2L ECU: a118 BDY vehicle time";
CM_ SG_ 1336 VCSEAT2L_a118_PARTY_AP_vehicleSt "VCSEAT2L ECU: a118 PARTY AP vehicle state1 hz muxed";
CM_ SG_ 1336 VCSEAT2L_a118_BDY_AP_vehicleStat "VCSEAT2L ECU: a118 BDY AP vehicle state1 hz muxed";
CM_ SG_ 1336 VCSEAT2L_a118_PARTY_VCFRONT_came "VCSEAT2L ECU: a118 PARTY VCFRONT camera cleaning status";
CM_ SG_ 1336 VCSEAT2L_a119_VEH_steerAngle "VCSEAT2L ECU: a119 VEH steer angle";
CM_ SG_ 1336 VCSEAT2L_a119_VEH_leftStalk "VCSEAT2L ECU: a119 VEH left stalk";
CM_ SG_ 1336 VCSEAT2L_a119_VEH_rightStalk "VCSEAT2L ECU: a119 VEH right stalk";
CM_ SG_ 1336 VCSEAT2L_a119_PARTY_rightStalk "VCSEAT2L ECU: a119 PARTY right stalk";
CM_ SG_ 1336 VCSEAT2L_a119_CH_steerAngle "VCSEAT2L ECU: a119 CH steer angle";
CM_ SG_ 1336 VCSEAT2L_a119_PARTY_steerAngle "VCSEAT2L ECU: a119 PARTY steer angle";
CM_ SG_ 1336 VCSEAT2L_a120_PARTY_chassisCntl "VCSEAT2L ECU: a120 PARTY chassis cntl";
CM_ SG_ 1336 VCSEAT2L_a120_VEH_systemStatus "VCSEAT2L ECU: a120 VEH system status";
CM_ SG_ 1336 VCSEAT2L_a120_CH_chassisCntl "VCSEAT2L ECU: a120 CH chassis cntl";
CM_ SG_ 1336 VCSEAT2L_a120_PARTY_systemStatus "VCSEAT2L ECU: a120 PARTY system status";
CM_ SG_ 1336 VCSEAT2L_a120_PARTY_torque "VCSEAT2L ECU: a120 PARTY torque";
CM_ SG_ 1336 VCSEAT2L_a120_VEH_torque "VCSEAT2L ECU: a120 VEH torque";
CM_ SG_ 1336 VCSEAT2L_a120_PARTY_locStatus "VCSEAT2L ECU: a120 PARTY loc status";
CM_ SG_ 1336 VCSEAT2L_a120_PARTY_speed "VCSEAT2L ECU: a120 PARTY speed";
CM_ SG_ 1336 VCSEAT2L_a120_VEH_speed "VCSEAT2L ECU: a120 VEH speed";
CM_ SG_ 1336 VCSEAT2L_a120_PARTY_status "VCSEAT2L ECU: a120 PARTY status";
CM_ SG_ 1336 VCSEAT2L_a120_PT_speed "VCSEAT2L ECU: a120 PT speed";
CM_ SG_ 1336 VCSEAT2L_a120_PT_systemStatus "VCSEAT2L ECU: a120 PT system status";
CM_ SG_ 1336 VCSEAT2L_a120_PARTY_vehicleEstim "VCSEAT2L ECU: a120 PARTY vehicle estimates";
CM_ SG_ 1336 VCSEAT2L_a120_VEH_aggregatedAxle "VCSEAT2L ECU: a120 VEH aggregated axle speed";
CM_ SG_ 1336 VCSEAT2L_a120_PARTY_aggregatedAx "VCSEAT2L ECU: a120 PARTY aggregated axle speed";
CM_ SG_ 1336 VCSEAT2L_a120_VEH_systemPower "VCSEAT2L ECU: a120 VEH system power";
CM_ SG_ 1336 VCSEAT2L_a120_PARTY_autonomyHeal "VCSEAT2L ECU: a120 PARTY autonomy health";
CM_ SG_ 1336 VCSEAT2L_a120_VEH_autonomyHealth "VCSEAT2L ECU: a120 VEH autonomy health";
CM_ SG_ 1336 VCSEAT2L_a120_PT_systemPower "VCSEAT2L ECU: a120 PT system power";
CM_ SG_ 1336 VCSEAT2L_a120_PARTY_stalklessInt "VCSEAT2L ECU: a120 PARTY stalkless interfaces";
CM_ SG_ 1336 VCSEAT2L_a120_CH_speed "VCSEAT2L ECU: a120 CH speed";
CM_ SG_ 1336 VCSEAT2L_a120_VEH_estimatedBrake "VCSEAT2L ECU: a120 VEH estimated brake temp";
CM_ SG_ 1336 VCSEAT2L_a120_PARTY_prndControl "VCSEAT2L ECU: a120 PARTY prnd control";
CM_ SG_ 1336 VCSEAT2L_a120_PARTY_locStatus2 "VCSEAT2L ECU: a120 PARTY loc status2";
CM_ SG_ 1336 VCSEAT2L_a120_VEH_chassisCntl "VCSEAT2L ECU: a120 VEH chassis cntl";
CM_ SG_ 1336 VCSEAT2L_a120_CH_locStatus2 "VCSEAT2L ECU: a120 CH loc status2";
CM_ SG_ 1336 VCSEAT2L_a120_VEH_locStatus "VCSEAT2L ECU: a120 VEH loc status";
CM_ SG_ 1336 VCSEAT2L_a120_VEH_locStatus2 "VCSEAT2L ECU: a120 VEH loc status2";
CM_ SG_ 1336 VCSEAT2L_a120_VEH_prndControl "VCSEAT2L ECU: a120 VEH prnd control";
CM_ SG_ 1336 VCSEAT2L_a120_VEH_vehicleEstimat "VCSEAT2L ECU: a120 VEH vehicle estimates";
CM_ SG_ 1336 VCSEAT2L_a120_PARTY_motorStatus "VCSEAT2L ECU: a120 PARTY motor status";
CM_ SG_ 1336 VCSEAT2L_a120_VEH_motorStatus "VCSEAT2L ECU: a120 VEH motor status";
CM_ SG_ 1336 VCSEAT2L_a120_BDY_speed "VCSEAT2L ECU: a120 BDY speed";
CM_ SG_ 1336 VCSEAT2L_a210_seatMotorCalibrate "VCSEAT2L ECU: a210 seat motor calibrated";
CM_ SG_ 1336 VCSEAT2L_a210_seatMotorCurrent "VCSEAT2L ECU: a210 seat motor current";
CM_ SG_ 1336 VCSEAT2L_a210_seatMotorState "VCSEAT2L ECU: a210 seat motor state";
CM_ SG_ 1336 VCSEAT2L_a210_seatSwitchBack "VCSEAT2L ECU: a210 seat switch back; raw 0 = signal not available (SNA)";
CM_ SG_ 1336 VCSEAT2L_a210_seatSwitchForward "VCSEAT2L ECU: a210 seat switch forward; raw 0 = signal not available (SNA)";
CM_ SG_ 1336 VCSEAT2L_a211_seatMotorCurrent "VCSEAT2L ECU: a211 seat motor current";
CM_ SG_ 1336 VCSEAT2L_a211_seatMotorPosReal "VCSEAT2L ECU: a211 seat motor pos real";
CM_ SG_ 1336 VCSEAT2L_a211_seatMotorState "VCSEAT2L ECU: a211 seat motor state";
CM_ SG_ 1336 VCSEAT2L_a211_seatSwitchBack "VCSEAT2L ECU: a211 seat switch back; raw 0 = signal not available (SNA)";
CM_ SG_ 1336 VCSEAT2L_a211_seatSwitchForward "VCSEAT2L ECU: a211 seat switch forward; raw 0 = signal not available (SNA)";
CM_ SG_ 1336 VCSEAT2L_a212_seatMotorCurrent "VCSEAT2L ECU: a212 seat motor current";
CM_ SG_ 1336 VCSEAT2L_a212_seatMotorPosReal "VCSEAT2L ECU: a212 seat motor pos real";
CM_ SG_ 1336 VCSEAT2L_a212_seatMotorState "VCSEAT2L ECU: a212 seat motor state";
CM_ SG_ 1336 VCSEAT2L_a212_seatSwitchBack "VCSEAT2L ECU: a212 seat switch back; raw 0 = signal not available (SNA)";
CM_ SG_ 1336 VCSEAT2L_a212_seatSwitchForward "VCSEAT2L ECU: a212 seat switch forward; raw 0 = signal not available (SNA)";
CM_ SG_ 1336 VCSEAT2L_a213_seatMotorCalibrate "VCSEAT2L ECU: a213 seat motor calibrated";
CM_ SG_ 1336 VCSEAT2L_a213_seatMotorCurrent "VCSEAT2L ECU: a213 seat motor current";
CM_ SG_ 1336 VCSEAT2L_a213_seatMotorPosReal "VCSEAT2L ECU: a213 seat motor pos real";
CM_ SG_ 1336 VCSEAT2L_a213_seatMotorState "VCSEAT2L ECU: a213 seat motor state";
CM_ SG_ 1336 VCSEAT2L_a213_seatSwitchBack "VCSEAT2L ECU: a213 seat switch back; raw 0 = signal not available (SNA)";
CM_ SG_ 1336 VCSEAT2L_a213_seatSwitchForward "VCSEAT2L ECU: a213 seat switch forward; raw 0 = signal not available (SNA)";
CM_ SG_ 1336 VCSEAT2L_a214_seatMotorCurrent "VCSEAT2L ECU: a214 seat motor current";
CM_ SG_ 1336 VCSEAT2L_a214_seatMotorDCurrent "VCSEAT2L ECU: a214 seat motor d current";
CM_ SG_ 1336 VCSEAT2L_a214_seatMotorPosReal "VCSEAT2L ECU: a214 seat motor pos real";
CM_ SG_ 1336 VCSEAT2L_a214_seatMotorState "VCSEAT2L ECU: a214 seat motor state";
CM_ SG_ 1336 VCSEAT2L_a215_seatMotorCurrent "VCSEAT2L ECU: a215 seat motor current";
CM_ SG_ 1336 VCSEAT2L_a215_seatMotorDCurrent "VCSEAT2L ECU: a215 seat motor d current";
CM_ SG_ 1336 VCSEAT2L_a215_seatMotorPosReal "VCSEAT2L ECU: a215 seat motor pos real";
CM_ SG_ 1336 VCSEAT2L_a215_seatMotorState "VCSEAT2L ECU: a215 seat motor state";
CM_ SG_ 1336 VCSEAT2L_a224_seatMotorCalibrate "VCSEAT2L ECU: a224 seat motor calibrated";
CM_ SG_ 1336 VCSEAT2L_a224_seatMotorCurrent "VCSEAT2L ECU: a224 seat motor current";
CM_ SG_ 1336 VCSEAT2L_a224_seatMotorState "VCSEAT2L ECU: a224 seat motor state";
CM_ SG_ 1336 VCSEAT2L_a224_seatSwitchBack "VCSEAT2L ECU: a224 seat switch back; raw 0 = signal not available (SNA)";
CM_ SG_ 1336 VCSEAT2L_a224_seatSwitchForward "VCSEAT2L ECU: a224 seat switch forward; raw 0 = signal not available (SNA)";
CM_ SG_ 1336 VCSEAT2L_a225_seatMotorCalibrate "VCSEAT2L ECU: a225 seat motor calibrated";
CM_ SG_ 1336 VCSEAT2L_a225_seatMotorCurrent "VCSEAT2L ECU: a225 seat motor current";
CM_ SG_ 1336 VCSEAT2L_a225_seatMotorState "VCSEAT2L ECU: a225 seat motor state";
CM_ SG_ 1336 VCSEAT2L_a225_seatSwitchBack "VCSEAT2L ECU: a225 seat switch back; raw 0 = signal not available (SNA)";
CM_ SG_ 1336 VCSEAT2L_a225_seatSwitchForward "VCSEAT2L ECU: a225 seat switch forward; raw 0 = signal not available (SNA)";
CM_ SG_ 1336 VCSEAT2L_a228_seatMotorCalibrate "VCSEAT2L ECU: a228 seat motor calibrated";
CM_ SG_ 1336 VCSEAT2L_a228_seatMotorCurrent "VCSEAT2L ECU: a228 seat motor current";
CM_ SG_ 1336 VCSEAT2L_a228_seatMotorPosReal "VCSEAT2L ECU: a228 seat motor pos real";
CM_ SG_ 1336 VCSEAT2L_a228_seatMotorState "VCSEAT2L ECU: a228 seat motor state";
CM_ SG_ 1336 VCSEAT2L_a228_seatSwitchBack "VCSEAT2L ECU: a228 seat switch back; raw 0 = signal not available (SNA)";
CM_ SG_ 1336 VCSEAT2L_a228_seatSwitchForward "VCSEAT2L ECU: a228 seat switch forward; raw 0 = signal not available (SNA)";
CM_ SG_ 1336 VCSEAT2L_a229_seatMotorCalibrate "VCSEAT2L ECU: a229 seat motor calibrated";
CM_ SG_ 1336 VCSEAT2L_a229_seatMotorCurrent "VCSEAT2L ECU: a229 seat motor current";
CM_ SG_ 1336 VCSEAT2L_a229_seatMotorPosReal "VCSEAT2L ECU: a229 seat motor pos real";
CM_ SG_ 1336 VCSEAT2L_a229_seatMotorState "VCSEAT2L ECU: a229 seat motor state";
CM_ SG_ 1336 VCSEAT2L_a229_seatSwitchBack "VCSEAT2L ECU: a229 seat switch back; raw 0 = signal not available (SNA)";
CM_ SG_ 1336 VCSEAT2L_a229_seatSwitchForward "VCSEAT2L ECU: a229 seat switch forward; raw 0 = signal not available (SNA)";
CM_ SG_ 1336 VCSEAT2L_a232_seatMotorCurrent "VCSEAT2L ECU: a232 seat motor current";
CM_ SG_ 1336 VCSEAT2L_a232_seatMotorPosReal "VCSEAT2L ECU: a232 seat motor pos real";
CM_ SG_ 1336 VCSEAT2L_a232_seatMotorState "VCSEAT2L ECU: a232 seat motor state";
CM_ SG_ 1336 VCSEAT2L_a232_seatSwitchBack "VCSEAT2L ECU: a232 seat switch back; raw 0 = signal not available (SNA)";
CM_ SG_ 1336 VCSEAT2L_a232_seatSwitchForward "VCSEAT2L ECU: a232 seat switch forward; raw 0 = signal not available (SNA)";
CM_ SG_ 1336 VCSEAT2L_a233_seatMotorCurrent "VCSEAT2L ECU: a233 seat motor current";
CM_ SG_ 1336 VCSEAT2L_a233_seatMotorPosReal "VCSEAT2L ECU: a233 seat motor pos real";
CM_ SG_ 1336 VCSEAT2L_a233_seatMotorState "VCSEAT2L ECU: a233 seat motor state";
CM_ SG_ 1336 VCSEAT2L_a233_seatSwitchBack "VCSEAT2L ECU: a233 seat switch back; raw 0 = signal not available (SNA)";
CM_ SG_ 1336 VCSEAT2L_a233_seatSwitchForward "VCSEAT2L ECU: a233 seat switch forward; raw 0 = signal not available (SNA)";
CM_ SG_ 1336 VCSEAT2L_a239_seatHeatCurrent "VCSEAT2L ECU: a239 seat heat current";
CM_ SG_ 1336 VCSEAT2L_a239_seatHeatTmp "VCSEAT2L ECU: a239 seat heat tmp";
CM_ SG_ 1336 VCSEAT2L_a239_seatHeatTmpTarget "VCSEAT2L ECU: a239 seat heat tmp target";
CM_ SG_ 1336 VCSEAT2L_a240_seatHeatCurrent "VCSEAT2L ECU: a240 seat heat current";
CM_ SG_ 1336 VCSEAT2L_a240_seatHeatTmp "VCSEAT2L ECU: a240 seat heat tmp";
CM_ SG_ 1336 VCSEAT2L_a242_snsShortCircuit "VCSEAT2L ECU: a242 sns short circuit";
CM_ SG_ 1336 VCSEAT2L_a242_snsDisconnect "VCSEAT2L ECU: a242 sns disconnect";
CM_ SG_ 1336 VCSEAT2L_a242_snsRateChangeUp "VCSEAT2L ECU: a242 sns rate change up";
CM_ SG_ 1336 VCSEAT2L_a242_snsRateChangeDown "VCSEAT2L ECU: a242 sns rate change down";
CM_ SG_ 1336 VCSEAT2L_a251_seatMotorCurrent "VCSEAT2L ECU: a251 seat motor current";
CM_ SG_ 1336 VCSEAT2L_a251_seatMotorPosReal "VCSEAT2L ECU: a251 seat motor pos real";
CM_ SG_ 1336 VCSEAT2L_a251_seatMotorState "VCSEAT2L ECU: a251 seat motor state";
CM_ SG_ 1336 VCSEAT2L_a251_seatSwitchBack "VCSEAT2L ECU: a251 seat switch back; raw 0 = signal not available (SNA)";
CM_ SG_ 1336 VCSEAT2L_a251_seatSwitchForward "VCSEAT2L ECU: a251 seat switch forward; raw 0 = signal not available (SNA)";
CM_ SG_ 1336 VCSEAT2L_a252_seatMotorCurrent "VCSEAT2L ECU: a252 seat motor current";
CM_ SG_ 1336 VCSEAT2L_a252_seatMotorPosReal "VCSEAT2L ECU: a252 seat motor pos real";
CM_ SG_ 1336 VCSEAT2L_a252_seatMotorState "VCSEAT2L ECU: a252 seat motor state";
CM_ SG_ 1336 VCSEAT2L_a252_seatSwitchBack "VCSEAT2L ECU: a252 seat switch back; raw 0 = signal not available (SNA)";
CM_ SG_ 1336 VCSEAT2L_a252_seatSwitchForward "VCSEAT2L ECU: a252 seat switch forward; raw 0 = signal not available (SNA)";
CM_ SG_ 1336 VCSEAT2L_a260_seatStatePrev "VCSEAT2L ECU: a260 seat state prev";
CM_ SG_ 1336 VCSEAT2L_a260_obstacleDetectReas "VCSEAT2L ECU: a260 obstacle detect reason";
CM_ SG_ 1336 VCSEAT2L_a260_obstacleDetectPosi "VCSEAT2L ECU: a260 obstacle detect position";
CM_ SG_ 1336 VCSEAT2L_a260_accelLookbackTripD "VCSEAT2L ECU: a260 accel lookback trip depth";
CM_ SG_ 1336 VCSEAT2L_a260_seatMotorCurrent "VCSEAT2L ECU: a260 seat motor current";
CM_ SG_ 1336 VCSEAT2L_a261_seatStatePrev "VCSEAT2L ECU: a261 seat state prev";
CM_ SG_ 1336 VCSEAT2L_a261_obstacleDetectReas "VCSEAT2L ECU: a261 obstacle detect reason";
CM_ SG_ 1336 VCSEAT2L_a261_obstacleDetectPosi "VCSEAT2L ECU: a261 obstacle detect position";
CM_ SG_ 1336 VCSEAT2L_a261_accelLookbackTripD "VCSEAT2L ECU: a261 accel lookback trip depth";
CM_ SG_ 1336 VCSEAT2L_a261_seatMotorCurrent "VCSEAT2L ECU: a261 seat motor current";
CM_ SG_ 1336 VCSEAT2L_a263_seatMotorCurrent "VCSEAT2L ECU: a263 seat motor current";
CM_ SG_ 1336 VCSEAT2L_a263_seatMotorDCurrent "VCSEAT2L ECU: a263 seat motor d current";
CM_ SG_ 1336 VCSEAT2L_a263_seatMotorPosReal "VCSEAT2L ECU: a263 seat motor pos real";
CM_ SG_ 1336 VCSEAT2L_a263_seatMotorState "VCSEAT2L ECU: a263 seat motor state";
CM_ SG_ 1336 VCSEAT2L_a264_seatMotorCurrent "VCSEAT2L ECU: a264 seat motor current";
CM_ SG_ 1336 VCSEAT2L_a264_seatMotorDCurrent "VCSEAT2L ECU: a264 seat motor d current";
CM_ SG_ 1336 VCSEAT2L_a264_seatMotorPosReal "VCSEAT2L ECU: a264 seat motor pos real";
CM_ SG_ 1336 VCSEAT2L_a264_seatMotorState "VCSEAT2L ECU: a264 seat motor state";
CM_ SG_ 1336 VCSEAT2L_a267_seatMotorCurrent "VCSEAT2L ECU: a267 seat motor current";
CM_ SG_ 1336 VCSEAT2L_a267_seatMotorDCurrent "VCSEAT2L ECU: a267 seat motor d current";
CM_ SG_ 1336 VCSEAT2L_a267_seatMotorPosReal "VCSEAT2L ECU: a267 seat motor pos real";
CM_ SG_ 1336 VCSEAT2L_a267_seatMotorState "VCSEAT2L ECU: a267 seat motor state";
CM_ SG_ 1336 VCSEAT2L_a268_seatMotorCurrent "VCSEAT2L ECU: a268 seat motor current";
CM_ SG_ 1336 VCSEAT2L_a268_seatMotorDCurrent "VCSEAT2L ECU: a268 seat motor d current";
CM_ SG_ 1336 VCSEAT2L_a268_seatMotorPosReal "VCSEAT2L ECU: a268 seat motor pos real";
CM_ SG_ 1336 VCSEAT2L_a268_seatMotorState "VCSEAT2L ECU: a268 seat motor state";
CM_ SG_ 1336 VCSEAT2L_a270_isRearwardEndstopU "VCSEAT2L ECU: a270 is rearward endstop uncalibrated";
CM_ SG_ 1336 VCSEAT2L_a270_isAbsPosSensorUnca "VCSEAT2L ECU: a270 is abs pos sensor uncalibrated";
CM_ SG_ 1336 VCSEAT2L_a270_seatState "VCSEAT2L ECU: a270 seat state; raw 15 = signal not available (SNA)";
CM_ SG_ 1336 VCSEAT2L_a270_motorType "VCSEAT2L ECU: a270 motor type";
CM_ SG_ 1336 VCSEAT2L_a270_absPosSensState "VCSEAT2L ECU: a270 abs pos sens state";
CM_ SG_ 1336 VCSEAT2L_a273_calibrated "VCSEAT2L ECU: a273 calibrated";
CM_ SG_ 1336 VCSEAT2L_a273_angle "VCSEAT2L ECU: a273 angle";
CM_ SG_ 1336 VCSEAT2L_a273_seatStatePrev "VCSEAT2L ECU: a273 seat state prev; raw 15 = signal not available (SNA)";
CM_ SG_ 1336 VCSEAT2L_a273_obstacleDetectReas "VCSEAT2L ECU: a273 obstacle detect reason";
CM_ SG_ 1336 VCSEAT2L_a273_accelLookbackTripD "VCSEAT2L ECU: a273 accel lookback trip depth";
CM_ SG_ 1336 VCSEAT2L_a273_duty "VCSEAT2L ECU: a273 duty";
CM_ SG_ 1336 VCSEAT2L_a273_currentAbsFilt "VCSEAT2L ECU: a273 current abs filt";
CM_ SG_ 1336 VCSEAT2L_a273_motorType "VCSEAT2L ECU: a273 motor type";
CM_ SG_ 1336 VCSEAT2L_a273_absolutePosSensorF "VCSEAT2L ECU: a273 absolute pos sensor forward";
CM_ SG_ 1336 VCSEAT2L_a273_cabinTemp "VCSEAT2L ECU: a273 cabin temp";
CM_ SG_ 1336 VCSEAT2L_a277_isRearwardEndstopU "VCSEAT2L ECU: a277 is rearward endstop uncalibrated";
CM_ SG_ 1336 VCSEAT2L_a277_isAbsPosSensorUnca "VCSEAT2L ECU: a277 is abs pos sensor uncalibrated";
CM_ SG_ 1336 VCSEAT2L_a278_seatState "VCSEAT2L ECU: a278 seat state; raw 15 = signal not available (SNA)";
CM_ SG_ 1336 VCSEAT2L_a290_isNetworkSwitch "VCSEAT2L ECU: a290 is network switch";
CM_ SG_ 1336 VCSEAT2L_a290_occupancySensorV "VCSEAT2L ECU: a290 occupancy sensor v";
CM_ SG_ 1336 VCSEAT2L_a290_railVoltage "VCSEAT2L ECU: a290 rail voltage";
CM_ SG_ 1336 VCSEAT2L_a291_buckleSensorVoltag "VCSEAT2L ECU: a291 buckle sensor voltage";
CM_ SG_ 1336 VCSEAT2L_a291_railVoltage "VCSEAT2L ECU: a291 rail voltage";
CM_ SG_ 1336 VCSEAT2L_a426_seatMotorCalibrate "VCSEAT2L ECU: a426 seat motor calibrated";
CM_ SG_ 1336 VCSEAT2L_a426_seatMotorCurrent "VCSEAT2L ECU: a426 seat motor current";
CM_ SG_ 1336 VCSEAT2L_a426_seatMotorPosReal "VCSEAT2L ECU: a426 seat motor pos real";
CM_ SG_ 1336 VCSEAT2L_a426_seatMotorState "VCSEAT2L ECU: a426 seat motor state";
CM_ SG_ 1336 VCSEAT2L_a426_seatSwitchBack "VCSEAT2L ECU: a426 seat switch back; raw 0 = signal not available (SNA)";
CM_ SG_ 1336 VCSEAT2L_a426_seatSwitchForward "VCSEAT2L ECU: a426 seat switch forward; raw 0 = signal not available (SNA)";
CM_ SG_ 1336 VCSEAT2L_a426_cabinTmp "VCSEAT2L ECU: a426 cabin tmp";
CM_ SG_ 1336 VCSEAT2L_a427_seatMotorCalibrate "VCSEAT2L ECU: a427 seat motor calibrated";
CM_ SG_ 1336 VCSEAT2L_a427_seatMotorCurrent "VCSEAT2L ECU: a427 seat motor current";
CM_ SG_ 1336 VCSEAT2L_a427_seatMotorPosReal "VCSEAT2L ECU: a427 seat motor pos real";
CM_ SG_ 1336 VCSEAT2L_a427_seatMotorState "VCSEAT2L ECU: a427 seat motor state";
CM_ SG_ 1336 VCSEAT2L_a427_seatSwitchBack "VCSEAT2L ECU: a427 seat switch back; raw 0 = signal not available (SNA)";
CM_ SG_ 1336 VCSEAT2L_a427_seatSwitchForward "VCSEAT2L ECU: a427 seat switch forward; raw 0 = signal not available (SNA)";
CM_ SG_ 1336 VCSEAT2L_a427_cabinTmp "VCSEAT2L ECU: a427 cabin tmp";
CM_ SG_ 1336 VCSEAT2L_a428_seatMotorCalibrate "VCSEAT2L ECU: a428 seat motor calibrated";
CM_ SG_ 1336 VCSEAT2L_a428_seatMotorCurrent "VCSEAT2L ECU: a428 seat motor current";
CM_ SG_ 1336 VCSEAT2L_a428_seatMotorPosReal "VCSEAT2L ECU: a428 seat motor pos real";
CM_ SG_ 1336 VCSEAT2L_a428_seatMotorState "VCSEAT2L ECU: a428 seat motor state";
CM_ SG_ 1336 VCSEAT2L_a428_seatSwitchBack "VCSEAT2L ECU: a428 seat switch back; raw 0 = signal not available (SNA)";
CM_ SG_ 1336 VCSEAT2L_a428_seatSwitchForward "VCSEAT2L ECU: a428 seat switch forward; raw 0 = signal not available (SNA)";
CM_ SG_ 1336 VCSEAT2L_a428_cabinTmp "VCSEAT2L ECU: a428 cabin tmp";
CM_ SG_ 1336 VCSEAT2L_a429_seatMotorCalibrate "VCSEAT2L ECU: a429 seat motor calibrated";
CM_ SG_ 1336 VCSEAT2L_a429_seatMotorCurrent "VCSEAT2L ECU: a429 seat motor current";
CM_ SG_ 1336 VCSEAT2L_a429_seatMotorPosReal "VCSEAT2L ECU: a429 seat motor pos real";
CM_ SG_ 1336 VCSEAT2L_a429_seatMotorState "VCSEAT2L ECU: a429 seat motor state";
CM_ SG_ 1336 VCSEAT2L_a429_seatSwitchBack "VCSEAT2L ECU: a429 seat switch back; raw 0 = signal not available (SNA)";
CM_ SG_ 1336 VCSEAT2L_a429_seatSwitchForward "VCSEAT2L ECU: a429 seat switch forward; raw 0 = signal not available (SNA)";
CM_ SG_ 1336 VCSEAT2L_a429_cabinTmp "VCSEAT2L ECU: a429 cabin tmp";
CM_ SG_ 1336 VCSEAT2L_a444_retriesAvailable "VCSEAT2L ECU: a444 retries available";
CM_ SG_ 1336 VCSEAT2L_a444_channel "VCSEAT2L ECU: a444 channel";
CM_ SG_ 1336 VCSEAT2L_a444_watchdog "VCSEAT2L ECU: a444 watchdog";
CM_ SG_ 1336 VCSEAT2L_a444_gateDriver "VCSEAT2L ECU: a444 gate driver";
CM_ SG_ 1336 VCSEAT2L_a444_overcurrent "VCSEAT2L ECU: a444 overcurrent";
CM_ SG_ 1336 VCSEAT2L_a444_supplyUndervoltage "VCSEAT2L ECU: a444 supply undervoltage";
CM_ SG_ 1336 VCSEAT2L_a444_cpUndervoltage "VCSEAT2L ECU: a444 cp undervoltage";
CM_ SG_ 1336 VCSEAT2L_a444_overTempShutdown "VCSEAT2L ECU: a444 over temp shutdown";
CM_ SG_ 1336 VCSEAT2L_a444_overTempWarning "VCSEAT2L ECU: a444 over temp warning";
CM_ SG_ 1336 VCSEAT2L_a444_highSide2GateDrive "VCSEAT2L ECU: a444 high side2 gate driver";
CM_ SG_ 1336 VCSEAT2L_a444_lowSide2GateDriver "VCSEAT2L ECU: a444 low side2 gate driver";
CM_ SG_ 1336 VCSEAT2L_a444_highSide1GateDrive "VCSEAT2L ECU: a444 high side1 gate driver";
CM_ SG_ 1336 VCSEAT2L_a444_lowSide1GateDriver "VCSEAT2L ECU: a444 low side1 gate driver";
CM_ SG_ 1336 VCSEAT2L_a444_highSide2OverCuren "VCSEAT2L ECU: a444 high side2 over curent";
CM_ SG_ 1336 VCSEAT2L_a444_lowSide2OverCurent "VCSEAT2L ECU: a444 low side2 over curent";
CM_ SG_ 1336 VCSEAT2L_a444_highSide1OverCuren "VCSEAT2L ECU: a444 high side1 over curent";
CM_ SG_ 1336 VCSEAT2L_a444_lowSide1OverCurent "VCSEAT2L ECU: a444 low side1 over curent";
CM_ SG_ 1336 VCSEAT2L_a444_spiInit "VCSEAT2L ECU: a444 spi init";
CM_ SG_ 1336 VCSEAT2L_a444_spiPeriodicCheck "VCSEAT2L ECU: a444 spi periodic check";
CM_ SG_ 1336 VCSEAT2L_a444_spiFault "VCSEAT2L ECU: a444 spi fault";
CM_ SG_ 1336 VCSEAT2L_a444_voltageMonitor "VCSEAT2L ECU: a444 voltage monitor";
CM_ SG_ 1336 VCSEAT2L_a444_enableLow "VCSEAT2L ECU: a444 enable low";
CM_ SG_ 1336 VCSEAT2L_a571_seatHeatCurrent "VCSEAT2L ECU: a571 seat heat current";
CM_ SG_ 1336 VCSEAT2L_a571_seatHeatTmp "VCSEAT2L ECU: a571 seat heat tmp";
BA_DEF_ BO_ "GenMsgCycleTime" INT 0 3600000;
BA_DEF_ BO_ "GenMsgSendType" ENUM "Cyclic","NotUsed","NotUsed","NotUsed","NotUsed","NotUsed","NotUsed","IfActive","NoMsgSendType","NotUsed";
BA_DEF_ BO_ "VFrameFormat" ENUM "StandardCAN","ExtendedCAN","reserved","J1939PG","reserved","reserved","reserved","reserved","reserved","reserved","reserved","reserved","reserved","reserved","StandardCAN_FD","ExtendedCAN_FD";
BA_DEF_ BO_ "CANFD_BRS" ENUM "0","1";
BA_DEF_ SG_ "GenSigSNA" STRING;
BA_DEF_ SG_ "SystemSignalLongSymbol" STRING;
BA_DEF_ SG_ "Confidence" ENUM "validated","plausible","layout-only","contradicted";
BA_DEF_DEF_ "GenMsgCycleTime" 0;
BA_DEF_DEF_ "GenMsgSendType" "NoMsgSendType";
BA_DEF_DEF_ "VFrameFormat" "StandardCAN";
BA_DEF_DEF_ "CANFD_BRS" "1";
BA_DEF_DEF_ "GenSigSNA" "";
BA_DEF_DEF_ "SystemSignalLongSymbol" "";
BA_DEF_DEF_ "Confidence" "layout-only";
BA_ "GenMsgCycleTime" BO_ 293 1000;
BA_ "GenMsgSendType" BO_ 293 0;
BA_ "GenMsgCycleTime" BO_ 294 1000;
BA_ "GenMsgSendType" BO_ 294 0;
BA_ "GenMsgCycleTime" BO_ 295 1000;
BA_ "GenMsgSendType" BO_ 295 0;
BA_ "GenMsgCycleTime" BO_ 1279 1000;
BA_ "GenMsgSendType" BO_ 1279 0;
BA_ "GenMsgCycleTime" BO_ 993 2000;
BA_ "GenMsgSendType" BO_ 993 0;
BA_ "GenMsgCycleTime" BO_ 666 500;
BA_ "GenMsgSendType" BO_ 666 0;
BA_ "GenMsgCycleTime" BO_ 563 500;
BA_ "GenMsgSendType" BO_ 563 0;
BA_ "GenMsgCycleTime" BO_ 986 1000;
BA_ "GenMsgSendType" BO_ 986 0;
BA_ "GenMsgCycleTime" BO_ 661 15000;
BA_ "GenMsgSendType" BO_ 661 0;
BA_ "GenMsgCycleTime" BO_ 1263 1000;
BA_ "GenMsgSendType" BO_ 1263 0;
BA_ "GenMsgCycleTime" BO_ 139 1000;
BA_ "GenMsgSendType" BO_ 139 0;
BA_ "GenMsgCycleTime" BO_ 1173 1000;
BA_ "GenMsgSendType" BO_ 1173 0;
BA_ "GenMsgCycleTime" BO_ 1174 1000;
BA_ "GenMsgSendType" BO_ 1174 0;
BA_ "GenMsgCycleTime" BO_ 1175 1000;
BA_ "GenMsgSendType" BO_ 1175 0;
BA_ "GenMsgCycleTime" BO_ 649 100;
BA_ "GenMsgSendType" BO_ 649 0;
BA_ "SystemSignalLongSymbol" SG_ 293 UI_a132_AdspWatchdogRecoveryTrig "UI_a132_AdspWatchdogRecoveryTriggered";
BA_ "SystemSignalLongSymbol" SG_ 293 UI_a133_AdspWatchdogRecoveryFail "UI_a133_AdspWatchdogRecoveryFailed";
BA_ "SystemSignalLongSymbol" SG_ 293 UI_a137_ServiceShellActiveConnec "UI_a137_ServiceShellActiveConnection";
BA_ "SystemSignalLongSymbol" SG_ 293 UI_a151_carComputerThermalProble "UI_a151_carComputerThermalProblem";
BA_ "SystemSignalLongSymbol" SG_ 293 UI_a156_UsbFrontHubInstallMismat "UI_a156_UsbFrontHubInstallMismatch";
BA_ "SystemSignalLongSymbol" SG_ 293 UI_a157_MCUActiveCoolingRequeste "UI_a157_MCUActiveCoolingRequested";
BA_ "SystemSignalLongSymbol" SG_ 293 UI_a161_ECallTemporarilyUnavaila "UI_a161_ECallTemporarilyUnavailable";
BA_ "SystemSignalLongSymbol" SG_ 293 UI_a168_dgpuPowerOnSelfTestFailu "UI_a168_dgpuPowerOnSelfTestFailure";
BA_ "SystemSignalLongSymbol" SG_ 293 UI_a171_GraphicsLoadShedRequeste "UI_a171_GraphicsLoadShedRequested";
BA_ "SystemSignalLongSymbol" SG_ 293 UI_a172_GraphicsLoadShedUIFailur "UI_a172_GraphicsLoadShedUIFailure";
BA_ "SystemSignalLongSymbol" SG_ 293 UI_a181_ModemFirmwareVersionMism "UI_a181_ModemFirmwareVersionMismatch";
BA_ "SystemSignalLongSymbol" SG_ 293 UI_a187_TunerFirmwareMismatchedV "UI_a187_TunerFirmwareMismatchedVersion";
BA_ "SystemSignalLongSymbol" SG_ 293 UI_a188_TunerFirmwareMismatchedA "UI_a188_TunerFirmwareMismatchedAPI";
BA_ "SystemSignalLongSymbol" SG_ 294 UI_a193_TcuRNandFwVersionMismatc "UI_a193_TcuRNandFwVersionMismatch";
BA_ "SystemSignalLongSymbol" SG_ 294 UI_a198_IncompatibleBTUSBHubHard "UI_a198_IncompatibleBTUSBHubHardware";
BA_ "SystemSignalLongSymbol" SG_ 294 UI_a199_HighAPedalDetectedAtColl "UI_a199_HighAPedalDetectedAtCollision";
BA_ "SystemSignalLongSymbol" SG_ 294 UI_a200_UIFirmwareVersionMismatc "UI_a200_UIFirmwareVersionMismatch";
BA_ "SystemSignalLongSymbol" SG_ 294 UI_a224_centerDisplayDisconnecte "UI_a224_centerDisplayDisconnected";
BA_ "SystemSignalLongSymbol" SG_ 294 UI_a225_clusterDisplayDisconnect "UI_a225_clusterDisplayDisconnected";
BA_ "SystemSignalLongSymbol" SG_ 294 UI_a242_uiHealthFaultInjectionAc "UI_a242_uiHealthFaultInjectionActive";
BA_ "SystemSignalLongSymbol" SG_ 294 UI_a247_StalklessDisplayBackligh "UI_a247_StalklessDisplayBacklightFailure";
BA_ "SystemSignalLongSymbol" SG_ 294 UI_a253_maintenanceHistoryRecord "UI_a253_maintenanceHistoryRecorded";
BA_ "SystemSignalLongSymbol" SG_ 295 UI_a265_USBHostControllerUnrecov "UI_a265_USBHostControllerUnrecoverable";
BA_ "SystemSignalLongSymbol" SG_ 295 UI_a266_DashcamRecentBufferDurat "UI_a266_DashcamRecentBufferDurationReduced";
BA_ "SystemSignalLongSymbol" SG_ 295 UI_a276_PrivateNetworkProfileAct "UI_a276_PrivateNetworkProfileActive";
BA_ "Confidence" SG_ 1279 UI_energyConsumptionInfoIndex 1;
BA_ "Confidence" SG_ 1279 UI_energyLossTotal_epa 0;
BA_ "Confidence" SG_ 1279 UI_energyLossDriving_epa 0;
BA_ "Confidence" SG_ 1279 UI_energyLossClimate_epa 0;
BA_ "Confidence" SG_ 1279 UI_energyLossBattCond_epa 0;
BA_ "Confidence" SG_ 1279 UI_energyLossElevation_epa 0;
BA_ "Confidence" SG_ 1279 UI_energyLossAcc_epa 0;
BA_ "Confidence" SG_ 1279 UI_energyLossTotalSinceCharge_ep 0;
BA_ "SystemSignalLongSymbol" SG_ 1279 UI_energyLossTotalSinceCharge_ep "UI_energyLossTotalSinceCharge_epa";
BA_ "Confidence" SG_ 1279 UI_energyLossDrivingSinceCharge_ 0;
BA_ "SystemSignalLongSymbol" SG_ 1279 UI_energyLossDrivingSinceCharge_ "UI_energyLossDrivingSinceCharge_epa";
BA_ "Confidence" SG_ 1279 UI_energyLossClimateSinceCharge_ 0;
BA_ "SystemSignalLongSymbol" SG_ 1279 UI_energyLossClimateSinceCharge_ "UI_energyLossClimateSinceCharge_epa";
BA_ "Confidence" SG_ 1279 UI_energyLossBattCondSinceCharge 0;
BA_ "SystemSignalLongSymbol" SG_ 1279 UI_energyLossBattCondSinceCharge "UI_energyLossBattCondSinceCharge_epa";
BA_ "Confidence" SG_ 1279 UI_energyLossElevationSinceCharg 0;
BA_ "SystemSignalLongSymbol" SG_ 1279 UI_energyLossElevationSinceCharg "UI_energyLossElevationSinceCharge_epa";
BA_ "Confidence" SG_ 1279 UI_energyLossAccSinceCharge_epa 0;
BA_ "Confidence" SG_ 1279 UI_energyLossTotalSinceTripStart 0;
BA_ "Confidence" SG_ 1279 UI_energyLossDrivingSinceTripSta 0;
BA_ "SystemSignalLongSymbol" SG_ 1279 UI_energyLossDrivingSinceTripSta "UI_energyLossDrivingSinceTripStart";
BA_ "Confidence" SG_ 1279 UI_energyLossClimateSinceTripSta 0;
BA_ "SystemSignalLongSymbol" SG_ 1279 UI_energyLossClimateSinceTripSta "UI_energyLossClimateSinceTripStart";
BA_ "Confidence" SG_ 1279 UI_energyLossBattCondSinceTripSt 0;
BA_ "SystemSignalLongSymbol" SG_ 1279 UI_energyLossBattCondSinceTripSt "UI_energyLossBattCondSinceTripStart";
BA_ "Confidence" SG_ 1279 UI_energyLossElevationSinceTripS 0;
BA_ "SystemSignalLongSymbol" SG_ 1279 UI_energyLossElevationSinceTripS "UI_energyLossElevationSinceTripStart";
BA_ "Confidence" SG_ 1279 UI_energyLossAccSinceTripStart 0;
BA_ "Confidence" SG_ 1279 UI_energyDeltaTotal_epa 0;
BA_ "Confidence" SG_ 1279 UI_energyDeltaDriving_epa 0;
BA_ "Confidence" SG_ 1279 UI_energyDeltaClimate_epa 0;
BA_ "Confidence" SG_ 1279 UI_energyDeltaBattCond_epa 0;
BA_ "Confidence" SG_ 1279 UI_energyDeltaElevation_epa 0;
BA_ "Confidence" SG_ 1279 UI_energyDeltaAcc_epa 0;
BA_ "Confidence" SG_ 1279 UI_uiDeltaOffsetTotal_epa 0;
BA_ "Confidence" SG_ 1279 UI_uiDeltaOffsetDriving_epa 0;
BA_ "Confidence" SG_ 1279 UI_uiDeltaOffsetClimate_epa 0;
BA_ "Confidence" SG_ 1279 UI_uiDeltaOffsetBattCond_epa 0;
BA_ "Confidence" SG_ 1279 UI_uiDeltaOffsetElevation_epa 0;
BA_ "Confidence" SG_ 1279 UI_uiDeltaOffsetAcc_epa 0;
BA_ "Confidence" SG_ 1279 UI_rawToUiEnergyRatio_epa 0;
BA_ "Confidence" SG_ 1279 UI_driveDistance_epa 0;
BA_ "Confidence" SG_ 1279 UI_energyDeltaTotalSinceCharge_e 0;
BA_ "SystemSignalLongSymbol" SG_ 1279 UI_energyDeltaTotalSinceCharge_e "UI_energyDeltaTotalSinceCharge_epa";
BA_ "Confidence" SG_ 1279 UI_energyDeltaDrivingSinceCharge 0;
BA_ "SystemSignalLongSymbol" SG_ 1279 UI_energyDeltaDrivingSinceCharge "UI_energyDeltaDrivingSinceCharge_epa";
BA_ "Confidence" SG_ 1279 UI_energyDeltaClimateSinceCharge 0;
BA_ "SystemSignalLongSymbol" SG_ 1279 UI_energyDeltaClimateSinceCharge "UI_energyDeltaClimateSinceCharge_epa";
BA_ "Confidence" SG_ 1279 UI_energyDeltaBattCondSinceCharg 0;
BA_ "SystemSignalLongSymbol" SG_ 1279 UI_energyDeltaBattCondSinceCharg "UI_energyDeltaBattCondSinceCharge_epa";
BA_ "Confidence" SG_ 1279 UI_energyDeltaElevationSinceChar 0;
BA_ "SystemSignalLongSymbol" SG_ 1279 UI_energyDeltaElevationSinceChar "UI_energyDeltaElevationSinceCharge_epa";
BA_ "Confidence" SG_ 1279 UI_energyDeltaAccSinceCharge_epa 0;
BA_ "Confidence" SG_ 1279 UI_uiDeltaOffsetTotalSinceCharge 0;
BA_ "SystemSignalLongSymbol" SG_ 1279 UI_uiDeltaOffsetTotalSinceCharge "UI_uiDeltaOffsetTotalSinceCharge_epa";
BA_ "Confidence" SG_ 1279 UI_uiDeltaOffsetDrivingSinceChar 0;
BA_ "SystemSignalLongSymbol" SG_ 1279 UI_uiDeltaOffsetDrivingSinceChar "UI_uiDeltaOffsetDrivingSinceCharge_epa";
BA_ "Confidence" SG_ 1279 UI_uiDeltaOffsetClimateSinceChar 0;
BA_ "SystemSignalLongSymbol" SG_ 1279 UI_uiDeltaOffsetClimateSinceChar "UI_uiDeltaOffsetClimateSinceCharge_epa";
BA_ "Confidence" SG_ 1279 UI_uiDeltaOffsetBattCondSinceCha 0;
BA_ "SystemSignalLongSymbol" SG_ 1279 UI_uiDeltaOffsetBattCondSinceCha "UI_uiDeltaOffsetBattCondSinceCharge_epa";
BA_ "Confidence" SG_ 1279 UI_uiDeltaOffsetElevationSinceCh 0;
BA_ "SystemSignalLongSymbol" SG_ 1279 UI_uiDeltaOffsetElevationSinceCh "UI_uiDeltaOffsetElevationSinceCharge_epa";
BA_ "Confidence" SG_ 1279 UI_uiDeltaOffsetAccSinceCharge_e 0;
BA_ "SystemSignalLongSymbol" SG_ 1279 UI_uiDeltaOffsetAccSinceCharge_e "UI_uiDeltaOffsetAccSinceCharge_epa";
BA_ "Confidence" SG_ 1279 UI_rawToUiEnergyRatioSinceCharge 0;
BA_ "SystemSignalLongSymbol" SG_ 1279 UI_rawToUiEnergyRatioSinceCharge "UI_rawToUiEnergyRatioSinceCharge_epa";
BA_ "Confidence" SG_ 1279 UI_driveDistanceSinceCharge_epa 0;
BA_ "Confidence" SG_ 1279 UI_energyDeltaTotalSinceTripStar 0;
BA_ "SystemSignalLongSymbol" SG_ 1279 UI_energyDeltaTotalSinceTripStar "UI_energyDeltaTotalSinceTripStart";
BA_ "Confidence" SG_ 1279 UI_energyDeltaDrivingSinceTripSt 0;
BA_ "SystemSignalLongSymbol" SG_ 1279 UI_energyDeltaDrivingSinceTripSt "UI_energyDeltaDrivingSinceTripStart";
BA_ "Confidence" SG_ 1279 UI_energyDeltaClimateSinceTripSt 0;
BA_ "SystemSignalLongSymbol" SG_ 1279 UI_energyDeltaClimateSinceTripSt "UI_energyDeltaClimateSinceTripStart";
BA_ "Confidence" SG_ 1279 UI_energyDeltaBattCondSinceTripS 0;
BA_ "SystemSignalLongSymbol" SG_ 1279 UI_energyDeltaBattCondSinceTripS "UI_energyDeltaBattCondSinceTripStart";
BA_ "Confidence" SG_ 1279 UI_energyDeltaElevationSinceTrip 0;
BA_ "SystemSignalLongSymbol" SG_ 1279 UI_energyDeltaElevationSinceTrip "UI_energyDeltaElevationSinceTripStart";
BA_ "Confidence" SG_ 1279 UI_energyDeltaAccSinceTripStart 0;
BA_ "Confidence" SG_ 1279 UI_uiDeltaOffsetTotalSinceTripSt 0;
BA_ "SystemSignalLongSymbol" SG_ 1279 UI_uiDeltaOffsetTotalSinceTripSt "UI_uiDeltaOffsetTotalSinceTripStart";
BA_ "Confidence" SG_ 1279 UI_uiDeltaOffsetDrivingSinceTrip 0;
BA_ "SystemSignalLongSymbol" SG_ 1279 UI_uiDeltaOffsetDrivingSinceTrip "UI_uiDeltaOffsetDrivingSinceTripStart";
BA_ "Confidence" SG_ 1279 UI_uiDeltaOffsetClimateSinceTrip 0;
BA_ "SystemSignalLongSymbol" SG_ 1279 UI_uiDeltaOffsetClimateSinceTrip "UI_uiDeltaOffsetClimateSinceTripStart";
BA_ "Confidence" SG_ 1279 UI_uiDeltaOffsetBattCondSinceTri 0;
BA_ "SystemSignalLongSymbol" SG_ 1279 UI_uiDeltaOffsetBattCondSinceTri "UI_uiDeltaOffsetBattCondSinceTripStart";
BA_ "Confidence" SG_ 1279 UI_uiDeltaOffsetElevationSinceTr 0;
BA_ "SystemSignalLongSymbol" SG_ 1279 UI_uiDeltaOffsetElevationSinceTr "UI_uiDeltaOffsetElevationSinceTripStart";
BA_ "Confidence" SG_ 1279 UI_uiDeltaOffsetAccSinceTripStar 0;
BA_ "SystemSignalLongSymbol" SG_ 1279 UI_uiDeltaOffsetAccSinceTripStar "UI_uiDeltaOffsetAccSinceTripStart";
BA_ "Confidence" SG_ 1279 UI_rawToUiEnergyRatioSinceTripSt 0;
BA_ "SystemSignalLongSymbol" SG_ 1279 UI_rawToUiEnergyRatioSinceTripSt "UI_rawToUiEnergyRatioSinceTripStart";
BA_ "Confidence" SG_ 1279 UI_driveDistanceSinceTripStart 0;
BA_ "Confidence" SG_ 1279 UI_trailerMass 0;
BA_ "Confidence" SG_ 993 UI_gearSliderInfoIndex 1;
BA_ "Confidence" SG_ 666 UI_seatControlIndex 1;
BA_ "Confidence" SG_ 666 UI_3RSeatChildLock 0;
BA_ "Confidence" SG_ 666 UI_left3RowSeatAdjustmentRequest 0;
BA_ "Confidence" SG_ 666 UI_right3RowSeatAdjustmentReques 0;
BA_ "SystemSignalLongSymbol" SG_ 666 UI_right3RowSeatAdjustmentReques "UI_right3RowSeatAdjustmentRequest";
BA_ "Confidence" SG_ 666 UI_2RLeftSeatFanReq 0;
BA_ "Confidence" SG_ 666 UI_2RRightSeatFanReq 0;
BA_ "SystemSignalLongSymbol" SG_ 666 UI_leftThirdRowSeatRequestFromRe "UI_leftThirdRowSeatRequestFromRearDisplay";
BA_ "SystemSignalLongSymbol" SG_ 666 UI_rightThirdRowSeatRequestFromR "UI_rightThirdRowSeatRequestFromRearDisplay";
BA_ "Confidence" SG_ 666 UI_seatChoreographyStopRequest 0;
BA_ "Confidence" SG_ 563 UI_gearRequest 0;
BA_ "GenSigSNA" SG_ 563 UI_gearRequest "0";
BA_ "Confidence" SG_ 563 UI_autopilotRequest 1;
BA_ "Confidence" SG_ 563 UI_gearStripShowing 0;
BA_ "Confidence" SG_ 563 UI_gearStripLocation 1;
BA_ "Confidence" SG_ 563 UI_gearStripForceShow 0;
BA_ "Confidence" SG_ 563 UI_autoParkAvailable 0;
BA_ "Confidence" SG_ 563 UI_gearStripSuppressActive 0;
BA_ "Confidence" SG_ 563 UI_gearNeutralPressed 0;
BA_ "Confidence" SG_ 986 UI_wifiRegDomain 0;
BA_ "Confidence" SG_ 986 UI_wifiTethered 0;
BA_ "Confidence" SG_ 661 UI_systemMonitorIndex 1;
BA_ "Confidence" SG_ 661 UI_SystemMemUsage 0;
BA_ "Confidence" SG_ 661 UI_QtCarMemUsage 0;
BA_ "Confidence" SG_ 661 UI_QtCarCPUUsage 0;
BA_ "Confidence" SG_ 661 UI_SystemCPUUsage 0;
BA_ "Confidence" SG_ 1263 UI_fwHeatOnNavArrivalSOE 0;
BA_ "Confidence" SG_ 1263 UI_voyagerHeatOnNavArrivalSOE 0;
BA_ "Confidence" SG_ 139 UI_maxSpeedToReachDestination 0;
BA_ "GenSigSNA" SG_ 139 UI_maxSpeedToReachDestination "65535";
BA_ "Confidence" SG_ 139 UI_remainingWeightedRMSSpeed 1;
BA_ "GenSigSNA" SG_ 139 UI_remainingWeightedRMSSpeed "65535";
BA_ "Confidence" SG_ 139 UI_timeToDestination 0;
BA_ "GenSigSNA" SG_ 139 UI_timeToDestination "65535";
BA_ "Confidence" SG_ 1173 UI_predictedEnergy 0;
BA_ "GenSigSNA" SG_ 1173 UI_predictedEnergy "32768";
BA_ "Confidence" SG_ 1173 UI_predictedEnergyLearned 1;
BA_ "GenSigSNA" SG_ 1173 UI_predictedEnergyLearned "32768";
BA_ "Confidence" SG_ 1173 UI_hindsightEnergy 0;
BA_ "GenSigSNA" SG_ 1173 UI_hindsightEnergy "32768";
BA_ "Confidence" SG_ 1173 UI_hindsightEnergyLearned 1;
BA_ "GenSigSNA" SG_ 1173 UI_hindsightEnergyLearned "32768";
BA_ "Confidence" SG_ 1174 UI_longTermEnergyModelError 1;
BA_ "GenSigSNA" SG_ 1174 UI_longTermEnergyModelError "128";
BA_ "Confidence" SG_ 1174 UI_longTermRmsSpeedRatio 1;
BA_ "GenSigSNA" SG_ 1174 UI_longTermRmsSpeedRatio "255";
BA_ "Confidence" SG_ 1174 UI_gradeCorrectedEnergy 1;
BA_ "GenSigSNA" SG_ 1174 UI_gradeCorrectedEnergy "32768";
BA_ "Confidence" SG_ 1174 UI_gradeCorrectedEnergyLearned 1;
BA_ "GenSigSNA" SG_ 1174 UI_gradeCorrectedEnergyLearned "32768";
BA_ "Confidence" SG_ 1175 UI_battPreconditionOnNavTime 1;
BA_ "GenSigSNA" SG_ 1175 UI_battPreconditionOnNavTime "65535";
BA_ "Confidence" SG_ 1175 UI_maxBattPreconditionOnNavTime 1;
BA_ "GenSigSNA" SG_ 1175 UI_maxBattPreconditionOnNavTime "65535";
BA_ "Confidence" SG_ 649 VCLEFT_logging10HzIndex 1;
BA_ "Confidence" SG_ 649 VCLEFT_hvacBlowerRs 0;
BA_ "GenSigSNA" SG_ 649 VCLEFT_hvacBlowerRs "255";
BA_ "Confidence" SG_ 649 VCLEFT_hvacBlowerIPhase0 0;
BA_ "GenSigSNA" SG_ 649 VCLEFT_hvacBlowerIPhase0 "127";
BA_ "Confidence" SG_ 649 VCLEFT_hvacBlowerIPhase1 0;
BA_ "GenSigSNA" SG_ 649 VCLEFT_hvacBlowerIPhase1 "127";
BA_ "Confidence" SG_ 649 VCLEFT_hvacBlowerIPhase2 0;
BA_ "GenSigSNA" SG_ 649 VCLEFT_hvacBlowerIPhase2 "127";
BA_ "Confidence" SG_ 649 VCLEFT_hvacBlower_IO_CBC_HEAD 0;
BA_ "Confidence" SG_ 649 VCLEFT_hvacBlower_IO_CBC_TAIL 0;
BA_ "Confidence" SG_ 649 VCLEFT_hvacBlower_IO_CBC_TAIL_va 0;
BA_ "SystemSignalLongSymbol" SG_ 649 VCLEFT_hvacBlower_IO_CBC_TAIL_va "VCLEFT_hvacBlower_IO_CBC_TAIL_valid";
BA_ "Confidence" SG_ 649 VCLEFT_hvacBlower_IO_CBC_Status 0;
BA_ "Confidence" SG_ 649 VCLEFT_hvacBlower_IO_CBC_numUart 0;
BA_ "SystemSignalLongSymbol" SG_ 649 VCLEFT_hvacBlower_IO_CBC_numUart "VCLEFT_hvacBlower_IO_CBC_numUartErr";
BA_ "Confidence" SG_ 649 VCLEFT_hvacBlowerCBCEstState 0;
BA_ "Confidence" SG_ 649 VCLEFT_hvacBlowerCBCCtrlState 0;
BA_ "Confidence" SG_ 649 VCLEFT_hvacBlowerITerm 0;
BA_ "GenSigSNA" SG_ 649 VCLEFT_hvacBlowerITerm "127";
BA_ "Confidence" SG_ 649 VCLEFT_hvacBlowerSpiError 0;
BA_ "Confidence" SG_ 649 VCLEFT_hvacBlowerRsOnlineActive 0;
BA_ "Confidence" SG_ 1336 VCSEAT2L_alertID 1;
BA_ "Confidence" SG_ 1336 VCSEAT2L_alertState 1;
BA_ "SystemSignalLongSymbol" SG_ 1336 VCSEAT2L_a015_NVMMFilesystemErro "VCSEAT2L_a015_NVMMFilesystemError";
BA_ "Confidence" SG_ 1336 VCSEAT2L_a059_voltageDrop 1;
BA_ "Confidence" SG_ 1336 VCSEAT2L_a059_resistanceEstimate 1;
BA_ "Confidence" SG_ 1336 VCSEAT2L_a059_current 1;
BA_ "Confidence" SG_ 1336 VCSEAT2L_a063_ADCVoltage 1;
BA_ "SystemSignalLongSymbol" SG_ 1336 VCSEAT2L_a082_RIPC_epbPrivateSta "VCSEAT2L_a082_RIPC_epbPrivateState";
BA_ "SystemSignalLongSymbol" SG_ 1336 VCSEAT2L_a083_LIPC_epbPrivateSta "VCSEAT2L_a083_LIPC_epbPrivateState";
BA_ "SystemSignalLongSymbol" SG_ 1336 VCSEAT2L_a086_VEH_LVBMS_statusHi "VCSEAT2L_a086_VEH_LVBMS_statusHigh";
BA_ "SystemSignalLongSymbol" SG_ 1336 VCSEAT2L_a086_VEH_LVBMS_statusLo "VCSEAT2L_a086_VEH_LVBMS_statusLow";
BA_ "SystemSignalLongSymbol" SG_ 1336 VCSEAT2L_a086_VEH_12VBatteryStat "VCSEAT2L_a086_VEH_12VBatteryStatus";
BA_ "SystemSignalLongSymbol" SG_ 1336 VCSEAT2L_a087_PARTY_thermalContr "VCSEAT2L_a087_PARTY_thermalControl";
BA_ "SystemSignalLongSymbol" SG_ 1336 VCSEAT2L_a088_PARTY_thermalContr "VCSEAT2L_a088_PARTY_thermalControl";
BA_ "SystemSignalLongSymbol" SG_ 1336 VCSEAT2L_a091_VEH_faultsAndExtra "VCSEAT2L_a091_VEH_faultsAndExtras";
BA_ "SystemSignalLongSymbol" SG_ 1336 VCSEAT2L_a092_VEH_restraintStatu "VCSEAT2L_a092_VEH_restraintStatus";
BA_ "SystemSignalLongSymbol" SG_ 1336 VCSEAT2L_a093_VEH_restraintStatu "VCSEAT2L_a093_VEH_restraintStatus";
BA_ "SystemSignalLongSymbol" SG_ 1336 VCSEAT2L_a098_PARTY_thermalContr "VCSEAT2L_a098_PARTY_thermalControl";
BA_ "SystemSignalLongSymbol" SG_ 1336 VCSEAT2L_a101_LIPC_externalWatch "VCSEAT2L_a101_LIPC_externalWatchdogHeartBeat";
BA_ "SystemSignalLongSymbol" SG_ 1336 VCSEAT2L_a102_VEH_faultsAndExtra "VCSEAT2L_a102_VEH_faultsAndExtras";
BA_ "SystemSignalLongSymbol" SG_ 1336 VCSEAT2L_a108_PARTY_thermalContr "VCSEAT2L_a108_PARTY_thermalControl";
BA_ "SystemSignalLongSymbol" SG_ 1336 VCSEAT2L_a110_VEH_canLogAvailabi "VCSEAT2L_a110_VEH_canLogAvailability";
BA_ "SystemSignalLongSymbol" SG_ 1336 VCSEAT2L_a110_CH_airbagCutoffSta "VCSEAT2L_a110_CH_airbagCutoffStatus";
BA_ "SystemSignalLongSymbol" SG_ 1336 VCSEAT2L_a111_RIPC_epbPrivateSta "VCSEAT2L_a111_RIPC_epbPrivateState";
BA_ "SystemSignalLongSymbol" SG_ 1336 VCSEAT2L_a112_LIPC_epbPrivateSta "VCSEAT2L_a112_LIPC_epbPrivateState";
BA_ "SystemSignalLongSymbol" SG_ 1336 VCSEAT2L_a114_PARTY_wheelRotatio "VCSEAT2L_a114_PARTY_wheelRotation";
BA_ "SystemSignalLongSymbol" SG_ 1336 VCSEAT2L_a115_VEH_BLEResetReques "VCSEAT2L_a115_VEH_BLEResetRequest";
BA_ "SystemSignalLongSymbol" SG_ 1336 VCSEAT2L_a115_UI_corianderVehicl "VCSEAT2L_a115_UI_corianderVehicleControl";
BA_ "SystemSignalLongSymbol" SG_ 1336 VCSEAT2L_a116_VEH_restraintStatu "VCSEAT2L_a116_VEH_restraintStatus";
BA_ "SystemSignalLongSymbol" SG_ 1336 VCSEAT2L_a116_PARTY_restraintSta "VCSEAT2L_a116_PARTY_restraintStatus";
BA_ "SystemSignalLongSymbol" SG_ 1336 VCSEAT2L_a116_BDY_restraintStatu "VCSEAT2L_a116_BDY_restraintStatus";
BA_ "SystemSignalLongSymbol" SG_ 1336 VCSEAT2L_a117_BDY_restraintStatu "VCSEAT2L_a117_BDY_restraintStatus";
BA_ "SystemSignalLongSymbol" SG_ 1336 VCSEAT2L_a117_VEH_restraintStatu "VCSEAT2L_a117_VEH_restraintStatus";
BA_ "SystemSignalLongSymbol" SG_ 1336 VCSEAT2L_a117_BDY_falconSwitchSt "VCSEAT2L_a117_BDY_falconSwitchStatus";
BA_ "SystemSignalLongSymbol" SG_ 1336 VCSEAT2L_a117_VEH_intrusionSenso "VCSEAT2L_a117_VEH_intrusionSensorStatus";
BA_ "SystemSignalLongSymbol" SG_ 1336 VCSEAT2L_a117_PARTY_restraintSta "VCSEAT2L_a117_PARTY_restraintStatus";
BA_ "SystemSignalLongSymbol" SG_ 1336 VCSEAT2L_a117_PARTY_lightingSeco "VCSEAT2L_a117_PARTY_lightingSecondary";
BA_ "SystemSignalLongSymbol" SG_ 1336 VCSEAT2L_a118_VEH_12VBatteryStat "VCSEAT2L_a118_VEH_12VBatteryStatus";
BA_ "SystemSignalLongSymbol" SG_ 1336 VCSEAT2L_a118_PARTY_outputPowerS "VCSEAT2L_a118_PARTY_outputPowerStatus";
BA_ "SystemSignalLongSymbol" SG_ 1336 VCSEAT2L_a118_VEH_interNodeResis "VCSEAT2L_a118_VEH_interNodeResistance";
BA_ "SystemSignalLongSymbol" SG_ 1336 VCSEAT2L_a118_CH_12VBatteryStatu "VCSEAT2L_a118_CH_12VBatteryStatus";
BA_ "SystemSignalLongSymbol" SG_ 1336 VCSEAT2L_a118_CH_LVBMS_statusHig "VCSEAT2L_a118_CH_LVBMS_statusHigh";
BA_ "SystemSignalLongSymbol" SG_ 1336 VCSEAT2L_a118_BDY_outputPowerSta "VCSEAT2L_a118_BDY_outputPowerStatus";
BA_ "SystemSignalLongSymbol" SG_ 1336 VCSEAT2L_a118_PARTY_AP_vehicleSt "VCSEAT2L_a118_PARTY_AP_vehicleState1HzMuxed";
BA_ "SystemSignalLongSymbol" SG_ 1336 VCSEAT2L_a118_BDY_AP_vehicleStat "VCSEAT2L_a118_BDY_AP_vehicleState1HzMuxed";
BA_ "SystemSignalLongSymbol" SG_ 1336 VCSEAT2L_a118_PARTY_VCFRONT_came "VCSEAT2L_a118_PARTY_VCFRONT_cameraCleaningStatus";
BA_ "SystemSignalLongSymbol" SG_ 1336 VCSEAT2L_a120_PARTY_vehicleEstim "VCSEAT2L_a120_PARTY_vehicleEstimates";
BA_ "SystemSignalLongSymbol" SG_ 1336 VCSEAT2L_a120_VEH_aggregatedAxle "VCSEAT2L_a120_VEH_aggregatedAxleSpeed";
BA_ "SystemSignalLongSymbol" SG_ 1336 VCSEAT2L_a120_PARTY_aggregatedAx "VCSEAT2L_a120_PARTY_aggregatedAxleSpeed";
BA_ "SystemSignalLongSymbol" SG_ 1336 VCSEAT2L_a120_PARTY_autonomyHeal "VCSEAT2L_a120_PARTY_autonomyHealth";
BA_ "SystemSignalLongSymbol" SG_ 1336 VCSEAT2L_a120_PARTY_stalklessInt "VCSEAT2L_a120_PARTY_stalklessInterfaces";
BA_ "SystemSignalLongSymbol" SG_ 1336 VCSEAT2L_a120_VEH_estimatedBrake "VCSEAT2L_a120_VEH_estimatedBrakeTemp";
BA_ "SystemSignalLongSymbol" SG_ 1336 VCSEAT2L_a120_VEH_vehicleEstimat "VCSEAT2L_a120_VEH_vehicleEstimates";
BA_ "SystemSignalLongSymbol" SG_ 1336 VCSEAT2L_a210_seatMotorCalibrate "VCSEAT2L_a210_seatMotorCalibrated";
BA_ "Confidence" SG_ 1336 VCSEAT2L_a210_seatMotorCurrent 1;
BA_ "Confidence" SG_ 1336 VCSEAT2L_a210_seatMotorState 1;
BA_ "Confidence" SG_ 1336 VCSEAT2L_a210_seatSwitchBack 1;
BA_ "GenSigSNA" SG_ 1336 VCSEAT2L_a210_seatSwitchBack "0";
BA_ "Confidence" SG_ 1336 VCSEAT2L_a210_seatSwitchForward 1;
BA_ "GenSigSNA" SG_ 1336 VCSEAT2L_a210_seatSwitchForward "0";
BA_ "Confidence" SG_ 1336 VCSEAT2L_a211_seatMotorCurrent 1;
BA_ "Confidence" SG_ 1336 VCSEAT2L_a211_seatMotorPosReal 1;
BA_ "Confidence" SG_ 1336 VCSEAT2L_a211_seatMotorState 1;
BA_ "Confidence" SG_ 1336 VCSEAT2L_a211_seatSwitchBack 1;
BA_ "GenSigSNA" SG_ 1336 VCSEAT2L_a211_seatSwitchBack "0";
BA_ "Confidence" SG_ 1336 VCSEAT2L_a211_seatSwitchForward 1;
BA_ "GenSigSNA" SG_ 1336 VCSEAT2L_a211_seatSwitchForward "0";
BA_ "Confidence" SG_ 1336 VCSEAT2L_a212_seatMotorCurrent 1;
BA_ "Confidence" SG_ 1336 VCSEAT2L_a212_seatMotorPosReal 1;
BA_ "Confidence" SG_ 1336 VCSEAT2L_a212_seatMotorState 1;
BA_ "Confidence" SG_ 1336 VCSEAT2L_a212_seatSwitchBack 1;
BA_ "GenSigSNA" SG_ 1336 VCSEAT2L_a212_seatSwitchBack "0";
BA_ "Confidence" SG_ 1336 VCSEAT2L_a212_seatSwitchForward 1;
BA_ "GenSigSNA" SG_ 1336 VCSEAT2L_a212_seatSwitchForward "0";
BA_ "SystemSignalLongSymbol" SG_ 1336 VCSEAT2L_a213_seatMotorCalibrate "VCSEAT2L_a213_seatMotorCalibrated";
BA_ "Confidence" SG_ 1336 VCSEAT2L_a213_seatMotorCurrent 1;
BA_ "Confidence" SG_ 1336 VCSEAT2L_a213_seatMotorPosReal 1;
BA_ "Confidence" SG_ 1336 VCSEAT2L_a213_seatMotorState 1;
BA_ "Confidence" SG_ 1336 VCSEAT2L_a213_seatSwitchBack 1;
BA_ "GenSigSNA" SG_ 1336 VCSEAT2L_a213_seatSwitchBack "0";
BA_ "Confidence" SG_ 1336 VCSEAT2L_a213_seatSwitchForward 1;
BA_ "GenSigSNA" SG_ 1336 VCSEAT2L_a213_seatSwitchForward "0";
BA_ "Confidence" SG_ 1336 VCSEAT2L_a214_seatMotorCurrent 1;
BA_ "Confidence" SG_ 1336 VCSEAT2L_a214_seatMotorDCurrent 1;
BA_ "Confidence" SG_ 1336 VCSEAT2L_a214_seatMotorPosReal 1;
BA_ "Confidence" SG_ 1336 VCSEAT2L_a214_seatMotorState 1;
BA_ "Confidence" SG_ 1336 VCSEAT2L_a215_seatMotorCurrent 1;
BA_ "Confidence" SG_ 1336 VCSEAT2L_a215_seatMotorDCurrent 1;
BA_ "Confidence" SG_ 1336 VCSEAT2L_a215_seatMotorPosReal 1;
BA_ "Confidence" SG_ 1336 VCSEAT2L_a215_seatMotorState 1;
BA_ "SystemSignalLongSymbol" SG_ 1336 VCSEAT2L_a224_seatMotorCalibrate "VCSEAT2L_a224_seatMotorCalibrated";
BA_ "Confidence" SG_ 1336 VCSEAT2L_a224_seatMotorCurrent 1;
BA_ "Confidence" SG_ 1336 VCSEAT2L_a224_seatMotorState 1;
BA_ "Confidence" SG_ 1336 VCSEAT2L_a224_seatSwitchBack 1;
BA_ "GenSigSNA" SG_ 1336 VCSEAT2L_a224_seatSwitchBack "0";
BA_ "Confidence" SG_ 1336 VCSEAT2L_a224_seatSwitchForward 1;
BA_ "GenSigSNA" SG_ 1336 VCSEAT2L_a224_seatSwitchForward "0";
BA_ "SystemSignalLongSymbol" SG_ 1336 VCSEAT2L_a225_seatMotorCalibrate "VCSEAT2L_a225_seatMotorCalibrated";
BA_ "Confidence" SG_ 1336 VCSEAT2L_a225_seatMotorCurrent 1;
BA_ "Confidence" SG_ 1336 VCSEAT2L_a225_seatMotorState 1;
BA_ "Confidence" SG_ 1336 VCSEAT2L_a225_seatSwitchBack 1;
BA_ "GenSigSNA" SG_ 1336 VCSEAT2L_a225_seatSwitchBack "0";
BA_ "Confidence" SG_ 1336 VCSEAT2L_a225_seatSwitchForward 1;
BA_ "GenSigSNA" SG_ 1336 VCSEAT2L_a225_seatSwitchForward "0";
BA_ "SystemSignalLongSymbol" SG_ 1336 VCSEAT2L_a228_seatMotorCalibrate "VCSEAT2L_a228_seatMotorCalibrated";
BA_ "Confidence" SG_ 1336 VCSEAT2L_a228_seatMotorCurrent 1;
BA_ "Confidence" SG_ 1336 VCSEAT2L_a228_seatMotorPosReal 1;
BA_ "Confidence" SG_ 1336 VCSEAT2L_a228_seatMotorState 1;
BA_ "Confidence" SG_ 1336 VCSEAT2L_a228_seatSwitchBack 1;
BA_ "GenSigSNA" SG_ 1336 VCSEAT2L_a228_seatSwitchBack "0";
BA_ "Confidence" SG_ 1336 VCSEAT2L_a228_seatSwitchForward 1;
BA_ "GenSigSNA" SG_ 1336 VCSEAT2L_a228_seatSwitchForward "0";
BA_ "SystemSignalLongSymbol" SG_ 1336 VCSEAT2L_a229_seatMotorCalibrate "VCSEAT2L_a229_seatMotorCalibrated";
BA_ "Confidence" SG_ 1336 VCSEAT2L_a229_seatMotorCurrent 1;
BA_ "Confidence" SG_ 1336 VCSEAT2L_a229_seatMotorPosReal 1;
BA_ "Confidence" SG_ 1336 VCSEAT2L_a229_seatMotorState 1;
BA_ "Confidence" SG_ 1336 VCSEAT2L_a229_seatSwitchBack 1;
BA_ "GenSigSNA" SG_ 1336 VCSEAT2L_a229_seatSwitchBack "0";
BA_ "Confidence" SG_ 1336 VCSEAT2L_a229_seatSwitchForward 1;
BA_ "GenSigSNA" SG_ 1336 VCSEAT2L_a229_seatSwitchForward "0";
BA_ "Confidence" SG_ 1336 VCSEAT2L_a232_seatMotorCurrent 1;
BA_ "Confidence" SG_ 1336 VCSEAT2L_a232_seatMotorPosReal 1;
BA_ "Confidence" SG_ 1336 VCSEAT2L_a232_seatMotorState 1;
BA_ "Confidence" SG_ 1336 VCSEAT2L_a232_seatSwitchBack 1;
BA_ "GenSigSNA" SG_ 1336 VCSEAT2L_a232_seatSwitchBack "0";
BA_ "Confidence" SG_ 1336 VCSEAT2L_a232_seatSwitchForward 1;
BA_ "GenSigSNA" SG_ 1336 VCSEAT2L_a232_seatSwitchForward "0";
BA_ "Confidence" SG_ 1336 VCSEAT2L_a233_seatMotorCurrent 1;
BA_ "Confidence" SG_ 1336 VCSEAT2L_a233_seatMotorPosReal 1;
BA_ "Confidence" SG_ 1336 VCSEAT2L_a233_seatMotorState 1;
BA_ "Confidence" SG_ 1336 VCSEAT2L_a233_seatSwitchBack 1;
BA_ "GenSigSNA" SG_ 1336 VCSEAT2L_a233_seatSwitchBack "0";
BA_ "Confidence" SG_ 1336 VCSEAT2L_a233_seatSwitchForward 1;
BA_ "GenSigSNA" SG_ 1336 VCSEAT2L_a233_seatSwitchForward "0";
BA_ "Confidence" SG_ 1336 VCSEAT2L_a239_seatHeatCurrent 1;
BA_ "Confidence" SG_ 1336 VCSEAT2L_a239_seatHeatTmp 1;
BA_ "Confidence" SG_ 1336 VCSEAT2L_a239_seatHeatTmpTarget 1;
BA_ "Confidence" SG_ 1336 VCSEAT2L_a240_seatHeatCurrent 1;
BA_ "Confidence" SG_ 1336 VCSEAT2L_a240_seatHeatTmp 1;
BA_ "Confidence" SG_ 1336 VCSEAT2L_a251_seatMotorCurrent 1;
BA_ "Confidence" SG_ 1336 VCSEAT2L_a251_seatMotorPosReal 1;
BA_ "Confidence" SG_ 1336 VCSEAT2L_a251_seatMotorState 1;
BA_ "Confidence" SG_ 1336 VCSEAT2L_a251_seatSwitchBack 1;
BA_ "GenSigSNA" SG_ 1336 VCSEAT2L_a251_seatSwitchBack "0";
BA_ "Confidence" SG_ 1336 VCSEAT2L_a251_seatSwitchForward 1;
BA_ "GenSigSNA" SG_ 1336 VCSEAT2L_a251_seatSwitchForward "0";
BA_ "Confidence" SG_ 1336 VCSEAT2L_a252_seatMotorCurrent 1;
BA_ "Confidence" SG_ 1336 VCSEAT2L_a252_seatMotorPosReal 1;
BA_ "Confidence" SG_ 1336 VCSEAT2L_a252_seatMotorState 1;
BA_ "Confidence" SG_ 1336 VCSEAT2L_a252_seatSwitchBack 1;
BA_ "GenSigSNA" SG_ 1336 VCSEAT2L_a252_seatSwitchBack "0";
BA_ "Confidence" SG_ 1336 VCSEAT2L_a252_seatSwitchForward 1;
BA_ "GenSigSNA" SG_ 1336 VCSEAT2L_a252_seatSwitchForward "0";
BA_ "Confidence" SG_ 1336 VCSEAT2L_a260_seatStatePrev 1;
BA_ "Confidence" SG_ 1336 VCSEAT2L_a260_obstacleDetectReas 1;
BA_ "SystemSignalLongSymbol" SG_ 1336 VCSEAT2L_a260_obstacleDetectReas "VCSEAT2L_a260_obstacleDetectReason";
BA_ "Confidence" SG_ 1336 VCSEAT2L_a260_obstacleDetectPosi 1;
BA_ "SystemSignalLongSymbol" SG_ 1336 VCSEAT2L_a260_obstacleDetectPosi "VCSEAT2L_a260_obstacleDetectPosition";
BA_ "SystemSignalLongSymbol" SG_ 1336 VCSEAT2L_a260_accelLookbackTripD "VCSEAT2L_a260_accelLookbackTripDepth";
BA_ "Confidence" SG_ 1336 VCSEAT2L_a260_seatMotorCurrent 1;
BA_ "Confidence" SG_ 1336 VCSEAT2L_a261_seatStatePrev 1;
BA_ "Confidence" SG_ 1336 VCSEAT2L_a261_obstacleDetectReas 1;
BA_ "SystemSignalLongSymbol" SG_ 1336 VCSEAT2L_a261_obstacleDetectReas "VCSEAT2L_a261_obstacleDetectReason";
BA_ "Confidence" SG_ 1336 VCSEAT2L_a261_obstacleDetectPosi 1;
BA_ "SystemSignalLongSymbol" SG_ 1336 VCSEAT2L_a261_obstacleDetectPosi "VCSEAT2L_a261_obstacleDetectPosition";
BA_ "SystemSignalLongSymbol" SG_ 1336 VCSEAT2L_a261_accelLookbackTripD "VCSEAT2L_a261_accelLookbackTripDepth";
BA_ "Confidence" SG_ 1336 VCSEAT2L_a261_seatMotorCurrent 1;
BA_ "Confidence" SG_ 1336 VCSEAT2L_a263_seatMotorCurrent 1;
BA_ "Confidence" SG_ 1336 VCSEAT2L_a263_seatMotorDCurrent 1;
BA_ "Confidence" SG_ 1336 VCSEAT2L_a263_seatMotorPosReal 1;
BA_ "Confidence" SG_ 1336 VCSEAT2L_a263_seatMotorState 1;
BA_ "Confidence" SG_ 1336 VCSEAT2L_a264_seatMotorCurrent 1;
BA_ "Confidence" SG_ 1336 VCSEAT2L_a264_seatMotorDCurrent 1;
BA_ "Confidence" SG_ 1336 VCSEAT2L_a264_seatMotorPosReal 1;
BA_ "Confidence" SG_ 1336 VCSEAT2L_a264_seatMotorState 1;
BA_ "Confidence" SG_ 1336 VCSEAT2L_a267_seatMotorCurrent 1;
BA_ "Confidence" SG_ 1336 VCSEAT2L_a267_seatMotorDCurrent 1;
BA_ "Confidence" SG_ 1336 VCSEAT2L_a267_seatMotorPosReal 1;
BA_ "Confidence" SG_ 1336 VCSEAT2L_a267_seatMotorState 1;
BA_ "Confidence" SG_ 1336 VCSEAT2L_a268_seatMotorCurrent 1;
BA_ "Confidence" SG_ 1336 VCSEAT2L_a268_seatMotorDCurrent 1;
BA_ "Confidence" SG_ 1336 VCSEAT2L_a268_seatMotorPosReal 1;
BA_ "Confidence" SG_ 1336 VCSEAT2L_a268_seatMotorState 1;
BA_ "SystemSignalLongSymbol" SG_ 1336 VCSEAT2L_a270_isRearwardEndstopU "VCSEAT2L_a270_isRearwardEndstopUncalibrated";
BA_ "SystemSignalLongSymbol" SG_ 1336 VCSEAT2L_a270_isAbsPosSensorUnca "VCSEAT2L_a270_isAbsPosSensorUncalibrated";
BA_ "Confidence" SG_ 1336 VCSEAT2L_a270_seatState 1;
BA_ "GenSigSNA" SG_ 1336 VCSEAT2L_a270_seatState "15";
BA_ "Confidence" SG_ 1336 VCSEAT2L_a270_motorType 1;
BA_ "Confidence" SG_ 1336 VCSEAT2L_a270_absPosSensState 1;
BA_ "Confidence" SG_ 1336 VCSEAT2L_a273_angle 1;
BA_ "Confidence" SG_ 1336 VCSEAT2L_a273_seatStatePrev 1;
BA_ "GenSigSNA" SG_ 1336 VCSEAT2L_a273_seatStatePrev "15";
BA_ "Confidence" SG_ 1336 VCSEAT2L_a273_obstacleDetectReas 1;
BA_ "SystemSignalLongSymbol" SG_ 1336 VCSEAT2L_a273_obstacleDetectReas "VCSEAT2L_a273_obstacleDetectReason";
BA_ "SystemSignalLongSymbol" SG_ 1336 VCSEAT2L_a273_accelLookbackTripD "VCSEAT2L_a273_accelLookbackTripDepth";
BA_ "Confidence" SG_ 1336 VCSEAT2L_a273_duty 1;
BA_ "Confidence" SG_ 1336 VCSEAT2L_a273_currentAbsFilt 1;
BA_ "Confidence" SG_ 1336 VCSEAT2L_a273_motorType 1;
BA_ "SystemSignalLongSymbol" SG_ 1336 VCSEAT2L_a273_absolutePosSensorF "VCSEAT2L_a273_absolutePosSensorForward";
BA_ "Confidence" SG_ 1336 VCSEAT2L_a273_cabinTemp 1;
BA_ "SystemSignalLongSymbol" SG_ 1336 VCSEAT2L_a277_isRearwardEndstopU "VCSEAT2L_a277_isRearwardEndstopUncalibrated";
BA_ "SystemSignalLongSymbol" SG_ 1336 VCSEAT2L_a277_isAbsPosSensorUnca "VCSEAT2L_a277_isAbsPosSensorUncalibrated";
BA_ "Confidence" SG_ 1336 VCSEAT2L_a278_seatState 1;
BA_ "GenSigSNA" SG_ 1336 VCSEAT2L_a278_seatState "15";
BA_ "Confidence" SG_ 1336 VCSEAT2L_a290_occupancySensorV 1;
BA_ "Confidence" SG_ 1336 VCSEAT2L_a290_railVoltage 1;
BA_ "Confidence" SG_ 1336 VCSEAT2L_a291_buckleSensorVoltag 1;
BA_ "SystemSignalLongSymbol" SG_ 1336 VCSEAT2L_a291_buckleSensorVoltag "VCSEAT2L_a291_buckleSensorVoltage";
BA_ "Confidence" SG_ 1336 VCSEAT2L_a291_railVoltage 1;
BA_ "SystemSignalLongSymbol" SG_ 1336 VCSEAT2L_a426_seatMotorCalibrate "VCSEAT2L_a426_seatMotorCalibrated";
BA_ "Confidence" SG_ 1336 VCSEAT2L_a426_seatMotorCurrent 1;
BA_ "Confidence" SG_ 1336 VCSEAT2L_a426_seatMotorPosReal 1;
BA_ "Confidence" SG_ 1336 VCSEAT2L_a426_seatMotorState 1;
BA_ "Confidence" SG_ 1336 VCSEAT2L_a426_seatSwitchBack 1;
BA_ "GenSigSNA" SG_ 1336 VCSEAT2L_a426_seatSwitchBack "0";
BA_ "Confidence" SG_ 1336 VCSEAT2L_a426_seatSwitchForward 1;
BA_ "GenSigSNA" SG_ 1336 VCSEAT2L_a426_seatSwitchForward "0";
BA_ "Confidence" SG_ 1336 VCSEAT2L_a426_cabinTmp 1;
BA_ "SystemSignalLongSymbol" SG_ 1336 VCSEAT2L_a427_seatMotorCalibrate "VCSEAT2L_a427_seatMotorCalibrated";
BA_ "Confidence" SG_ 1336 VCSEAT2L_a427_seatMotorCurrent 1;
BA_ "Confidence" SG_ 1336 VCSEAT2L_a427_seatMotorPosReal 1;
BA_ "Confidence" SG_ 1336 VCSEAT2L_a427_seatMotorState 1;
BA_ "Confidence" SG_ 1336 VCSEAT2L_a427_seatSwitchBack 1;
BA_ "GenSigSNA" SG_ 1336 VCSEAT2L_a427_seatSwitchBack "0";
BA_ "Confidence" SG_ 1336 VCSEAT2L_a427_seatSwitchForward 1;
BA_ "GenSigSNA" SG_ 1336 VCSEAT2L_a427_seatSwitchForward "0";
BA_ "Confidence" SG_ 1336 VCSEAT2L_a427_cabinTmp 1;
BA_ "SystemSignalLongSymbol" SG_ 1336 VCSEAT2L_a428_seatMotorCalibrate "VCSEAT2L_a428_seatMotorCalibrated";
BA_ "Confidence" SG_ 1336 VCSEAT2L_a428_seatMotorCurrent 1;
BA_ "Confidence" SG_ 1336 VCSEAT2L_a428_seatMotorPosReal 1;
BA_ "Confidence" SG_ 1336 VCSEAT2L_a428_seatMotorState 1;
BA_ "Confidence" SG_ 1336 VCSEAT2L_a428_seatSwitchBack 1;
BA_ "GenSigSNA" SG_ 1336 VCSEAT2L_a428_seatSwitchBack "0";
BA_ "Confidence" SG_ 1336 VCSEAT2L_a428_seatSwitchForward 1;
BA_ "GenSigSNA" SG_ 1336 VCSEAT2L_a428_seatSwitchForward "0";
BA_ "Confidence" SG_ 1336 VCSEAT2L_a428_cabinTmp 1;
BA_ "SystemSignalLongSymbol" SG_ 1336 VCSEAT2L_a429_seatMotorCalibrate "VCSEAT2L_a429_seatMotorCalibrated";
BA_ "Confidence" SG_ 1336 VCSEAT2L_a429_seatMotorCurrent 1;
BA_ "Confidence" SG_ 1336 VCSEAT2L_a429_seatMotorPosReal 1;
BA_ "Confidence" SG_ 1336 VCSEAT2L_a429_seatMotorState 1;
BA_ "Confidence" SG_ 1336 VCSEAT2L_a429_seatSwitchBack 1;
BA_ "GenSigSNA" SG_ 1336 VCSEAT2L_a429_seatSwitchBack "0";
BA_ "Confidence" SG_ 1336 VCSEAT2L_a429_seatSwitchForward 1;
BA_ "GenSigSNA" SG_ 1336 VCSEAT2L_a429_seatSwitchForward "0";
BA_ "Confidence" SG_ 1336 VCSEAT2L_a429_cabinTmp 1;
BA_ "SystemSignalLongSymbol" SG_ 1336 VCSEAT2L_a444_highSide2GateDrive "VCSEAT2L_a444_highSide2GateDriver";
BA_ "SystemSignalLongSymbol" SG_ 1336 VCSEAT2L_a444_highSide1GateDrive "VCSEAT2L_a444_highSide1GateDriver";
BA_ "SystemSignalLongSymbol" SG_ 1336 VCSEAT2L_a444_highSide2OverCuren "VCSEAT2L_a444_highSide2OverCurent";
BA_ "SystemSignalLongSymbol" SG_ 1336 VCSEAT2L_a444_highSide1OverCuren "VCSEAT2L_a444_highSide1OverCurent";
BA_ "Confidence" SG_ 1336 VCSEAT2L_a571_seatHeatCurrent 1;
BA_ "Confidence" SG_ 1336 VCSEAT2L_a571_seatHeatTmp 1;
VAL_ 1279 UI_energyConsumptionInfoIndex 21 "21" 20 "20" 19 "19" 18 "18" 17 "17" 16 "16" 15 "15" 14 "14" 13 "13" 12 "12" 11 "11" 10 "10" 9 "9" 8 "8" 7 "7" 6 "6" 5 "5" 4 "4" 3 "3" 2 "2" 1 "1" 0 "0" ;
VAL_ 993 UI_gearSliderInfoIndex 2 "Neutral" 1 "Park" 0 "Slider" ;
VAL_ 666 UI_seatControlIndex 3 "3" 2 "2" 1 "1" 0 "0" ;
VAL_ 666 UI_3RSeatChildLock 3 "UI_ADJUSTABLE_FOLD_FLAT_CHILD_LOCK_BOTH" 2 "UI_ADJUSTABLE_FOLD_FLAT_CHILD_LOCK_RIGHT" 1 "UI_ADJUSTABLE_FOLD_FLAT_CHILD_LOCK_LEFT" 0 "UI_ADJUSTABLE_FOLD_FLAT_CHILD_LOCK_NONE" ;
VAL_ 666 UI_left3RowSeatAdjustmentRequest 6 "UI_ADJUSTABLE_FOLD_FLAT_REQUEST_STOP" 5 "UI_ADJUSTABLE_FOLD_FLAT_REQUEST_TOGGLE_FOLD" 4 "UI_ADJUSTABLE_FOLD_FLAT_REQUEST_REARWARD_FAST" 3 "UI_ADJUSTABLE_FOLD_FLAT_REQUEST_REARWARD_COMFORT" 2 "UI_ADJUSTABLE_FOLD_FLAT_REQUEST_FORWARD_FAST" 1 "UI_ADJUSTABLE_FOLD_FLAT_REQUEST_FORWARD_COMFORT" 0 "UI_ADJUSTABLE_FOLD_FLAT_REQUEST_NONE" ;
VAL_ 666 UI_right3RowSeatAdjustmentReques 6 "UI_ADJUSTABLE_FOLD_FLAT_REQUEST_STOP" 5 "UI_ADJUSTABLE_FOLD_FLAT_REQUEST_TOGGLE_FOLD" 4 "UI_ADJUSTABLE_FOLD_FLAT_REQUEST_REARWARD_FAST" 3 "UI_ADJUSTABLE_FOLD_FLAT_REQUEST_REARWARD_COMFORT" 2 "UI_ADJUSTABLE_FOLD_FLAT_REQUEST_FORWARD_FAST" 1 "UI_ADJUSTABLE_FOLD_FLAT_REQUEST_FORWARD_COMFORT" 0 "UI_ADJUSTABLE_FOLD_FLAT_REQUEST_NONE" ;
VAL_ 666 UI_2RLeftSeatFanReq 3 "FAN_REQUEST_LEVEL3" 2 "FAN_REQUEST_LEVEL2" 1 "FAN_REQUEST_LEVEL1" 0 "FAN_REQUEST_OFF" ;
VAL_ 666 UI_2RRightSeatFanReq 3 "FAN_REQUEST_LEVEL3" 2 "FAN_REQUEST_LEVEL2" 1 "FAN_REQUEST_LEVEL1" 0 "FAN_REQUEST_OFF" ;
VAL_ 563 UI_gearRequest 4 "GEAR_REQUEST_DRIVE" 3 "GEAR_REQUEST_NEUTRAL" 2 "GEAR_REQUEST_REVERSE" 1 "GEAR_REQUEST_PARK" 0 "GEAR_REQUEST_IDLE_SNA" ;
VAL_ 563 UI_autopilotRequest 1 "PRESSED" 0 "IDLE" ;
VAL_ 563 UI_gearStripLocation 1 "RIGHT" 0 "LEFT" ;
VAL_ 986 UI_wifiRegDomain 67 "AZ" 66 "SR" 65 "SM" 64 "MS" 63 "MT" 62 "LV" 61 "LT" 60 "LI" 59 "GI" 58 "CY" 57 "AD" 56 "PT" 55 "MU" 54 "LU" 53 "EE" 52 "BG" 51 "BR" 50 "IN" 49 "IE" 48 "IS" 47 "AE" 46 "TR" 45 "ES" 44 "SI" 43 "SK" 42 "RO" 41 "PR" 40 "PL" 39 "HU" 38 "GR" 37 "FI" 36 "HR" 35 "CZ" 34 "NZ" 33 "MO" 32 "SA" 31 "PH" 30 "CO" 29 "QA" 28 "CL" 27 "MY" 26 "TH" 25 "SG" 24 "JO" 23 "MX" 22 "TW" 21 "KR" 20 "RU" 19 "GB" 18 "IL" 17 "AU" 16 "JP" 15 "HK" 14 "CN" 13 "UK" 12 "SE" 11 "CH" 10 "NO" 9 "DK" 8 "BE" 7 "AT" 6 "NL" 5 "IT" 4 "FR" 3 "DE" 2 "CA" 1 "US" 0 "UNKNOWN" ;
VAL_ 661 UI_systemMonitorIndex 1 "1" 0 "0" ;
VAL_ 139 UI_maxSpeedToReachDestination 65535 "SNA" 65534 "UNREACHABLE" 65533 "MAXVAL" ;
VAL_ 139 UI_remainingWeightedRMSSpeed 65535 "SNA" 65534 "MAXVAL" ;
VAL_ 139 UI_timeToDestination 65535 "SNA" 65534 "MAXVAL" ;
VAL_ 1173 UI_predictedEnergy -32767 "TRIP_TOO_LONG" -32768 "SNA" ;
VAL_ 1173 UI_predictedEnergyLearned -32767 "TRIP_TOO_LONG" -32768 "SNA" ;
VAL_ 1173 UI_hindsightEnergy -32767 "TRIP_TOO_LONG" -32768 "SNA" ;
VAL_ 1173 UI_hindsightEnergyLearned -32767 "TRIP_TOO_LONG" -32768 "SNA" ;
VAL_ 1174 UI_longTermEnergyModelError 127 "MAXVAL" -128 "SNA" ;
VAL_ 1174 UI_longTermRmsSpeedRatio 255 "SNA" 254 "MAXVAL" ;
VAL_ 1174 UI_gradeCorrectedEnergy -32767 "TRIP_TOO_LONG" -32768 "SNA" ;
VAL_ 1174 UI_gradeCorrectedEnergyLearned -32767 "TRIP_TOO_LONG" -32768 "SNA" ;
VAL_ 1175 UI_battPreconditionOnNavTime 65535 "SNA" 65534 "MAXVAL" ;
VAL_ 1175 UI_maxBattPreconditionOnNavTime 65535 "SNA" 65534 "MAXVAL" ;
VAL_ 649 VCLEFT_logging10HzIndex 1 "END" 0 "HVAC_VARS" ;
VAL_ 649 VCLEFT_hvacBlowerRs 255 "SNA" ;
VAL_ 649 VCLEFT_hvacBlowerIPhase0 127 "SNA" ;
VAL_ 649 VCLEFT_hvacBlowerIPhase1 127 "SNA" ;
VAL_ 649 VCLEFT_hvacBlowerIPhase2 127 "SNA" ;
VAL_ 649 VCLEFT_hvacBlower_IO_CBC_Status 1 "RX" 0 "IDLE" ;
VAL_ 649 VCLEFT_hvacBlowerCBCEstState 14 "COUNT" 13 "ONLINE" 12 "MOTOR_IDENTIFIED" 11 "ROTOR_RESISTANCE" 10 "INDUCTANCE_EST" 9 "LOCKROTOR" 8 "RAMPDOWN" 7 "RATEDFLUX" 6 "RATEDFLUX_OL" 5 "IDRATED" 4 "RAMPUP" 3 "RS" 2 "ROVERL" 1 "IDLE" 0 "ERROR" ;
VAL_ 649 VCLEFT_hvacBlowerCBCCtrlState 4 "COUNT" 3 "ONLINE" 2 "OFFLINE" 1 "IDLE" 0 "ERROR" ;
VAL_ 649 VCLEFT_hvacBlowerITerm 127 "SNA" ;
VAL_ 1336 VCSEAT2L_alertID 571 "a571_seatHeatDisabledRear" 550 "a550_ambientTempDelta" 526 "a526_pcbaOverTemperature" 445 "a445_drv8703SpiFaultDBG" 444 "a444_drv8703Fault" 429 "a429_seatAbuseBufferFull" 428 "a428_seatAbuseBufferWarn" 427 "a427_seatAbuseMotorStop" 426 "a426_seatAbuseMotorWarn" 291 "a291_buckleFaultedRow2" 290 "a290_occupancyFaultRow2" 280 "a280_seatStatsFromLastStateDbg2" 279 "a279_seatOverfolded" 278 "a278_seatClashAvoidanceBlocked" 277 "a277_seatRequestWhileUncalibrated" 276 "a276_seatStatsFromLastStateDbg" 275 "a275_seatAbsPosSensorTransitionDbg" 274 "a274_seatTempHigh" 273 "a273_seatObstacleDetected" 272 "a272_seatAbsPosOffsetApplied" 271 "a271_seatPositionNonsensical" 270 "a270_seatUncalibrated" 268 "a268_seatBackHCEncStlDbg" 267 "a267_seatTrackHCEncStl" 264 "a264_seatBackStallDebug" 263 "a263_seatTrackStallDebug" 261 "a261_seatArmrestObstacleDetected" 260 "a260_seatTrackObstacleDetected" 252 "a252_seatUncalBack" 251 "a251_seatUncalTrack" 245 "a245_seatArmrestEcuLogStatus" 244 "a244_seatArmrestSpeedTableReferenceStatus" 243 "a243_seatArmrestHistoryScoreDbg" 242 "a242_seatHeatTmpRow2" 241 "a241_seatArmrestHistoryScore" 240 "a240_seatHeatShortRow2" 239 "a239_seatHeatIRow2" 238 "a238_seatArmrestInhibitedByBackrest" 237 "a237_seatArmrestStatsFromLastStateDbg2" 236 "a236_seatArmrestStatsFromLastStateDbg" 235 "a235_seatTrackStatsFromLastStateDbg2" 234 "a234_seatTrackStatsFromLastStateDbg" 233 "a233_seatCurrUnderBack" 232 "a232_seatCurrUnderTrack" 229 "a229_seatEncOverBack" 228 "a228_seatEncOverTrack" 225 "a225_seatEncStallBack" 224 "a224_seatEncStallTrack" 219 "a219_motorCurrentDropout" 218 "a218_motorDriverFault" 215 "a215_armrestHCEncStlDbg" 214 "a214_armrestStallDebug" 213 "a213_armrestEncOver" 212 "a212_armrestUncal" 211 "a211_armrestCurrUnder" 210 "a210_armrestEncStall" 201 "a201_motorDutyEncDisabl" 200 "a200_motorPhantomEncoder" 191 "a191_seatChoreographyIsBlockedBySecondSeat" 190 "a190_seatChoreographyIsBlockedByFrontSeat" 120 "a120_DI_DRIVE_MIA" 119 "a119_SCCM_MIA" 118 "a118_VCFRONT_MIA" 117 "a117_VCLEFT_MIA" 116 "a116_VCRIGHT_MIA" 115 "a115_VCSEC_MIA" 114 "a114_ESP_MIA" 113 "a113_UI_MIA" 112 "a112_EPBL_MIA" 111 "a111_EPBR_MIA" 110 "a110_GTW_MIA" 109 "a109_RCM_MIA" 108 "a108_DIF_MIA" 107 "a107_BMS_MIA" 106 "a106_PCS_MIA" 105 "a105_TAS_MIA" 104 "a104_DAS_MIA" 103 "a103_CP_MIA" 102 "a102_PTC_MIA" 101 "a101_PM_MIA" 100 "a100_CANbus_MIA" 99 "a099_PARK_MIA" 98 "a098_DIR_MIA" 97 "a097_CMP_MIA" 96 "a096_OCS1P_MIA" 95 "a095_CHG_MIA" 94 "a094_EPAS3P_MIA" 93 "a093_VCSEATP_MIA" 92 "a092_VCSEATD_MIA" 91 "a091_CMPD_MIA" 90 "a090_APS_MIA" 89 "a089_IBST_MIA" 88 "a088_DIRER_MIA" 87 "a087_DIREL_MIA" 86 "a086_VCBATT_MIA" 85 "a085_CCCM_MIA" 84 "a084_TPMS_MIA" 83 "a083_VCLEFT_IPC_MIA" 82 "a082_VCRIGHT_IPC_MIA" 64 "a064_busSleepReqTimeout" 63 "a063_SwitchFault" 62 "a062_XCPWasConnected" 61 "a061_XCPConnected" 60 "a060_engineeringBuild" 59 "a059_inputResistanceHigh" 58 "a058_inputRHighSyncDebug" 57 "a057_HVP_MIA" 46 "a046_Task1000msError" 45 "a045_Task100msError" 44 "a044_Task10msError" 43 "a043_Task1msError" 42 "a042_HighStackUsage" 41 "a041_HighCPULoad" 31 "a031_UDSActive" 30 "a030_ECULogUploadRequest" 29 "a029_CoreDump" 22 "a022_TaskInitError" 21 "a021_TaskSchedulerError" 16 "a016_NVMMRecordError" 15 "a015_NVMMError" 13 "a013_AlertManagerFault" 12 "a012_CPUReset" 10 "a010_ExtSupplyVoltError" 6 "a006_CANTX_cyclicError" 5 "a005_CANTXError" 3 "a003_SWAssertion" 2 "a002_PowerLossReset" 1 "a001_WatchdogReset" 0 "ALERT_DO_NOT_USE_ZERO" ;
VAL_ 1336 VCSEAT2L_alertState 1 "SET" 0 "CLEARED" ;
VAL_ 1336 VCSEAT2L_a210_seatMotorState 5 "UNDEFINED" 4 "CALIBRATING" 3 "RECALLING" 2 "MOVING_DOWN" 1 "MOVING_UP" 0 "STOPPED" ;
VAL_ 1336 VCSEAT2L_a210_seatSwitchBack 3 "FAULT" 2 "ON" 1 "OFF" 0 "SNA" ;
VAL_ 1336 VCSEAT2L_a210_seatSwitchForward 3 "FAULT" 2 "ON" 1 "OFF" 0 "SNA" ;
VAL_ 1336 VCSEAT2L_a211_seatMotorState 5 "UNDEFINED" 4 "CALIBRATING" 3 "RECALLING" 2 "MOVING_DOWN" 1 "MOVING_UP" 0 "STOPPED" ;
VAL_ 1336 VCSEAT2L_a211_seatSwitchBack 3 "FAULT" 2 "ON" 1 "OFF" 0 "SNA" ;
VAL_ 1336 VCSEAT2L_a211_seatSwitchForward 3 "FAULT" 2 "ON" 1 "OFF" 0 "SNA" ;
VAL_ 1336 VCSEAT2L_a212_seatMotorState 5 "UNDEFINED" 4 "CALIBRATING" 3 "RECALLING" 2 "MOVING_DOWN" 1 "MOVING_UP" 0 "STOPPED" ;
VAL_ 1336 VCSEAT2L_a212_seatSwitchBack 3 "FAULT" 2 "ON" 1 "OFF" 0 "SNA" ;
VAL_ 1336 VCSEAT2L_a212_seatSwitchForward 3 "FAULT" 2 "ON" 1 "OFF" 0 "SNA" ;
VAL_ 1336 VCSEAT2L_a213_seatMotorState 5 "UNDEFINED" 4 "CALIBRATING" 3 "RECALLING" 2 "MOVING_DOWN" 1 "MOVING_UP" 0 "STOPPED" ;
VAL_ 1336 VCSEAT2L_a213_seatSwitchBack 3 "FAULT" 2 "ON" 1 "OFF" 0 "SNA" ;
VAL_ 1336 VCSEAT2L_a213_seatSwitchForward 3 "FAULT" 2 "ON" 1 "OFF" 0 "SNA" ;
VAL_ 1336 VCSEAT2L_a214_seatMotorState 5 "UNDEFINED" 4 "CALIBRATING" 3 "RECALLING" 2 "MOVING_DOWN" 1 "MOVING_UP" 0 "STOPPED" ;
VAL_ 1336 VCSEAT2L_a215_seatMotorState 5 "UNDEFINED" 4 "CALIBRATING" 3 "RECALLING" 2 "MOVING_DOWN" 1 "MOVING_UP" 0 "STOPPED" ;
VAL_ 1336 VCSEAT2L_a224_seatMotorState 5 "UNDEFINED" 4 "CALIBRATING" 3 "RECALLING" 2 "MOVING_DOWN" 1 "MOVING_UP" 0 "STOPPED" ;
VAL_ 1336 VCSEAT2L_a224_seatSwitchBack 3 "FAULT" 2 "ON" 1 "OFF" 0 "SNA" ;
VAL_ 1336 VCSEAT2L_a224_seatSwitchForward 3 "FAULT" 2 "ON" 1 "OFF" 0 "SNA" ;
VAL_ 1336 VCSEAT2L_a225_seatMotorState 5 "UNDEFINED" 4 "CALIBRATING" 3 "RECALLING" 2 "MOVING_DOWN" 1 "MOVING_UP" 0 "STOPPED" ;
VAL_ 1336 VCSEAT2L_a225_seatSwitchBack 3 "FAULT" 2 "ON" 1 "OFF" 0 "SNA" ;
VAL_ 1336 VCSEAT2L_a225_seatSwitchForward 3 "FAULT" 2 "ON" 1 "OFF" 0 "SNA" ;
VAL_ 1336 VCSEAT2L_a228_seatMotorState 5 "UNDEFINED" 4 "CALIBRATING" 3 "RECALLING" 2 "MOVING_DOWN" 1 "MOVING_UP" 0 "STOPPED" ;
VAL_ 1336 VCSEAT2L_a228_seatSwitchBack 3 "FAULT" 2 "ON" 1 "OFF" 0 "SNA" ;
VAL_ 1336 VCSEAT2L_a228_seatSwitchForward 3 "FAULT" 2 "ON" 1 "OFF" 0 "SNA" ;
VAL_ 1336 VCSEAT2L_a229_seatMotorState 5 "UNDEFINED" 4 "CALIBRATING" 3 "RECALLING" 2 "MOVING_DOWN" 1 "MOVING_UP" 0 "STOPPED" ;
VAL_ 1336 VCSEAT2L_a229_seatSwitchBack 3 "FAULT" 2 "ON" 1 "OFF" 0 "SNA" ;
VAL_ 1336 VCSEAT2L_a229_seatSwitchForward 3 "FAULT" 2 "ON" 1 "OFF" 0 "SNA" ;
VAL_ 1336 VCSEAT2L_a232_seatMotorState 5 "UNDEFINED" 4 "CALIBRATING" 3 "RECALLING" 2 "MOVING_DOWN" 1 "MOVING_UP" 0 "STOPPED" ;
VAL_ 1336 VCSEAT2L_a232_seatSwitchBack 3 "FAULT" 2 "ON" 1 "OFF" 0 "SNA" ;
VAL_ 1336 VCSEAT2L_a232_seatSwitchForward 3 "FAULT" 2 "ON" 1 "OFF" 0 "SNA" ;
VAL_ 1336 VCSEAT2L_a233_seatMotorState 5 "UNDEFINED" 4 "CALIBRATING" 3 "RECALLING" 2 "MOVING_DOWN" 1 "MOVING_UP" 0 "STOPPED" ;
VAL_ 1336 VCSEAT2L_a233_seatSwitchBack 3 "FAULT" 2 "ON" 1 "OFF" 0 "SNA" ;
VAL_ 1336 VCSEAT2L_a233_seatSwitchForward 3 "FAULT" 2 "ON" 1 "OFF" 0 "SNA" ;
VAL_ 1336 VCSEAT2L_a251_seatMotorState 5 "UNDEFINED" 4 "CALIBRATING" 3 "RECALLING" 2 "MOVING_DOWN" 1 "MOVING_UP" 0 "STOPPED" ;
VAL_ 1336 VCSEAT2L_a251_seatSwitchBack 3 "FAULT" 2 "ON" 1 "OFF" 0 "SNA" ;
VAL_ 1336 VCSEAT2L_a251_seatSwitchForward 3 "FAULT" 2 "ON" 1 "OFF" 0 "SNA" ;
VAL_ 1336 VCSEAT2L_a252_seatMotorState 5 "UNDEFINED" 4 "CALIBRATING" 3 "RECALLING" 2 "MOVING_DOWN" 1 "MOVING_UP" 0 "STOPPED" ;
VAL_ 1336 VCSEAT2L_a252_seatSwitchBack 3 "FAULT" 2 "ON" 1 "OFF" 0 "SNA" ;
VAL_ 1336 VCSEAT2L_a252_seatSwitchForward 3 "FAULT" 2 "ON" 1 "OFF" 0 "SNA" ;
VAL_ 1336 VCSEAT2L_a260_seatStatePrev 5 "UNDEFINED" 4 "CALIBRATING" 3 "RECALLING" 2 "MOVING_DOWN" 1 "MOVING_UP" 0 "STOPPED" ;
VAL_ 1336 VCSEAT2L_a260_obstacleDetectReas 6 "HISTORY_BASED" 5 "SENSITIVE_CURRENT" 4 "ACCEL_LOOKBACK_ABS" 3 "MAX_SPEED_DIFF" 2 "SPEED_THRESHOLD" 1 "STALL_DETECTED" 0 "NONE" ;
VAL_ 1336 VCSEAT2L_a261_seatStatePrev 5 "UNDEFINED" 4 "CALIBRATING" 3 "RECALLING" 2 "MOVING_DOWN" 1 "MOVING_UP" 0 "STOPPED" ;
VAL_ 1336 VCSEAT2L_a261_obstacleDetectReas 6 "HISTORY_BASED" 5 "SENSITIVE_CURRENT" 4 "ACCEL_LOOKBACK_ABS" 3 "MAX_SPEED_DIFF" 2 "SPEED_THRESHOLD" 1 "STALL_DETECTED" 0 "NONE" ;
VAL_ 1336 VCSEAT2L_a263_seatMotorState 5 "UNDEFINED" 4 "CALIBRATING" 3 "RECALLING" 2 "MOVING_DOWN" 1 "MOVING_UP" 0 "STOPPED" ;
VAL_ 1336 VCSEAT2L_a264_seatMotorState 5 "UNDEFINED" 4 "CALIBRATING" 3 "RECALLING" 2 "MOVING_DOWN" 1 "MOVING_UP" 0 "STOPPED" ;
VAL_ 1336 VCSEAT2L_a267_seatMotorState 5 "UNDEFINED" 4 "CALIBRATING" 3 "RECALLING" 2 "MOVING_DOWN" 1 "MOVING_UP" 0 "STOPPED" ;
VAL_ 1336 VCSEAT2L_a268_seatMotorState 5 "UNDEFINED" 4 "CALIBRATING" 3 "RECALLING" 2 "MOVING_DOWN" 1 "MOVING_UP" 0 "STOPPED" ;
VAL_ 1336 VCSEAT2L_a270_seatState 15 "SNA" 12 "CALIBRATING_ABSOLUTE_SENSOR" 11 "CALIBRATING_ZERO_POSITION" 10 "WAITING_TO_CLEAR_FOR_UNFOLD" 9 "WAITING_TO_CLEAR_FOR_FOLD" 8 "MOVING_REARWARD_TO_POSITION" 7 "MOVING_FORWARD_TO_POSITION" 6 "UNFOLDING" 5 "FOLDING" 4 "ADJUSTING_REARWARD_FAST" 3 "ADJUSTING_FORWARD_FAST" 2 "ADJUSTING_REARWARD_COMFORT" 1 "ADJUSTING_FORWARD_COMFORT" 0 "STOPPED" ;
VAL_ 1336 VCSEAT2L_a270_motorType 1 "KEIPER" 0 "SHB_OR_UNKNOWN" ;
VAL_ 1336 VCSEAT2L_a270_absPosSensState 3 "DISCONNECTED" 2 "FORWARD" 1 "REARWARD" 0 "FAULTED" ;
VAL_ 1336 VCSEAT2L_a273_seatStatePrev 15 "SNA" 12 "CALIBRATING_ABSOLUTE_SENSOR" 11 "CALIBRATING_ZERO_POSITION" 10 "WAITING_TO_CLEAR_FOR_UNFOLD" 9 "WAITING_TO_CLEAR_FOR_FOLD" 8 "MOVING_REARWARD_TO_POSITION" 7 "MOVING_FORWARD_TO_POSITION" 6 "UNFOLDING" 5 "FOLDING" 4 "ADJUSTING_REARWARD_FAST" 3 "ADJUSTING_FORWARD_FAST" 2 "ADJUSTING_REARWARD_COMFORT" 1 "ADJUSTING_FORWARD_COMFORT" 0 "STOPPED" ;
VAL_ 1336 VCSEAT2L_a273_obstacleDetectReas 8 "MAX_SPEED_DIFF" 7 "SPEED_THRESHOLD" 6 "MEDIUM_CURRENT_THRESHOLD" 5 "ACCEL_LOOKBACK_COMP_ABS" 4 "ACCEL_LOOKBACK_UNCOMP_REL" 3 "ACCEL_LOOKBACK_UNCOMP_ABS" 2 "MOTOR_ENCODER_STALL" 1 "MOTOR_CURRENT_STALL" 0 "NONE" ;
VAL_ 1336 VCSEAT2L_a273_motorType 1 "KEIPER" 0 "SHB_OR_UNKNOWN" ;
VAL_ 1336 VCSEAT2L_a278_seatState 15 "SNA" 12 "CALIBRATING_ABSOLUTE_SENSOR" 11 "CALIBRATING_ZERO_POSITION" 10 "WAITING_TO_CLEAR_FOR_UNFOLD" 9 "WAITING_TO_CLEAR_FOR_FOLD" 8 "MOVING_REARWARD_TO_POSITION" 7 "MOVING_FORWARD_TO_POSITION" 6 "UNFOLDING" 5 "FOLDING" 4 "ADJUSTING_REARWARD_FAST" 3 "ADJUSTING_FORWARD_FAST" 2 "ADJUSTING_REARWARD_COMFORT" 1 "ADJUSTING_FORWARD_COMFORT" 0 "STOPPED" ;
VAL_ 1336 VCSEAT2L_a426_seatMotorState 5 "UNDEFINED" 4 "CALIBRATING" 3 "RECALLING" 2 "MOVING_DOWN" 1 "MOVING_UP" 0 "STOPPED" ;
VAL_ 1336 VCSEAT2L_a426_seatSwitchBack 3 "FAULT" 2 "ON" 1 "OFF" 0 "SNA" ;
VAL_ 1336 VCSEAT2L_a426_seatSwitchForward 3 "FAULT" 2 "ON" 1 "OFF" 0 "SNA" ;
VAL_ 1336 VCSEAT2L_a427_seatMotorState 5 "UNDEFINED" 4 "CALIBRATING" 3 "RECALLING" 2 "MOVING_DOWN" 1 "MOVING_UP" 0 "STOPPED" ;
VAL_ 1336 VCSEAT2L_a427_seatSwitchBack 3 "FAULT" 2 "ON" 1 "OFF" 0 "SNA" ;
VAL_ 1336 VCSEAT2L_a427_seatSwitchForward 3 "FAULT" 2 "ON" 1 "OFF" 0 "SNA" ;
VAL_ 1336 VCSEAT2L_a428_seatMotorState 5 "UNDEFINED" 4 "CALIBRATING" 3 "RECALLING" 2 "MOVING_DOWN" 1 "MOVING_UP" 0 "STOPPED" ;
VAL_ 1336 VCSEAT2L_a428_seatSwitchBack 3 "FAULT" 2 "ON" 1 "OFF" 0 "SNA" ;
VAL_ 1336 VCSEAT2L_a428_seatSwitchForward 3 "FAULT" 2 "ON" 1 "OFF" 0 "SNA" ;
VAL_ 1336 VCSEAT2L_a429_seatMotorState 5 "UNDEFINED" 4 "CALIBRATING" 3 "RECALLING" 2 "MOVING_DOWN" 1 "MOVING_UP" 0 "STOPPED" ;
VAL_ 1336 VCSEAT2L_a429_seatSwitchBack 3 "FAULT" 2 "ON" 1 "OFF" 0 "SNA" ;
VAL_ 1336 VCSEAT2L_a429_seatSwitchForward 3 "FAULT" 2 "ON" 1 "OFF" 0 "SNA" ;
